VERSION ""

NS_ :

BS_:

BU_: ESP dSpaceBox CALTOOL HED
VAL_TABLE_ Vtsig_BCC_ERRORS 2 "STORED" 1 "ACTIVE" 0 "NOT_ACTIVE" ;
VAL_TABLE_ DefaultValue -1 "NO_CONTEXT" ;
VAL_TABLE_ Wakeup_Mode 1 "TRUE" 0 "FALSE" ;
VAL_TABLE_ SW_MODE 2 "Shutdown" 1 "Operational Mode" ;
VAL_TABLE_ Balancing_Active 1 "TRUE" 0 "FALSE" ;
VAL_TABLE_ Balancing_Enable 1 "TRUE" 0 "FALSE" ;
VAL_TABLE_ Balancing_Request 1 "ON" 0 "OFF" ;
VAL_TABLE_ Flash_Status 1 "FLASH MODE" 0 "NORMAL MODE" ;
VAL_TABLE_ Flash_Request 3 "EXIT" 2 "TRANSFER" 1 "START" 0 "NOT REQUESTED" ;
VAL_TABLE_ Function 1 "ENABLE" 0 "DISABLE" ;
VAL_TABLE_ Error 1 "ACTIVE" 0 "NOT ACTIVE" ;
VAL_TABLE_ Balancing_Status 3 "RESERVED" 2 "CHARGING" 1 "DISCHARGING" 0 "OFF" ;

BO_ 11 AI_SOC_ESP: 8 ESP
 SG_ AI_SOC_ESP : 0|16@1+ (0.01,0) [0|100] "%"  HED

BO_ 10 AI_SOH_ESP: 8 ESP
 SG_ AI_SOH_ESP : 0|16@1+ (0.01,0) [0|100] "%"  HED

BO_ 18 VCU_BatInfo_2: 8 HED
 SG_ Cell_Current : 0|16@1- (0.0005,0) [-16|16] "V"  dSpaceBox

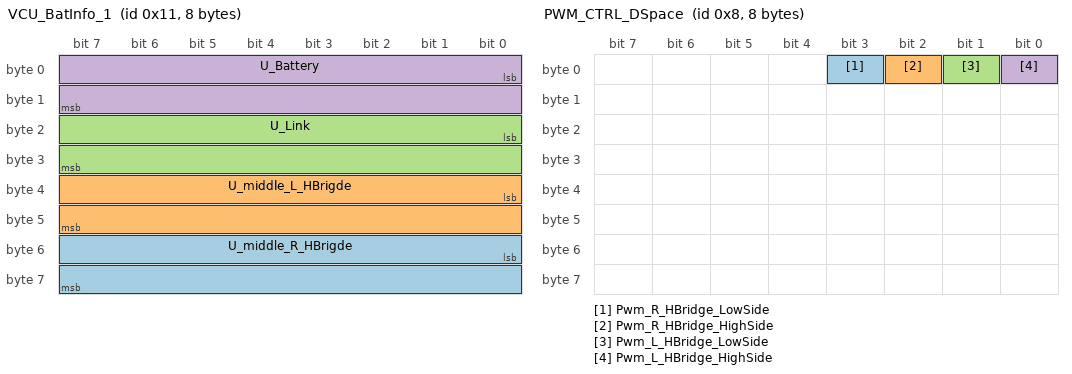
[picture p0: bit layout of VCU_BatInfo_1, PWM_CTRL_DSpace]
BO_ 17 VCU_BatInfo_1: 8 HED
 SG_ U_middle_R_HBrigde : 48|16@1+ (0.001,0) [0|15] "V"  dSpaceBox
 SG_ U_middle_L_HBrigde : 32|16@1+ (0.001,0) [0|15] "V"  dSpaceBox
 SG_ U_Link : 16|16@1+ (0.001,0) [0|15] "V"  dSpaceBox
 SG_ U_Battery : 0|16@1+ (0.001,0) [0|5] ""  dSpaceBox

BO_ 8 PWM_CTRL_DSpace: 8 dSpaceBox
 SG_ Pwm_R_HBridge_LowSide : 3|1@1+ (1,0) [0|1] ""  HED
 SG_ Pwm_R_HBridge_HighSide : 2|1@1+ (1,0) [0|1] ""  HED
 SG_ Pwm_L_HBridge_LowSide : 1|1@1+ (1,0) [0|1] ""  HED
 SG_ Pwm_L_HBridge_HighSide : 0|1@1+ (1,0) [0|1] ""  HED

BO_ 7 AI_SOH_SOC_TAB: 8 CALTOOL
 SG_ AI_SOH_TAB : 16|16@1+ (0.01,0) [0|100] "%"  HED
 SG_ AI_SOC_TAB : 0|16@1+ (0.01,0) [0|100] "%"  HED

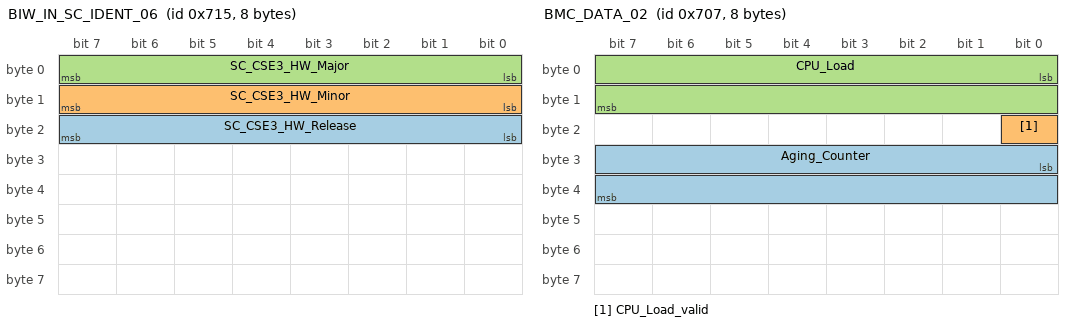
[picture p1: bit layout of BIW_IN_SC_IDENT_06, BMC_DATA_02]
BO_ 1813 BIW_IN_SC_IDENT_06: 8 HED
 SG_ SC_CSE3_HW_Release : 16|8@1+ (1,0) [0|254] ""  CALTOOL
 SG_ SC_CSE3_HW_Minor : 8|8@1+ (1,0) [0|254] ""  CALTOOL
 SG_ SC_CSE3_HW_Major : 0|8@1+ (1,0) [0|254] ""  CALTOOL

BO_ 528 BIW_IN_SC_ERRORS_11: 8 HED
 SG_ SC_ERR_Reserved_11_12 : 60|3@1+ (1,0) [0|0] ""  CALTOOL
 SG_ SC_ERR_Reserved_11_11 : 57|3@1+ (1,0) [0|0] ""  CALTOOL
 SG_ SC_ERR_Reserved_11_10 : 54|3@1+ (1,0) [0|0] ""  CALTOOL
 SG_ SC_ERR_Reserved_11_09 : 51|3@1+ (1,0) [0|0] ""  CALTOOL
 SG_ SC_ERR_Reserved_11_08 : 48|3@1+ (1,0) [0|0] ""  CALTOOL
 SG_ SC_ERR_Reserved_11_07 : 45|3@1+ (1,0) [0|0] ""  CALTOOL
 SG_ SC_ERR_Reserved_11_06 : 42|3@1+ (1,0) [0|0] ""  CALTOOL
 SG_ SC_ERR_Reserved_11_05 : 39|3@1+ (1,0) [0|0] ""  CALTOOL
 SG_ SC_ERR_Reserved_11_04 : 36|3@1+ (1,0) [0|0] ""  CALTOOL
 SG_ SC_ERR_Reserved_11_03 : 33|3@1+ (1,0) [0|0] ""  CALTOOL
 SG_ SC_ERR_Reserved_11_02 : 30|3@1+ (1,0) [0|0] ""  CALTOOL
 SG_ SC_ERR_Reserved_11_01 : 27|3@1+ (1,0) [0|0] ""  CALTOOL
 SG_ SC_ERR_CSE3_PCB_Temp2_RNGL : 24|3@1+ (1,0) [0|0] ""  CALTOOL
 SG_ SC_ERR_CSE3_PCB_Temp2_RNGH : 21|3@1+ (1,0) [0|0] ""  CALTOOL
 SG_ SC_ERR_CSE3_PCB_Temp2_High : 18|3@1+ (1,0) [0|0] ""  CALTOOL
 SG_ SC_ERR_CSE3_PCB_Temp1_RNGL : 15|3@1+ (1,0) [0|0] ""  CALTOOL
 SG_ SC_ERR_CSE3_PCB_Temp1_RNGH : 12|3@1+ (1,0) [0|0] ""  CALTOOL
 SG_ SC_ERR_CSE3_PCB_Temp1_High : 9|3@1+ (1,0) [0|0] ""  CALTOOL
 SG_ SC_ERR_CSE3_Fault_Line : 6|3@1+ (1,0) [0|0] ""  CALTOOL
 SG_ SC_ERR_CSE3_Daisy_Chain : 3|3@1+ (1,0) [0|0] ""  CALTOOL
 SG_ SC_ERR_CSE3_Com_TOut : 0|3@1+ (1,0) [0|0] ""  CALTOOL

BO_ 1799 BMC_DATA_02: 8 HED
 SG_ Aging_Counter : 24|16@1+ (1,0) [0|0] ""  CALTOOL
 SG_ CPU_Load_valid : 16|1@1+ (1,0) [0|0] ""  CALTOOL
 SG_ CPU_Load : 0|16@1+ (0.1,0) [0|0] "%"  CALTOOL

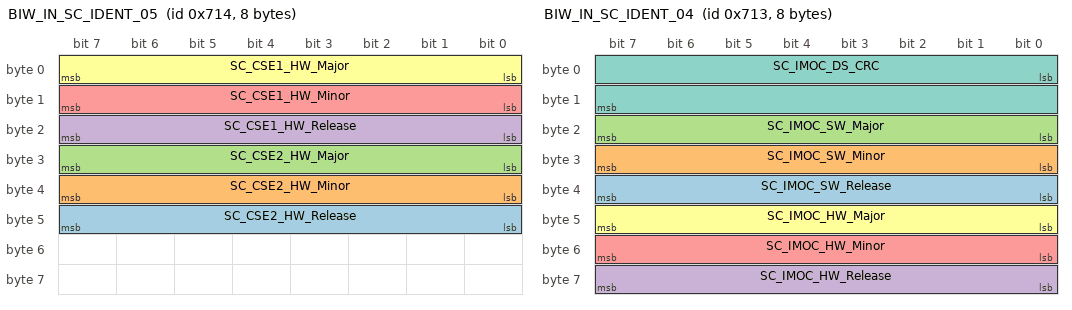
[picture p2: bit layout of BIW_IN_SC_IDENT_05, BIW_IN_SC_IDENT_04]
BO_ 1812 BIW_IN_SC_IDENT_05: 8 HED
 SG_ SC_CSE2_HW_Release : 40|8@1+ (1,0) [0|254] ""  CALTOOL
 SG_ SC_CSE2_HW_Minor : 32|8@1+ (1,0) [0|254] ""  CALTOOL
 SG_ SC_CSE2_HW_Major : 24|8@1+ (1,0) [0|254] ""  CALTOOL
 SG_ SC_CSE1_HW_Release : 16|8@1+ (1,0) [0|254] ""  CALTOOL
 SG_ SC_CSE1_HW_Minor : 8|8@1+ (1,0) [0|254] ""  CALTOOL
 SG_ SC_CSE1_HW_Major : 0|8@1+ (1,0) [0|254] ""  CALTOOL

BO_ 1811 BIW_IN_SC_IDENT_04: 8 HED
 SG_ SC_IMOC_SW_Release : 32|8@1+ (1,0) [0|255] ""  CALTOOL
 SG_ SC_IMOC_SW_Minor : 24|8@1+ (1,0) [0|255] ""  CALTOOL
 SG_ SC_IMOC_SW_Major : 16|8@1+ (1,0) [0|255] ""  CALTOOL
 SG_ SC_IMOC_HW_Release : 56|8@1+ (1,0) [0|254] ""  CALTOOL
 SG_ SC_IMOC_HW_Minor : 48|8@1+ (1,0) [0|254] ""  CALTOOL
 SG_ SC_IMOC_HW_Major : 40|8@1+ (1,0) [0|254] ""  CALTOOL
 SG_ SC_IMOC_DS_CRC : 0|16@1+ (1,0) [0|65534] ""  CALTOOL

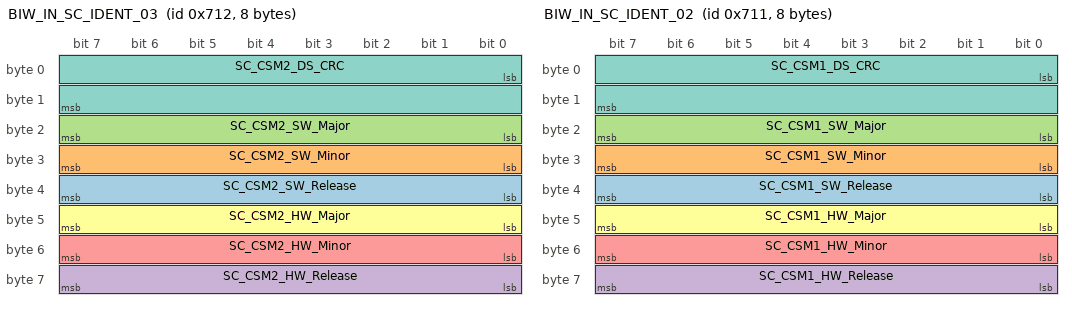
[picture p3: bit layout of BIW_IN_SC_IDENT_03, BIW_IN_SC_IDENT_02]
BO_ 1810 BIW_IN_SC_IDENT_03: 8 HED
 SG_ SC_CSM2_SW_Release : 32|8@1+ (1,0) [0|254] ""  CALTOOL
 SG_ SC_CSM2_SW_Minor : 24|8@1+ (1,0) [0|254] ""  CALTOOL
 SG_ SC_CSM2_SW_Major : 16|8@1+ (1,0) [0|254] ""  CALTOOL
 SG_ SC_CSM2_HW_Release : 56|8@1+ (1,0) [0|254] ""  CALTOOL
 SG_ SC_CSM2_HW_Minor : 48|8@1+ (1,0) [0|254] ""  CALTOOL
 SG_ SC_CSM2_HW_Major : 40|8@1+ (1,0) [0|254] ""  CALTOOL
 SG_ SC_CSM2_DS_CRC : 0|16@1+ (1,0) [0|65534] ""  CALTOOL

BO_ 1809 BIW_IN_SC_IDENT_02: 8 HED
 SG_ SC_CSM1_SW_Release : 32|8@1+ (1,0) [0|254] ""  CALTOOL
 SG_ SC_CSM1_SW_Minor : 24|8@1+ (1,0) [0|254] ""  CALTOOL
 SG_ SC_CSM1_SW_Major : 16|8@1+ (1,0) [0|254] ""  CALTOOL
 SG_ SC_CSM1_HW_Release : 56|8@1+ (1,0) [0|254] ""  CALTOOL
 SG_ SC_CSM1_HW_Minor : 48|8@1+ (1,0) [0|254] ""  CALTOOL
 SG_ SC_CSM1_HW_Major : 40|8@1+ (1,0) [0|254] ""  CALTOOL
 SG_ SC_CSM1_DS_CRC : 0|16@1+ (1,0) [0|65534] ""  CALTOOL

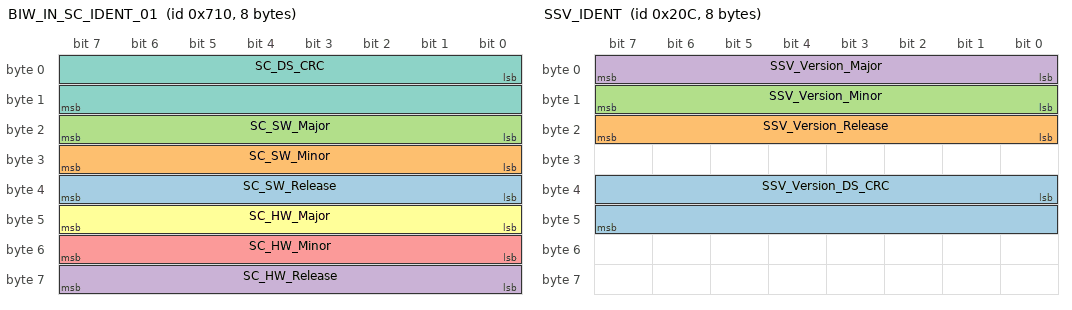
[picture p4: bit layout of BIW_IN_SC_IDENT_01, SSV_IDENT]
BO_ 1808 BIW_IN_SC_IDENT_01: 8 HED
 SG_ SC_SW_Release : 32|8@1+ (1,0) [0|255] ""  CALTOOL
 SG_ SC_SW_Minor : 24|8@1+ (1,0) [0|255] ""  CALTOOL
 SG_ SC_SW_Major : 16|8@1+ (1,0) [0|255] ""  CALTOOL
 SG_ SC_HW_Release : 56|8@1+ (1,0) [0|255] ""  CALTOOL
 SG_ SC_HW_Minor : 48|8@1+ (1,0) [0|255] ""  CALTOOL
 SG_ SC_HW_Major : 40|8@1+ (1,0) [0|255] ""  CALTOOL
 SG_ SC_DS_CRC : 0|16@1+ (1,0) [0|0] ""  CALTOOL

BO_ 521 BIW_IN_SC_ERRORS_10: 8 HED
 SG_ SC_ERR_Reserved_10_07 : 60|3@1+ (1,0) [0|0] ""  CALTOOL
 SG_ SC_ERR_Reserved_10_06 : 57|3@1+ (1,0) [0|0] ""  CALTOOL
 SG_ SC_ERR_Reserved_10_05 : 54|3@1+ (1,0) [0|0] ""  CALTOOL
 SG_ SC_ERR_Reserved_10_04 : 51|3@1+ (1,0) [0|0] ""  CALTOOL
 SG_ SC_ERR_Reserved_10_03 : 48|3@1+ (1,0) [0|0] ""  CALTOOL
 SG_ SC_ERR_Reserved_10_02 : 45|3@1+ (1,0) [0|0] ""  CALTOOL
 SG_ SC_ERR_Reserved_10_01 : 42|3@1+ (1,0) [0|0] ""  CALTOOL
 SG_ SC_ERR_FUSI_FSG_01 : 15|3@1+ (1,0) [0|0] ""  CALTOOL
 SG_ SC_ERR_FUSI_FSG_02 : 18|3@1+ (1,0) [0|0] ""  CALTOOL
 SG_ SC_ERR_FUSI_FSG_03 : 21|3@1+ (1,0) [0|0] ""  CALTOOL
 SG_ SC_ERR_FUSI_FSG_04 : 24|3@1+ (1,0) [0|0] ""  CALTOOL
 SG_ SC_ERR_FUSI_FSG_05 : 27|3@1+ (1,0) [0|0] ""  CALTOOL
 SG_ SC_ERR_FUSI_FSG_06 : 30|3@1+ (1,0) [0|0] ""  CALTOOL
 SG_ SC_ERR_FUSI_FSG_07 : 33|3@1+ (1,0) [0|0] ""  CALTOOL
 SG_ SC_ERR_FUSI_FSG_08 : 36|3@1+ (1,0) [0|0] ""  CALTOOL
 SG_ SC_ERR_FUSI_FSG_09 : 39|3@1+ (1,0) [0|0] ""  CALTOOL
 SG_ SC_ERR_SC_ROM : 12|3@1+ (1,0) [0|0] ""  CALTOOL
 SG_ SC_ERR_SC_RAM : 9|3@1+ (1,0) [0|0] ""  CALTOOL
 SG_ SC_ERR_SC_NVRAM : 6|3@1+ (1,0) [0|0] ""  CALTOOL
 SG_ SC_ERR_IMOC_ROM : 3|3@1+ (1,0) [0|0] ""  CALTOOL
 SG_ SC_ERR_IMOC_RAM : 0|3@1+ (1,0) [0|0] ""  CALTOOL

BO_ 520 BIW_IN_SC_ERRORS_09: 8 HED
 SG_ SC_ERR_Reserved_09_14 : 60|3@1+ (1,0) [0|0] ""  CALTOOL
 SG_ SC_ERR_Reserved_09_13 : 57|3@1+ (1,0) [0|0] ""  CALTOOL
 SG_ SC_ERR_Reserved_09_12 : 54|3@1+ (1,0) [0|0] ""  CALTOOL
 SG_ SC_ERR_Reserved_09_11 : 51|3@1+ (1,0) [0|0] ""  CALTOOL
 SG_ SC_ERR_Reserved_09_10 : 48|3@1+ (1,0) [0|0] ""  CALTOOL
 SG_ SC_ERR_Reserved_09_09 : 45|3@1+ (1,0) [0|0] ""  CALTOOL
 SG_ SC_ERR_Reserved_09_08 : 42|3@1+ (1,0) [0|0] ""  CALTOOL
 SG_ SC_ERR_Reserved_09_07 : 39|3@1+ (1,0) [0|0] ""  CALTOOL
 SG_ SC_ERR_Reserved_09_06 : 36|3@1+ (1,0) [0|0] ""  CALTOOL
 SG_ SC_ERR_Reserved_09_05 : 33|3@1+ (1,0) [0|0] ""  CALTOOL
 SG_ SC_ERR_Reserved_09_04 : 30|3@1+ (1,0) [0|0] ""  CALTOOL
 SG_ SC_ERR_Reserved_09_03 : 27|3@1+ (1,0) [0|0] ""  CALTOOL
 SG_ SC_ERR_Reserved_09_02 : 24|3@1+ (1,0) [0|0] ""  CALTOOL
 SG_ SC_ERR_Reserved_09_01 : 21|3@1+ (1,0) [0|0] ""  CALTOOL
 SG_ SC_ERR_ISO_Meas_Selftest : 18|3@1+ (1,0) [0|0] ""  CALTOOL
 SG_ SC_ERR_ISO_Int_Lvl3 : 15|3@1+ (1,0) [0|0] ""  CALTOOL
 SG_ SC_ERR_ISO_Int_Lvl2 : 12|3@1+ (1,0) [0|0] ""  CALTOOL
 SG_ SC_ERR_ISO_Int_Lvl1 : 9|3@1+ (1,0) [0|0] ""  CALTOOL
 SG_ SC_ERR_ISO_Ext_Lvl3 : 6|3@1+ (1,0) [0|0] ""  CALTOOL
 SG_ SC_ERR_ISO_Ext_Lvl2 : 3|3@1+ (1,0) [0|0] ""  CALTOOL
 SG_ SC_ERR_ISO_Ext_Lvl1 : 0|3@1+ (1,0) [0|0] ""  CALTOOL

BO_ 519 BIW_IN_SC_ERRORS_08: 8 HED
 SG_ SC_ERR_Reserved_08_02 : 60|3@1+ (1,0) [0|0] ""  CALTOOL
 SG_ SC_ERR_Reserved_08_01 : 57|3@1+ (1,0) [0|0] ""  CALTOOL
 SG_ SC_ERR_CAN_Sc_Meas_Busoff : 54|3@1+ (1,0) [0|0] ""  CALTOOL
 SG_ SC_ERR_CAN_Data_Busoff : 51|3@1+ (1,0) [0|0] ""  CALTOOL
 SG_ SC_ERR_CAN_PNHV_Stat_AR2_TOut : 48|3@1+ (1,0) [0|0] ""  CALTOOL
 SG_ SC_ERR_CAN_OBL_Rq_AR2_TOut : 42|3@1+ (1,0) [0|0] ""  CALTOOL
 SG_ SC_ERR_CAN_LBC_CANHS_R_03_TOut : 45|3@1+ (1,0) [0|0] ""  CALTOOL
 SG_ SC_ERR_CAN_LBC_CANHS_R_02_TOut : 39|3@1+ (1,0) [0|0] ""  CALTOOL
 SG_ SC_ERR_VCC3_Vltg_Low : 36|3@1+ (1,0) [0|0] ""  CALTOOL
 SG_ SC_ERR_VCC3_Vltg_High : 33|3@1+ (1,0) [0|0] ""  CALTOOL
 SG_ SC_ERR_VCC2_Vltg_Low : 30|3@1+ (1,0) [0|0] ""  CALTOOL
 SG_ SC_ERR_VCC2_Vltg_High : 27|3@1+ (1,0) [0|0] ""  CALTOOL
 SG_ SC_ERR_VCC1_Vltg_Low : 24|3@1+ (1,0) [0|0] ""  CALTOOL
 SG_ SC_ERR_VCC1_Vltg_High : 21|3@1+ (1,0) [0|0] ""  CALTOOL
 SG_ SC_ERR_KL30c_Vltg_Low : 18|3@1+ (1,0) [0|0] ""  CALTOOL
 SG_ SC_ERR_KL30c_Vltg_High : 15|3@1+ (1,0) [0|0] ""  CALTOOL
 SG_ SC_ERR_KL30c_Trgd : 12|3@1+ (1,0) [0|0] ""  CALTOOL
 SG_ SC_ERR_KL30_Vltg_Low : 9|3@1+ (1,0) [0|0] ""  CALTOOL
 SG_ SC_ERR_KL30_Vltg_High : 6|3@1+ (1,0) [0|0] ""  CALTOOL
 SG_ SC_ERR_KL15_Vltg_Plaus : 3|3@1+ (1,0) [0|0] ""  CALTOOL
 SG_ SC_ERR_KL15_Vltg_High : 0|3@1+ (1,0) [0|0] ""  CALTOOL

BO_ 518 BIW_IN_SC_ERRORS_07: 8 HED
 SG_ SC_ERR_Reserved_07_05 : 60|3@1+ (1,0) [0|0] ""  CALTOOL
 SG_ SC_ERR_Reserved_07_04 : 57|3@1+ (1,0) [0|0] ""  CALTOOL
 SG_ SC_ERR_Reserved_07_03 : 54|3@1+ (1,0) [0|0] ""  CALTOOL
 SG_ SC_ERR_Reserved_07_02 : 51|3@1+ (1,0) [0|0] ""  CALTOOL
 SG_ SC_ERR_Reserved_07_01 : 48|3@1+ (1,0) [0|0] ""  CALTOOL
 SG_ SC_ERR_INTLK2_OL : 45|3@1+ (1,0) [0|0] ""  CALTOOL
 SG_ SC_ERR_INTLK1_OL : 42|3@1+ (1,0) [0|0] ""  CALTOOL
 SG_ SC_ERR_INTLK2_Vcc_Low : 39|3@1+ (1,0) [0|0] ""  CALTOOL
 SG_ SC_ERR_INTLK2_Vcc_High : 36|3@1+ (1,0) [0|0] ""  CALTOOL
 SG_ SC_ERR_INTLK2_SCG : 33|3@1+ (1,0) [0|0] ""  CALTOOL
 SG_ SC_ERR_INTLK2_SCB : 30|3@1+ (1,0) [0|0] ""  CALTOOL
 SG_ SC_ERR_INTLK2_Gen_defect : 27|3@1+ (1,0) [0|0] ""  CALTOOL
 SG_ SC_ERR_INTLK2_Frequency : 24|3@1+ (1,0) [0|0] ""  CALTOOL
 SG_ SC_ERR_INTLK2_Duty_Cycle : 21|3@1+ (1,0) [0|0] ""  CALTOOL
 SG_ SC_ERR_INTLK1_Vcc_Low : 18|3@1+ (1,0) [0|0] ""  CALTOOL
 SG_ SC_ERR_INTLK1_Vcc_High : 15|3@1+ (1,0) [0|0] ""  CALTOOL
 SG_ SC_ERR_INTLK1_SCG : 12|3@1+ (1,0) [0|0] ""  CALTOOL
 SG_ SC_ERR_INTLK1_SCB : 9|3@1+ (1,0) [0|0] ""  CALTOOL
 SG_ SC_ERR_INTLK1_Gen_defect : 6|3@1+ (1,0) [0|0] ""  CALTOOL
 SG_ SC_ERR_INTLK1_Frequency : 3|3@1+ (1,0) [0|0] ""  CALTOOL
 SG_ SC_ERR_INTLK1_Duty_Cycle : 0|3@1+ (1,0) [0|0] ""  CALTOOL

BO_ 517 BIW_IN_SC_ERRORS_06: 8 HED
 SG_ SC_ERR_Reserved_06_03 : 57|3@1+ (1,0) [0|0] ""  CALTOOL
 SG_ SC_ERR_Reserved_06_02 : 54|3@1+ (1,0) [0|0] ""  CALTOOL
 SG_ SC_ERR_Reserved_06_01 : 51|3@1+ (1,0) [0|0] ""  CALTOOL
 SG_ SC_ERR_MSW_Pre_Temp : 48|3@1+ (1,0) [0|0] ""  CALTOOL
 SG_ SC_ERR_MSW_LnkVltg_High : 45|3@1+ (1,0) [0|0] ""  CALTOOL
 SG_ SC_ERR_MSW_Vltg_Diff : 42|3@1+ (1,0) [0|0] ""  CALTOOL
 SG_ SC_ERR_MSW_Pre_Time : 39|3@1+ (1,0) [0|0] ""  CALTOOL
 SG_ SC_ERR_MSW_Pre_Crnt : 36|3@1+ (1,0) [0|0] ""  CALTOOL
 SG_ SC_ERR_MSW_Pre_Stuck_Opn : 33|3@1+ (1,0) [0|0] ""  CALTOOL
 SG_ SC_ERR_MSW_Pre_Stuck_Cls : 30|3@1+ (1,0) [0|0] ""  CALTOOL
 SG_ SC_ERR_MSW_Plus_Stuck_Opn : 27|3@1+ (1,0) [0|0] ""  CALTOOL
 SG_ SC_ERR_MSW_Plus_Stuck_Cls : 24|3@1+ (1,0) [0|0] ""  CALTOOL
 SG_ SC_ERR_MSW_Minus_Stuck_Opn : 21|3@1+ (1,0) [0|0] ""  CALTOOL
 SG_ SC_ERR_MSW_Minus_Stuck_Cls : 18|3@1+ (1,0) [0|0] ""  CALTOOL
 SG_ SC_ERR_MSW_Pre_Ls_SCG : 15|3@1+ (1,0) [0|0] ""  CALTOOL
 SG_ SC_ERR_MSW_Pre_Ls_SCB : 12|3@1+ (1,0) [0|0] ""  CALTOOL
 SG_ SC_ERR_MSW_Pre_Ls_OL : 9|3@1+ (1,0) [0|0] ""  CALTOOL
 SG_ SC_ERR_MSW_Pre_Hs_SCG : 6|3@1+ (1,0) [0|0] ""  CALTOOL
 SG_ SC_ERR_MSW_Pre_Hs_SCB : 3|3@1+ (1,0) [0|0] ""  CALTOOL
 SG_ SC_ERR_MSW_Pre_Hs_OL : 0|3@1+ (1,0) [0|0] ""  CALTOOL

BO_ 516 BIW_IN_SC_ERRORS_05: 8 HED
 SG_ SC_ERR_Reserved_05_03 : 60|3@1+ (1,0) [0|0] ""  CALTOOL
 SG_ SC_ERR_Reserved_05_02 : 57|3@1+ (1,0) [0|0] ""  CALTOOL
 SG_ SC_ERR_Reserved_05_01 : 54|3@1+ (1,0) [0|0] ""  CALTOOL
 SG_ SC_ERR_MSW_Plus_Ls_SCG : 51|3@1+ (1,0) [0|0] ""  CALTOOL
 SG_ SC_ERR_MSW_Plus_Ls_SCB : 48|3@1+ (1,0) [0|0] ""  CALTOOL
 SG_ SC_ERR_MSW_Plus_Ls_OL : 39|3@1+ (1,0) [0|0] ""  CALTOOL
 SG_ SC_ERR_MSW_Plus_Hs_SCG : 18|3@1+ (1,0) [0|0] ""  CALTOOL
 SG_ SC_ERR_MSW_Plus_Hs_SCB : 45|3@1+ (1,0) [0|0] ""  CALTOOL
 SG_ SC_ERR_MSW_Plus_Hs_OL : 42|3@1+ (1,0) [0|0] ""  CALTOOL
 SG_ SC_ERR_MSW_Minus_Ls_SCG : 36|3@1+ (1,0) [0|0] ""  CALTOOL
 SG_ SC_ERR_MSW_Minus_Ls_SCB : 33|3@1+ (1,0) [0|0] ""  CALTOOL
 SG_ SC_ERR_MSW_Minus_Ls_OL : 30|3@1+ (1,0) [0|0] ""  CALTOOL
 SG_ SC_ERR_MSW_Minus_Hs_SCG : 27|3@1+ (1,0) [0|0] ""  CALTOOL
 SG_ SC_ERR_MSW_Minus_Hs_SCB : 24|3@1+ (1,0) [0|0] ""  CALTOOL
 SG_ SC_ERR_MSW_Minus_Hs_OL : 21|3@1+ (1,0) [0|0] ""  CALTOOL
 SG_ SC_ERR_MSW_Aging_Pre_Warn : 15|3@1+ (1,0) [0|0] ""  CALTOOL
 SG_ SC_ERR_MSW_Aging_Pre : 12|3@1+ (1,0) [0|0] ""  CALTOOL
 SG_ SC_ERR_MSW_Aging_Plus_Warn : 9|3@1+ (1,0) [0|0] ""  CALTOOL
 SG_ SC_ERR_MSW_Aging_Plus : 6|3@1+ (1,0) [0|0] ""  CALTOOL
 SG_ SC_ERR_MSW_Aging_Minus_Warn : 3|3@1+ (1,0) [0|0] ""  CALTOOL
 SG_ SC_ERR_MSW_Aging_Minus : 0|3@1+ (1,0) [0|0] ""  CALTOOL

BO_ 515 BIW_IN_SC_ERRORS_04: 8 HED
 SG_ SC_ERR_Reserved_04_03 : 60|3@1+ (1,0) [0|0] ""  CALTOOL
 SG_ SC_ERR_Reserved_04_02 : 57|3@1+ (1,0) [0|0] ""  CALTOOL
 SG_ SC_ERR_Reserved_04_01 : 54|3@1+ (1,0) [0|0] ""  CALTOOL
 SG_ SC_ERR_CSE1_PCB_Temp2_High : 24|3@1+ (1,0) [0|0] ""  CALTOOL
 SG_ SC_ERR_CSE2_PCB_Temp2_RNGL : 48|3@1+ (1,0) [0|0] ""  CALTOOL
 SG_ SC_ERR_CSE2_PCB_Temp2_RNGH : 51|3@1+ (1,0) [0|0] ""  CALTOOL
 SG_ SC_ERR_CSE2_PCB_Temp2_High : 45|3@1+ (1,0) [0|0] ""  CALTOOL
 SG_ SC_ERR_CSE2_PCB_Temp1_RNGL : 42|3@1+ (1,0) [0|0] ""  CALTOOL
 SG_ SC_ERR_CSE2_PCB_Temp1_RNGH : 39|3@1+ (1,0) [0|0] ""  CALTOOL
 SG_ SC_ERR_CSE2_PCB_Temp1_High : 36|3@1+ (1,0) [0|0] ""  CALTOOL
 SG_ SC_ERR_CSE2_Fault_Line : 33|3@1+ (1,0) [0|0] ""  CALTOOL
 SG_ SC_ERR_CSE2_Daisy_Chain : 30|3@1+ (1,0) [0|0] ""  CALTOOL
 SG_ SC_ERR_CSE2_Com_TOut : 27|3@1+ (1,0) [0|0] ""  CALTOOL
 SG_ SC_ERR_CSE1_PCB_Temp2_RNGL : 21|3@1+ (1,0) [0|0] ""  CALTOOL
 SG_ SC_ERR_CSE1_PCB_Temp2_RNGH : 18|3@1+ (1,0) [0|0] ""  CALTOOL
 SG_ SC_ERR_CSE1_PCB_Temp1_RNGL : 15|3@1+ (1,0) [0|0] ""  CALTOOL
 SG_ SC_ERR_CSE1_PCB_Temp1_RNGH : 12|3@1+ (1,0) [0|0] ""  CALTOOL
 SG_ SC_ERR_CSE1_PCB_Temp1_High : 9|3@1+ (1,0) [0|0] ""  CALTOOL
 SG_ SC_ERR_CSE1_Fault_Line : 6|3@1+ (1,0) [0|0] ""  CALTOOL
 SG_ SC_ERR_CSE1_Daisy_Chain : 3|3@1+ (1,0) [0|0] ""  CALTOOL
 SG_ SC_ERR_CSE1_Com_TOut : 0|3@1+ (1,0) [0|0] ""  CALTOOL

BO_ 514 BIW_IN_SC_ERRORS_03: 8 HED
 SG_ SC_ERR_FUSE1_Pack_RNGL : 9|3@1+ (1,0) [0|0] ""  CALTOOL
 SG_ SC_ERR_FUSE1_Pack_RNGH : 12|3@1+ (1,0) [0|0] ""  CALTOOL
 SG_ SC_ERR_FUSE1_Pack_OL : 3|3@1+ (1,0) [0|0] ""  CALTOOL
 SG_ SC_ERR_FUSE1_Link_RNGL : 15|3@1+ (1,0) [0|0] ""  CALTOOL
 SG_ SC_ERR_FUSE1_Link_RNGH : 18|3@1+ (1,0) [0|0] ""  CALTOOL
 SG_ SC_ERR_FUSE1_Link_OL : 6|3@1+ (1,0) [0|0] ""  CALTOOL
 SG_ SC_ERR_FUSE1_Blown : 0|3@1+ (1,0) [0|0] ""  CALTOOL
 SG_ SC_ERR_PCK_Vltg_RNGL : 45|3@1+ (1,0) [0|0] ""  CALTOOL
 SG_ SC_ERR_PCK_Vltg_RNGH : 48|3@1+ (1,0) [0|0] ""  CALTOOL
 SG_ SC_ERR_PCK_Vltg_Plaus : 51|3@1+ (1,0) [0|0] ""  CALTOOL
 SG_ SC_ERR_PCK_Vltg_OL : 54|3@1+ (1,0) [0|0] ""  CALTOOL
 SG_ SC_ERR_LNK_Vltg_RNGL : 57|3@1+ (1,0) [0|0] ""  CALTOOL
 SG_ SC_ERR_LNK_Vltg_RNGH : 60|3@1+ (1,0) [0|0] ""  CALTOOL
 SG_ SC_ERR_LNK_Vltg_OL : 42|3@1+ (1,0) [0|0] ""  CALTOOL
 SG_ SC_ERR_FUSE2_Pack_RNGL : 30|3@1+ (1,0) [0|0] ""  CALTOOL
 SG_ SC_ERR_FUSE2_Pack_RNGH : 33|3@1+ (1,0) [0|0] ""  CALTOOL
 SG_ SC_ERR_FUSE2_Pack_OL : 24|3@1+ (1,0) [0|0] ""  CALTOOL
 SG_ SC_ERR_FUSE2_Link_RNGL : 36|3@1+ (1,0) [0|0] ""  CALTOOL
 SG_ SC_ERR_FUSE2_Link_RNGH : 39|3@1+ (1,0) [0|0] ""  CALTOOL
 SG_ SC_ERR_FUSE2_Link_OL : 27|3@1+ (1,0) [0|0] ""  CALTOOL
 SG_ SC_ERR_FUSE2_Blown : 21|3@1+ (1,0) [0|0] ""  CALTOOL

BO_ 513 BIW_IN_SC_ERRORS_02: 8 HED
 SG_ SC_ERR_Reserved_02_04 : 60|3@1+ (1,0) [0|0] ""  CALTOOL
 SG_ SC_ERR_Reserved_02_03 : 57|3@1+ (1,0) [0|0] ""  CALTOOL
 SG_ SC_ERR_Reserved_02_02 : 54|3@1+ (1,0) [0|0] ""  CALTOOL
 SG_ SC_ERR_Reserved_02_01 : 51|3@1+ (1,0) [0|0] ""  CALTOOL
 SG_ SC_ERR_CSM1_Temp_High : 15|3@1+ (1,0) [0|0] ""  CALTOOL
 SG_ SC_ERR_CSM1_ROM : 42|3@1+ (1,0) [0|0] ""  CALTOOL
 SG_ SC_ERR_CSM1_FUSI_CrntDischrgHigh : 12|3@1+ (1,0) [0|0] ""  CALTOOL
 SG_ SC_ERR_CSM1_FUSI_Crnt_Chrg_High : 9|3@1+ (1,0) [0|0] ""  CALTOOL
 SG_ SC_ERR_CSM1_Crnt_Dischrg_RNGL : 6|3@1+ (1,0) [0|0] ""  CALTOOL
 SG_ SC_ERR_CSM1_Crnt_Chrg_RNGH : 3|3@1+ (1,0) [0|0] ""  CALTOOL
 SG_ SC_ERR_CSM1_Com_TOut : 0|3@1+ (1,0) [0|0] ""  CALTOOL
 SG_ SC_ERR_CSM_Plaus : 21|3@1+ (1,0) [0|0] ""  CALTOOL
 SG_ SC_ERR_CSM1_General : 18|3@1+ (1,0) [0|0] ""  CALTOOL
 SG_ SC_ERR_CSM2_SCG : 30|3@1+ (1,0) [0|0] ""  CALTOOL
 SG_ SC_ERR_CSM2_SCB : 39|3@1+ (1,0) [0|0] ""  CALTOOL
 SG_ SC_ERR_CSM2_ROM : 24|3@1+ (1,0) [0|0] ""  CALTOOL
 SG_ SC_ERR_CSM2_OL : 33|3@1+ (1,0) [0|0] ""  CALTOOL
 SG_ SC_ERR_CSM2_FUSI_CrntDischrgHigh : 27|3@1+ (1,0) [0|0] ""  CALTOOL
 SG_ SC_ERR_CSM2_FUSI_Crnt_Chrg_High : 48|3@1+ (1,0) [0|0] ""  CALTOOL
 SG_ SC_ERR_CSM2_Crnt_Dischrg_RNGL : 36|3@1+ (1,0) [0|0] ""  CALTOOL
 SG_ SC_ERR_CSM2_Crnt_Chrg_RNGH : 45|3@1+ (1,0) [0|0] ""  CALTOOL

BO_ 512 BIW_IN_SC_ERRORS_01: 8 HED
 SG_ SC_ERR_CELLBLOCK3_Modul_Vltg_RAT : 60|3@1+ (1,0) [0|0] ""  CALTOOL
 SG_ SC_ERR_CELLBLOCK2_Modul_Vltg_RAT : 57|3@1+ (1,0) [0|0] ""  CALTOOL
 SG_ SC_ERR_CELLBLOCK1_Modul_Vltg_RAT : 54|3@1+ (1,0) [0|0] ""  CALTOOL
 SG_ SC_ERR_CELLBLOCK3_UnderVltg_Warn : 51|3@1+ (1,0) [0|0] ""  CALTOOL
 SG_ SC_ERR_CELLBLOCK2_UnderVltg_Warn : 48|3@1+ (1,0) [0|0] ""  CALTOOL
 SG_ SC_ERR_CELLBLOCK1_UnderVltg_Warn : 45|3@1+ (1,0) [0|0] ""  CALTOOL
 SG_ SC_ERR_CELLBLOCK3_OverVltg_Warn : 42|3@1+ (1,0) [0|0] ""  CALTOOL
 SG_ SC_ERR_CELLBLOCK2_OverVltg_Warn : 39|3@1+ (1,0) [0|0] ""  CALTOOL
 SG_ SC_ERR_CELLBLOCK1_OverVltg_Warn : 36|3@1+ (1,0) [0|0] ""  CALTOOL
 SG_ SC_ERR_CELLBLOCK3_FUSI_UnderVltg : 33|3@1+ (1,0) [0|0] ""  CALTOOL
 SG_ SC_ERR_CELLBLOCK2_FUSI_UnderVltg : 30|3@1+ (1,0) [0|0] ""  CALTOOL
 SG_ SC_ERR_CELLBLOCK1_FUSI_UnderVltg : 27|3@1+ (1,0) [0|0] ""  CALTOOL
 SG_ SC_ERR_CELLBLOCK3_FUSI_OverVltg : 24|3@1+ (1,0) [0|0] ""  CALTOOL
 SG_ SC_ERR_CELLBLOCK2_FUSI_OverVltg : 21|3@1+ (1,0) [0|0] ""  CALTOOL
 SG_ SC_ERR_CELLBLOCK1_FUSI_OverVltg : 18|3@1+ (1,0) [0|0] ""  CALTOOL
 SG_ SC_ERR_CELLBLOCK3_FUSI_OverTemp : 15|3@1+ (1,0) [0|0] ""  CALTOOL
 SG_ SC_ERR_CELLBLOCK2_FUSI_OverTemp : 12|3@1+ (1,0) [0|0] ""  CALTOOL
 SG_ SC_ERR_CELLBLOCK1_FUSI_OverTemp : 9|3@1+ (1,0) [0|0] ""  CALTOOL
 SG_ SC_ERR_CELLBLOCK3_FUSI_Open_Line : 6|3@1+ (1,0) [0|0] ""  CALTOOL
 SG_ SC_ERR_CELLBLOCK2_FUSI_Open_Line : 3|3@1+ (1,0) [0|0] ""  CALTOOL
 SG_ SC_ERR_CELLBLOCK1_FUSI_Open_Line : 0|3@1+ (1,0) [0|0] ""  CALTOOL

BO_ 321 BCC_IN_T_BATT_29_30: 8 HED
 SG_ BCC_T_Batt_30 : 32|16@1- (0.01,0) [-327.68|327.67] "°C"  CALTOOL
 SG_ BCC_T_Batt_29 : 0|16@1- (0.01,0) [-327.68|327.67] "°C"  CALTOOL

BO_ 320 BCC_IN_T_BATT_27_28: 8 HED
 SG_ BCC_T_Batt_28 : 32|16@1- (0.01,0) [-327.68|327.67] "°C"  CALTOOL
 SG_ BCC_T_Batt_27 : 0|16@1- (0.01,0) [-327.68|327.67] "°C"  CALTOOL

BO_ 319 BCC_IN_T_BATT_25_26: 8 HED
 SG_ BCC_T_Batt_26 : 32|16@1- (0.01,0) [-327.68|327.67] "°C"  CALTOOL
 SG_ BCC_T_Batt_25 : 0|16@1- (0.01,0) [-327.68|327.67] "°C"  CALTOOL

BO_ 318 BCC_IN_T_BATT_23_24: 8 HED
 SG_ BCC_T_Batt_24 : 32|16@1- (0.01,0) [-327.68|327.67] "°C"  CALTOOL
 SG_ BCC_T_Batt_23 : 0|16@1- (0.01,0) [-327.68|327.67] "°C"  CALTOOL

BO_ 317 BCC_IN_T_BATT_21_22: 8 HED
 SG_ BCC_T_Batt_22 : 32|16@1- (0.01,0) [-327.68|327.67] "°C"  CALTOOL
 SG_ BCC_T_Batt_21 : 0|16@1- (0.01,0) [-327.68|327.67] "°C"  CALTOOL

BO_ 316 BCC_IN_T_BATT_19_20: 8 HED
 SG_ BCC_T_Batt_20 : 32|16@1- (0.01,0) [-327.68|327.67] "°C"  CALTOOL
 SG_ BCC_T_Batt_19 : 0|16@1- (0.01,0) [-327.68|327.67] "°C"  CALTOOL

BO_ 315 BCC_IN_T_BATT_17_18: 8 HED
 SG_ BCC_T_Batt_18 : 32|16@1- (0.01,0) [-327.68|327.67] "°C"  CALTOOL
 SG_ BCC_T_Batt_17 : 0|16@1- (0.01,0) [-327.68|327.67] "°C"  CALTOOL

BO_ 314 BCC_IN_T_BATT_15_16: 8 HED
 SG_ BCC_T_Batt_16 : 32|16@1- (0.01,0) [-327.68|327.67] "°C"  CALTOOL
 SG_ BCC_T_Batt_15 : 0|16@1- (0.01,0) [-327.68|327.67] "°C"  CALTOOL

BO_ 313 BCC_IN_T_BATT_13_14: 8 HED
 SG_ BCC_T_Batt_14 : 32|16@1- (0.01,0) [-327.68|327.67] "°C"  CALTOOL
 SG_ BCC_T_Batt_13 : 0|16@1- (0.01,0) [-327.68|327.67] "°C"  CALTOOL

BO_ 312 BCC_IN_T_BATT_11_12: 8 HED
 SG_ BCC_T_Batt_12 : 32|16@1- (0.01,0) [-327.68|327.67] "°C"  CALTOOL
 SG_ BCC_T_Batt_11 : 0|16@1- (0.01,0) [-327.68|327.67] "°C"  CALTOOL

BO_ 524 SSV_IDENT: 8 HED
 SG_ SSV_Version_DS_CRC : 32|16@1+ (1,0) [0|65535] ""  CALTOOL
 SG_ SSV_Version_Release : 16|8@1+ (1,0) [0|255] ""  CALTOOL
 SG_ SSV_Version_Minor : 8|8@1+ (1,0) [0|255] ""  CALTOOL
 SG_ SSV_Version_Major : 0|8@1+ (1,0) [0|255] ""  CALTOOL

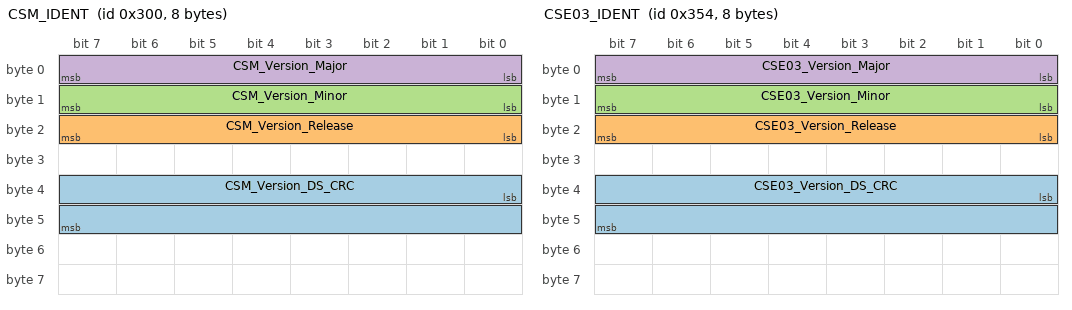
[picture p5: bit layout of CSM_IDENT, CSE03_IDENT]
BO_ 768 CSM_IDENT: 8 HED
 SG_ CSM_Version_DS_CRC : 32|16@1+ (1,0) [0|65535] ""  CALTOOL
 SG_ CSM_Version_Release : 16|8@1+ (1,0) [0|255] ""  CALTOOL
 SG_ CSM_Version_Minor : 8|8@1+ (1,0) [0|255] ""  CALTOOL
 SG_ CSM_Version_Major : 0|8@1+ (1,0) [0|255] ""  CALTOOL

BO_ 852 CSE03_IDENT: 8 HED
 SG_ CSE03_Version_DS_CRC : 32|16@1+ (1,0) [0|65535] ""  CALTOOL
 SG_ CSE03_Version_Release : 16|8@1+ (1,0) [0|255] ""  CALTOOL
 SG_ CSE03_Version_Minor : 8|8@1+ (1,0) [0|255] ""  CALTOOL
 SG_ CSE03_Version_Major : 0|8@1+ (1,0) [0|255] ""  CALTOOL

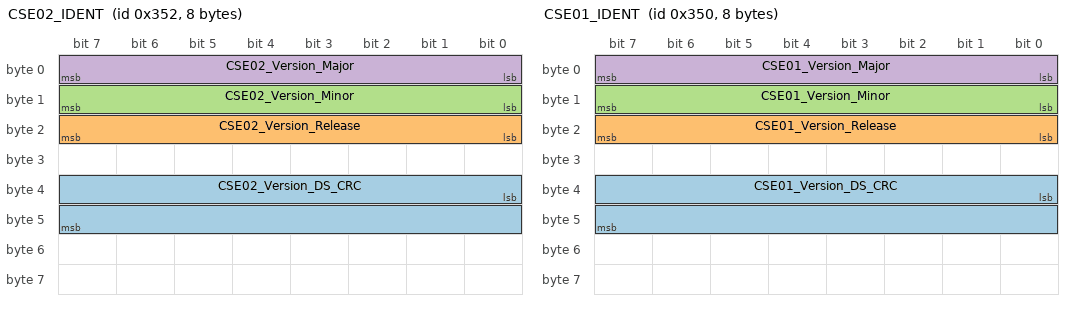
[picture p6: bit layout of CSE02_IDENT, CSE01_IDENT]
BO_ 850 CSE02_IDENT: 8 HED
 SG_ CSE02_Version_DS_CRC : 32|16@1+ (1,0) [0|65535] ""  CALTOOL
 SG_ CSE02_Version_Release : 16|8@1+ (1,0) [0|255] ""  CALTOOL
 SG_ CSE02_Version_Minor : 8|8@1+ (1,0) [0|255] ""  CALTOOL
 SG_ CSE02_Version_Major : 0|8@1+ (1,0) [0|255] ""  CALTOOL

BO_ 848 CSE01_IDENT: 8 HED
 SG_ CSE01_Version_DS_CRC : 32|16@1+ (1,0) [0|65535] ""  CALTOOL
 SG_ CSE01_Version_Release : 16|8@1+ (1,0) [0|255] ""  CALTOOL
 SG_ CSE01_Version_Minor : 8|8@1+ (1,0) [0|255] ""  CALTOOL
 SG_ CSE01_Version_Major : 0|8@1+ (1,0) [0|255] ""  CALTOOL

BO_ 311 BCC_IN_T_BATT_09_10: 8 HED
 SG_ BCC_T_Batt_10 : 32|16@1- (0.01,0) [-327.68|327.67] "°C"  CALTOOL
 SG_ BCC_T_Batt_09 : 0|16@1- (0.01,0) [-327.68|327.67] "°C"  CALTOOL

BO_ 310 BCC_IN_T_BATT_07_08: 8 HED
 SG_ BCC_T_Batt_08 : 32|16@1- (0.01,0) [-327.68|327.67] "°C"  CALTOOL
 SG_ BCC_T_Batt_07 : 0|16@1- (0.01,0) [-327.68|327.67] "°C"  CALTOOL

BO_ 853 CSE03_ERRORS: 8 HED
 SG_ CSE03_E_063 : 63|1@1+ (1,0) [0|0] ""  CALTOOL
 SG_ CSE03_E_062 : 62|1@1+ (1,0) [0|0] ""  CALTOOL
 SG_ CSE03_E_061 : 61|1@1+ (1,0) [0|0] ""  CALTOOL
 SG_ CSE03_E_060 : 60|1@1+ (1,0) [0|0] ""  CALTOOL
 SG_ CSE03_E_059 : 59|1@1+ (1,0) [0|0] ""  CALTOOL
 SG_ CSE03_E_058 : 58|1@1+ (1,0) [0|0] ""  CALTOOL
 SG_ CSE03_E_057 : 57|1@1+ (1,0) [0|0] ""  CALTOOL
 SG_ CSE03_E_056_FST_ROM : 56|1@1+ (1,0) [0|0] ""  CALTOOL
 SG_ CSE03_E_055_FST_RAM_SECTION_2 : 55|1@1+ (1,0) [0|0] ""  CALTOOL
 SG_ CSE03_E_054_FST_RAM_SECTION_1 : 54|1@1+ (1,0) [0|0] ""  CALTOOL
 SG_ CSE03_E_053_FST_RAM_STARTUP : 53|1@1+ (1,0) [0|0] ""  CALTOOL
 SG_ CSE03_E_052_FST_CPU : 52|1@1+ (1,0) [0|0] ""  CALTOOL
 SG_ CSE03_E_051_FST_RESET : 51|1@1+ (1,0) [0|0] ""  CALTOOL
 SG_ CSE03_E_050_FST_INTERRUPT : 50|1@1+ (1,0) [0|0] ""  CALTOOL
 SG_ CSE03_E_049_FST_STACK : 49|1@1+ (1,0) [0|0] ""  CALTOOL
 SG_ CSE03_E_048_FST_LTC6801 : 48|1@1+ (1,0) [0|0] ""  CALTOOL
 SG_ CSE03_E_047 : 47|1@1+ (1,0) [0|0] ""  CALTOOL
 SG_ CSE03_E_046 : 46|1@1+ (1,0) [0|0] ""  CALTOOL
 SG_ CSE03_E_045 : 45|1@1+ (1,0) [0|0] ""  CALTOOL
 SG_ CSE03_E_044_CAN_SEND_SEQ : 44|1@1+ (1,0) [0|0] ""  CALTOOL
 SG_ CSE03_E_043_CAN_BUFFER_FULL : 43|1@1+ (1,0) [0|0] ""  CALTOOL
 SG_ CSE03_E_042 : 42|1@1+ (1,0) [0|0] ""  CALTOOL
 SG_ CSE03_E_041 : 41|1@1+ (1,0) [0|0] ""  CALTOOL
 SG_ CSE03_E_040_FLASH_READ_PROD : 40|1@1+ (1,0) [0|0] ""  CALTOOL
 SG_ CSE03_E_039_FLASH_CRC_PROD : 39|1@1+ (1,0) [0|0] ""  CALTOOL
 SG_ CSE03_E_038_FLASH_READ_CAN : 38|1@1+ (1,0) [0|0] ""  CALTOOL
 SG_ CSE03_E_037_FLASH_CRC_CAN : 37|1@1+ (1,0) [0|0] ""  CALTOOL
 SG_ CSE03_E_036 : 36|1@1+ (1,0) [0|0] ""  CALTOOL
 SG_ CSE03_E_035 : 35|1@1+ (1,0) [0|0] ""  CALTOOL
 SG_ CSE03_E_034_SYS_DATASET : 34|1@1+ (1,0) [0|0] ""  CALTOOL
 SG_ CSE03_E_033_SYS_DATASET_WARN : 33|1@1+ (1,0) [0|0] ""  CALTOOL
 SG_ CSE03_E_032_SYS_TASK_TIME : 32|1@1+ (1,0) [0|0] ""  CALTOOL
 SG_ CSE03_E_031_SYS_DIFF_ZERO : 31|1@1+ (1,0) [0|0] ""  CALTOOL
 SG_ CSE03_E_030_SYS_SWITCH_DEF : 30|1@1+ (1,0) [0|0] ""  CALTOOL
 SG_ CSE03_E_029_SYS_GENERAL : 29|1@1+ (1,0) [0|0] ""  CALTOOL
 SG_ CSE03_E_028 : 28|1@1+ (1,0) [0|0] ""  CALTOOL
 SG_ CSE03_E_027_BAL_CONTACT_RES : 27|1@1+ (1,0) [0|0] ""  CALTOOL
 SG_ CSE03_E_026_BAL_THRESHOLD : 26|1@1+ (1,0) [0|0] ""  CALTOOL
 SG_ CSE03_E_025_BAL_COMPARE_CFRG : 25|1@1+ (1,0) [0|0] ""  CALTOOL
 SG_ CSE03_E_024_BAL_WRITE_CFRG : 24|1@1+ (1,0) [0|0] ""  CALTOOL
 SG_ CSE03_E_023_MEAS_REF_TEMP : 23|1@1+ (1,0) [0|0] ""  CALTOOL
 SG_ CSE03_E_022_MEAS_REF_VOLT : 22|1@1+ (1,0) [0|0] ""  CALTOOL
 SG_ CSE03_E_021_MEAS_TEMP_TIMEOUT : 21|1@1+ (1,0) [0|0] ""  CALTOOL
 SG_ CSE03_E_020_MEAS_VOLT_TIMEOUT : 20|1@1+ (1,0) [0|0] ""  CALTOOL
 SG_ CSE03_E_019_MEAS_TEMP_SEQ : 19|1@1+ (1,0) [0|0] ""  CALTOOL
 SG_ CSE03_E_018_MEAS_VOLT_SEQ : 18|1@1+ (1,0) [0|0] ""  CALTOOL
 SG_ CSE03_E_017_MEAS_SET_CONFIG : 17|1@1+ (1,0) [0|0] ""  CALTOOL
 SG_ CSE03_E_016_MEAS_START_VOLT : 16|1@1+ (1,0) [0|0] ""  CALTOOL
 SG_ CSE03_E_015_MEAS_START_TEMP : 15|1@1+ (1,0) [0|0] ""  CALTOOL
 SG_ CSE03_E_014_MEAS_READ_VOLT : 14|1@1+ (1,0) [0|0] ""  CALTOOL
 SG_ CSE03_E_013_MEAS_READ_TEMP : 13|1@1+ (1,0) [0|0] ""  CALTOOL
 SG_ CSE03_E_012_MEAS_INIT : 12|1@1+ (1,0) [0|0] ""  CALTOOL
 SG_ CSE03_E_011 : 11|1@1+ (1,0) [0|0] ""  CALTOOL
 SG_ CSE03_E_010 : 10|1@1+ (1,0) [0|0] ""  CALTOOL
 SG_ CSE03_E_009 : 9|1@1+ (1,0) [0|0] ""  CALTOOL
 SG_ CSE03_E_008_LIM_CONTACT_RES : 8|1@1+ (1,0) [0|0] ""  CALTOOL
 SG_ CSE03_E_007_LIM_OVERTEMP_PCB : 7|1@1+ (1,0) [0|0] ""  CALTOOL
 SG_ CSE03_E_006_LIM_UNDERTEMP : 6|1@1+ (1,0) [0|0] ""  CALTOOL
 SG_ CSE03_E_005_LIM_OVERTEMP : 5|1@1+ (1,0) [0|0] ""  CALTOOL
 SG_ CSE03_E_004_LIM_UNDERVOLT : 4|1@1+ (1,0) [0|0] ""  CALTOOL
 SG_ CSE03_E_003_LIM_OVERVOLT : 3|1@1+ (1,0) [0|0] ""  CALTOOL
 SG_ CSE03_E_002_ARTICLE_NUMBER : 2|1@1+ (1,0) [0|0] ""  CALTOOL
 SG_ CSE03_E_001_EMERGENCY_LINE : 1|1@1+ (1,0) [0|0] ""  CALTOOL
 SG_ CSE03_E_FLAG : 0|1@1+ (1,0) [0|0] ""  CALTOOL

BO_ 769 CSM_ERRORS: 8 HED
 SG_ CSM_E_EEPROM_READ_WRITE : 58|1@1+ (1,0) [0|0] ""  CALTOOL
 SG_ CSM_E_MSW_AGE_ERR : 57|1@1+ (1,0) [0|0] ""  CALTOOL
 SG_ CSM_E_MSW_AGE_WARN : 56|1@1+ (1,0) [0|0] ""  CALTOOL
 SG_ CSM_E_BROKEN_WIRE : 55|1@1+ (1,0) [0|0] ""  CALTOOL
 SG_ CSM_E_U_REF : 54|1@1+ (1,0) [0|0] ""  CALTOOL
 SG_ CSM_E_CPU_MONITOR : 53|1@1+ (1,0) [0|0] ""  CALTOOL
 SG_ CSM_E_ROM_MONITOR : 52|1@1+ (1,0) [0|0] ""  CALTOOL
 SG_ CSM_E_RAM_MONITOR : 51|1@1+ (1,0) [0|0] ""  CALTOOL
 SG_ CSM_E_STACK_MONITOR : 50|1@1+ (1,0) [0|0] ""  CALTOOL
 SG_ CSM_E_RESET_MONITOR : 49|1@1+ (1,0) [0|0] ""  CALTOOL
 SG_ CSM_E_INTERRUPT_MONITOR : 48|1@1+ (1,0) [0|0] ""  CALTOOL
 SG_ CSM_E_UBAT_COMPARE_IHM_UC : 47|1@1+ (1,0) [0|0] ""  CALTOOL
 SG_ CSM_E_SEND_CAN : 46|1@1+ (1,0) [0|0] ""  CALTOOL
 SG_ CSM_E_CAN_ERROR_ID : 45|1@1+ (1,0) [0|0] ""  CALTOOL
 SG_ CSM_E_TASK_TIME : 44|1@1+ (1,0) [0|0] ""  CALTOOL
 SG_ CSM_E_I_OCD_DISCHARGE_OOR : 42|1@1+ (1,0) [0|0] ""  CALTOOL
 SG_ CSM_E_I_OCD_CHARGE_OOR : 43|1@1+ (1,0) [0|0] ""  CALTOOL
 SG_ CSM_E_TEMPERATURE_MIN : 41|1@1+ (1,0) [0|0] ""  CALTOOL
 SG_ CSM_E_TEMPERATURE_MAX : 40|1@1+ (1,0) [0|0] ""  CALTOOL
 SG_ CSM_E_VOLTAGE_TRAC_N_MIN : 39|1@1+ (1,0) [0|0] ""  CALTOOL
 SG_ CSM_E_VOLTAGE_TRAC_N_MAX : 38|1@1+ (1,0) [0|0] ""  CALTOOL
 SG_ CSM_E_VOLTAGE_TRAC_P_MIN : 37|1@1+ (1,0) [0|0] ""  CALTOOL
 SG_ CSM_E_VOLTAGE_TRAC_P_MAX : 36|1@1+ (1,0) [0|0] ""  CALTOOL
 SG_ CSM_E_VOLTAGE_BAT_MIN : 35|1@1+ (1,0) [0|0] ""  CALTOOL
 SG_ CSM_E_VOLTAGE_BAT_MAX : 34|1@1+ (1,0) [0|0] ""  CALTOOL
 SG_ CSM_E_CURRENT_DISCHARGE_MAX : 33|1@1+ (1,0) [0|0] ""  CALTOOL
 SG_ CSM_E_CURRENT_CHARGE_MAX : 32|1@1+ (1,0) [0|0] ""  CALTOOL
 SG_ CSM_E_MEAS_TEMPINT_OUFLOW : 31|1@1+ (1,0) [0|0] ""  CALTOOL
 SG_ CSM_E_MEAS_U_TRAC_N_OUFLOW : 30|1@1+ (1,0) [0|0] ""  CALTOOL
 SG_ CSM_E_MEAS_U_TRAC_P_OUFLOW : 29|1@1+ (1,0) [0|0] ""  CALTOOL
 SG_ CSM_E_MEAS_U_BAT_OUFLOW : 28|1@1+ (1,0) [0|0] ""  CALTOOL
 SG_ CSM_E_MEAS_CURRENT_OUFLOW : 27|1@1+ (1,0) [0|0] ""  CALTOOL
 SG_ CSM_E_FLASH_CRC_DATARECORD_B : 26|1@1+ (1,0) [0|0] ""  CALTOOL
 SG_ CSM_E_FLASH_CRC_DATARECORD_A : 25|1@1+ (1,0) [0|0] ""  CALTOOL
 SG_ CSM_E_FLASH_WRITE_CALIB_PARA : 24|1@1+ (1,0) [0|0] ""  CALTOOL
 SG_ CSM_E_FLASH_READ_CALIB_PARA : 23|1@1+ (1,0) [0|0] ""  CALTOOL
 SG_ CSM_E_FLASH_CRC_CALIB_PARA : 22|1@1+ (1,0) [0|0] ""  CALTOOL
 SG_ CSM_E_FLASH_WRITE_IHM_PARA : 21|1@1+ (1,0) [0|0] ""  CALTOOL
 SG_ CSM_E_FLASH_READ_IHM_PARA : 20|1@1+ (1,0) [0|0] ""  CALTOOL
 SG_ CSM_E_FLASH_CRC_IHM_PARA : 19|1@1+ (1,0) [0|0] ""  CALTOOL
 SG_ CSM_E_FLASH_WRITE_PROD_DATA : 18|1@1+ (1,0) [0|0] ""  CALTOOL
 SG_ CSM_E_FLASH_READ_PROD_DATA : 17|1@1+ (1,0) [0|0] ""  CALTOOL
 SG_ CSM_E_FLASH_CRC_PROD_DATA : 16|1@1+ (1,0) [0|0] ""  CALTOOL
 SG_ CSM_E_FLASH_WRITE_CAN_PARA : 15|1@1+ (1,0) [0|0] ""  CALTOOL
 SG_ CSM_E_FLASH_READ_CAN_PARA : 14|1@1+ (1,0) [0|0] ""  CALTOOL
 SG_ CSM_E_FLASH_CRC_CAN_PARA : 13|1@1+ (1,0) [0|0] ""  CALTOOL
 SG_ CSM_E_IHM_INIT_CRA : 12|1@1+ (1,0) [0|0] ""  CALTOOL
 SG_ CSM_E_IHM_INIT_CRG : 11|1@1+ (1,0) [0|0] ""  CALTOOL
 SG_ CSM_E_IHM_INIT_TRR : 10|1@1+ (1,0) [0|0] ""  CALTOOL
 SG_ CSM_E_IHM_INIT_CAR : 9|1@1+ (1,0) [0|0] ""  CALTOOL
 SG_ CSM_E_IHM_INIT_OPM : 8|1@1+ (1,0) [0|0] ""  CALTOOL
 SG_ CSM_E_OCD : 1|1@1+ (1,0) [0|0] ""  CALTOOL
 SG_ CSM_E_IHM_ZZR_CHECK : 7|1@1+ (1,0) [0|0] ""  CALTOOL
 SG_ CSM_E_IHM_TRR_CHECK : 6|1@1+ (1,0) [0|0] ""  CALTOOL
 SG_ CSM_E_IHM_CAR_CHECK : 5|1@1+ (1,0) [0|0] ""  CALTOOL
 SG_ CSM_E_SYS_GENERAL : 4|1@1+ (1,0) [0|0] ""  CALTOOL
 SG_ CSM_E_WRONG_DATARECORD : 3|1@1+ (1,0) [0|0] ""  CALTOOL
 SG_ CSM_E_WRONG_ARTICLE_NUMBER : 2|1@1+ (1,0) [0|0] ""  CALTOOL
 SG_ CSM_E_063 : 63|1@1+ (1,0) [0|0] ""  CALTOOL
 SG_ CSM_E_062 : 62|1@1+ (1,0) [0|0] ""  CALTOOL
 SG_ CSM_E_061 : 61|1@1+ (1,0) [0|0] ""  CALTOOL
 SG_ CSM_E_060 : 60|1@1+ (1,0) [0|0] ""  CALTOOL
 SG_ CSM_E_059 : 59|1@1+ (1,0) [0|0] ""  CALTOOL
 SG_ CSM_E_FLAG : 0|1@1+ (1,0) [0|0] ""  CALTOOL

BO_ 851 CSE02_ERRORS: 8 HED
 SG_ CSE02_E_063 : 63|1@1+ (1,0) [0|0] ""  CALTOOL
 SG_ CSE02_E_062 : 62|1@1+ (1,0) [0|0] ""  CALTOOL
 SG_ CSE02_E_061 : 61|1@1+ (1,0) [0|0] ""  CALTOOL
 SG_ CSE02_E_060 : 60|1@1+ (1,0) [0|0] ""  CALTOOL
 SG_ CSE02_E_059 : 59|1@1+ (1,0) [0|0] ""  CALTOOL
 SG_ CSE02_E_058 : 58|1@1+ (1,0) [0|0] ""  CALTOOL
 SG_ CSE02_E_057 : 57|1@1+ (1,0) [0|0] ""  CALTOOL
 SG_ CSE02_E_056_FST_ROM : 56|1@1+ (1,0) [0|0] ""  CALTOOL
 SG_ CSE02_E_055_FST_RAM_SECTION_2 : 55|1@1+ (1,0) [0|0] ""  CALTOOL
 SG_ CSE02_E_054_FST_RAM_SECTION_1 : 54|1@1+ (1,0) [0|0] ""  CALTOOL
 SG_ CSE02_E_053_FST_RAM_STARTUP : 53|1@1+ (1,0) [0|0] ""  CALTOOL
 SG_ CSE02_E_052_FST_CPU : 52|1@1+ (1,0) [0|0] ""  CALTOOL
 SG_ CSE02_E_051_FST_RESET : 51|1@1+ (1,0) [0|0] ""  CALTOOL
 SG_ CSE02_E_050_FST_INTERRUPT : 50|1@1+ (1,0) [0|0] ""  CALTOOL
 SG_ CSE02_E_049_FST_STACK : 49|1@1+ (1,0) [0|0] ""  CALTOOL
 SG_ CSE02_E_048_FST_LTC6801 : 48|1@1+ (1,0) [0|0] ""  CALTOOL
 SG_ CSE02_E_047 : 47|1@1+ (1,0) [0|0] ""  CALTOOL
 SG_ CSE02_E_046 : 46|1@1+ (1,0) [0|0] ""  CALTOOL
 SG_ CSE02_E_045 : 45|1@1+ (1,0) [0|0] ""  CALTOOL
 SG_ CSE02_E_044_CAN_SEND_SEQ : 44|1@1+ (1,0) [0|0] ""  CALTOOL
 SG_ CSE02_E_043_CAN_BUFFER_FULL : 43|1@1+ (1,0) [0|0] ""  CALTOOL
 SG_ CSE02_E_042 : 42|1@1+ (1,0) [0|0] ""  CALTOOL
 SG_ CSE02_E_041 : 41|1@1+ (1,0) [0|0] ""  CALTOOL
 SG_ CSE02_E_040_FLASH_READ_PROD : 40|1@1+ (1,0) [0|0] ""  CALTOOL
 SG_ CSE02_E_039_FLASH_CRC_PROD : 39|1@1+ (1,0) [0|0] ""  CALTOOL
 SG_ CSE02_E_038_FLASH_READ_CAN : 38|1@1+ (1,0) [0|0] ""  CALTOOL
 SG_ CSE02_E_037_FLASH_CRC_CAN : 37|1@1+ (1,0) [0|0] ""  CALTOOL
 SG_ CSE02_E_036 : 36|1@1+ (1,0) [0|0] ""  CALTOOL
 SG_ CSE02_E_035 : 35|1@1+ (1,0) [0|0] ""  CALTOOL
 SG_ CSE02_E_034_SYS_DATASET : 34|1@1+ (1,0) [0|0] ""  CALTOOL
 SG_ CSE02_E_033_SYS_DATASET_WARN : 33|1@1+ (1,0) [0|0] ""  CALTOOL
 SG_ CSE02_E_032_SYS_TASK_TIME : 32|1@1+ (1,0) [0|0] ""  CALTOOL
 SG_ CSE02_E_031_SYS_DIFF_ZERO : 31|1@1+ (1,0) [0|0] ""  CALTOOL
 SG_ CSE02_E_030_SYS_SWITCH_DEF : 30|1@1+ (1,0) [0|0] ""  CALTOOL
 SG_ CSE02_E_029_SYS_GENERAL : 29|1@1+ (1,0) [0|0] ""  CALTOOL
 SG_ CSE02_E_028 : 28|1@1+ (1,0) [0|0] ""  CALTOOL
 SG_ CSE02_E_027_BAL_CONTACT_RES : 27|1@1+ (1,0) [0|0] ""  CALTOOL
 SG_ CSE02_E_026_BAL_THRESHOLD : 26|1@1+ (1,0) [0|0] ""  CALTOOL
 SG_ CSE02_E_025_BAL_COMPARE_CFRG : 25|1@1+ (1,0) [0|0] ""  CALTOOL
 SG_ CSE02_E_024_BAL_WRITE_CFRG : 24|1@1+ (1,0) [0|0] ""  CALTOOL
 SG_ CSE02_E_023_MEAS_REF_TEMP : 23|1@1+ (1,0) [0|0] ""  CALTOOL
 SG_ CSE02_E_022_MEAS_REF_VOLT : 22|1@1+ (1,0) [0|0] ""  CALTOOL
 SG_ CSE02_E_021_MEAS_TEMP_TIMEOUT : 21|1@1+ (1,0) [0|0] ""  CALTOOL
 SG_ CSE02_E_020_MEAS_VOLT_TIMEOUT : 20|1@1+ (1,0) [0|0] ""  CALTOOL
 SG_ CSE02_E_019_MEAS_TEMP_SEQ : 19|1@1+ (1,0) [0|0] ""  CALTOOL
 SG_ CSE02_E_018_MEAS_VOLT_SEQ : 18|1@1+ (1,0) [0|0] ""  CALTOOL
 SG_ CSE02_E_017_MEAS_SET_CONFIG : 17|1@1+ (1,0) [0|0] ""  CALTOOL
 SG_ CSE02_E_016_MEAS_START_VOLT : 16|1@1+ (1,0) [0|0] ""  CALTOOL
 SG_ CSE02_E_015_MEAS_START_TEMP : 15|1@1+ (1,0) [0|0] ""  CALTOOL
 SG_ CSE02_E_014_MEAS_READ_VOLT : 14|1@1+ (1,0) [0|0] ""  CALTOOL
 SG_ CSE02_E_013_MEAS_READ_TEMP : 13|1@1+ (1,0) [0|0] ""  CALTOOL
 SG_ CSE02_E_012_MEAS_INIT : 12|1@1+ (1,0) [0|0] ""  CALTOOL
 SG_ CSE02_E_011 : 11|1@1+ (1,0) [0|0] ""  CALTOOL
 SG_ CSE02_E_010 : 10|1@1+ (1,0) [0|0] ""  CALTOOL
 SG_ CSE02_E_009 : 9|1@1+ (1,0) [0|0] ""  CALTOOL
 SG_ CSE02_E_008_LIM_CONTACT_RES : 8|1@1+ (1,0) [0|0] ""  CALTOOL
 SG_ CSE02_E_007_LIM_OVERTEMP_PCB : 7|1@1+ (1,0) [0|0] ""  CALTOOL
 SG_ CSE02_E_006_LIM_UNDERTEMP : 6|1@1+ (1,0) [0|0] ""  CALTOOL
 SG_ CSE02_E_005_LIM_OVERTEMP : 5|1@1+ (1,0) [0|0] ""  CALTOOL
 SG_ CSE02_E_004_LIM_UNDERVOLT : 4|1@1+ (1,0) [0|0] ""  CALTOOL
 SG_ CSE02_E_003_LIM_OVERVOLT : 3|1@1+ (1,0) [0|0] ""  CALTOOL
 SG_ CSE02_E_002_ARTICLE_NUMBER : 2|1@1+ (1,0) [0|0] ""  CALTOOL
 SG_ CSE02_E_001_EMERGENCY_LINE : 1|1@1+ (1,0) [0|0] ""  CALTOOL
 SG_ CSE02_E_FLAG : 0|1@1+ (1,0) [0|0] ""  CALTOOL

BO_ 849 CSE01_ERRORS: 8 HED
 SG_ CSE01_E_063 : 63|1@1+ (1,0) [0|0] ""  CALTOOL
 SG_ CSE01_E_062 : 62|1@1+ (1,0) [0|0] ""  CALTOOL
 SG_ CSE01_E_061 : 61|1@1+ (1,0) [0|0] ""  CALTOOL
 SG_ CSE01_E_060 : 60|1@1+ (1,0) [0|0] ""  CALTOOL
 SG_ CSE01_E_059 : 59|1@1+ (1,0) [0|0] ""  CALTOOL
 SG_ CSE01_E_058 : 58|1@1+ (1,0) [0|0] ""  CALTOOL
 SG_ CSE01_E_057 : 57|1@1+ (1,0) [0|0] ""  CALTOOL
 SG_ CSE01_E_056_FST_ROM : 56|1@1+ (1,0) [0|0] ""  CALTOOL
 SG_ CSE01_E_055_FST_RAM_SECTION_2 : 55|1@1+ (1,0) [0|0] ""  CALTOOL
 SG_ CSE01_E_054_FST_RAM_SECTION_1 : 54|1@1+ (1,0) [0|0] ""  CALTOOL
 SG_ CSE01_E_053_FST_RAM_STARTUP : 53|1@1+ (1,0) [0|0] ""  CALTOOL
 SG_ CSE01_E_052_FST_CPU : 52|1@1+ (1,0) [0|0] ""  CALTOOL
 SG_ CSE01_E_051_FST_RESET : 51|1@1+ (1,0) [0|0] ""  CALTOOL
 SG_ CSE01_E_050_FST_INTERRUPT : 50|1@1+ (1,0) [0|0] ""  CALTOOL
 SG_ CSE01_E_049_FST_STACK : 49|1@1+ (1,0) [0|0] ""  CALTOOL
 SG_ CSE01_E_048_FST_LTC6801 : 48|1@1+ (1,0) [0|0] ""  CALTOOL
 SG_ CSE01_E_047 : 47|1@1+ (1,0) [0|0] ""  CALTOOL
 SG_ CSE01_E_046 : 46|1@1+ (1,0) [0|0] ""  CALTOOL
 SG_ CSE01_E_045 : 45|1@1+ (1,0) [0|0] ""  CALTOOL
 SG_ CSE01_E_044_CAN_SEND_SEQ : 44|1@1+ (1,0) [0|0] ""  CALTOOL
 SG_ CSE01_E_043_CAN_BUFFER_FULL : 43|1@1+ (1,0) [0|0] ""  CALTOOL
 SG_ CSE01_E_042 : 42|1@1+ (1,0) [0|0] ""  CALTOOL
 SG_ CSE01_E_041 : 41|1@1+ (1,0) [0|0] ""  CALTOOL
 SG_ CSE01_E_040_FLASH_READ_PROD : 40|1@1+ (1,0) [0|0] ""  CALTOOL
 SG_ CSE01_E_039_FLASH_CRC_PROD : 39|1@1+ (1,0) [0|0] ""  CALTOOL
 SG_ CSE01_E_038_FLASH_READ_CAN : 38|1@1+ (1,0) [0|0] ""  CALTOOL
 SG_ CSE01_E_037_FLASH_CRC_CAN : 37|1@1+ (1,0) [0|0] ""  CALTOOL
 SG_ CSE01_E_036 : 36|1@1+ (1,0) [0|0] ""  CALTOOL
 SG_ CSE01_E_035 : 35|1@1+ (1,0) [0|0] ""  CALTOOL
 SG_ CSE01_E_034_SYS_DATASET : 34|1@1+ (1,0) [0|0] ""  CALTOOL
 SG_ CSE01_E_033_SYS_DATASET_WARN : 33|1@1+ (1,0) [0|0] ""  CALTOOL
 SG_ CSE01_E_032_SYS_TASK_TIME : 32|1@1+ (1,0) [0|0] ""  CALTOOL
 SG_ CSE01_E_031_SYS_DIFF_ZERO : 31|1@1+ (1,0) [0|0] ""  CALTOOL
 SG_ CSE01_E_030_SYS_SWITCH_DEF : 30|1@1+ (1,0) [0|0] ""  CALTOOL
 SG_ CSE01_E_029_SYS_GENERAL : 29|1@1+ (1,0) [0|0] ""  CALTOOL
 SG_ CSE01_E_028 : 28|1@1+ (1,0) [0|0] ""  CALTOOL
 SG_ CSE01_E_027_BAL_CONTACT_RES : 27|1@1+ (1,0) [0|0] ""  CALTOOL
 SG_ CSE01_E_026_BAL_THRESHOLD : 26|1@1+ (1,0) [0|0] ""  CALTOOL
 SG_ CSE01_E_025_BAL_COMPARE_CFRG : 25|1@1+ (1,0) [0|0] ""  CALTOOL
 SG_ CSE01_E_024_BAL_WRITE_CFRG : 24|1@1+ (1,0) [0|0] ""  CALTOOL
 SG_ CSE01_E_023_MEAS_REF_TEMP : 23|1@1+ (1,0) [0|0] ""  CALTOOL
 SG_ CSE01_E_022_MEAS_REF_VOLT : 22|1@1+ (1,0) [0|0] ""  CALTOOL
 SG_ CSE01_E_021_MEAS_TEMP_TIMEOUT : 21|1@1+ (1,0) [0|0] ""  CALTOOL
 SG_ CSE01_E_020_MEAS_VOLT_TIMEOUT : 20|1@1+ (1,0) [0|0] ""  CALTOOL
 SG_ CSE01_E_019_MEAS_TEMP_SEQ : 19|1@1+ (1,0) [0|0] ""  CALTOOL
 SG_ CSE01_E_018_MEAS_VOLT_SEQ : 18|1@1+ (1,0) [0|0] ""  CALTOOL
 SG_ CSE01_E_017_MEAS_SET_CONFIG : 17|1@1+ (1,0) [0|0] ""  CALTOOL
 SG_ CSE01_E_016_MEAS_START_VOLT : 16|1@1+ (1,0) [0|0] ""  CALTOOL
 SG_ CSE01_E_015_MEAS_START_TEMP : 15|1@1+ (1,0) [0|0] ""  CALTOOL
 SG_ CSE01_E_014_MEAS_READ_VOLT : 14|1@1+ (1,0) [0|0] ""  CALTOOL
 SG_ CSE01_E_013_MEAS_READ_TEMP : 13|1@1+ (1,0) [0|0] ""  CALTOOL
 SG_ CSE01_E_012_MEAS_INIT : 12|1@1+ (1,0) [0|0] ""  CALTOOL
 SG_ CSE01_E_011 : 11|1@1+ (1,0) [0|0] ""  CALTOOL
 SG_ CSE01_E_010 : 10|1@1+ (1,0) [0|0] ""  CALTOOL
 SG_ CSE01_E_009 : 9|1@1+ (1,0) [0|0] ""  CALTOOL
 SG_ CSE01_E_FLAG : 0|1@1+ (1,0) [0|0] ""  CALTOOL
 SG_ CSE01_E_008_LIM_CONTACT_RES : 8|1@1+ (1,0) [0|0] ""  CALTOOL
 SG_ CSE01_E_007_LIM_OVERTEMP_PCB : 7|1@1+ (1,0) [0|0] ""  CALTOOL
 SG_ CSE01_E_006_LIM_UNDERTEMP : 6|1@1+ (1,0) [0|0] ""  CALTOOL
 SG_ CSE01_E_005_LIM_OVERTEMP : 5|1@1+ (1,0) [0|0] ""  CALTOOL
 SG_ CSE01_E_004_LIM_UNDERVOLT : 4|1@1+ (1,0) [0|0] ""  CALTOOL
 SG_ CSE01_E_003_LIM_OVERVOLT : 3|1@1+ (1,0) [0|0] ""  CALTOOL
 SG_ CSE01_E_002_ARTICLE_NUMBER : 2|1@1+ (1,0) [0|0] ""  CALTOOL
 SG_ CSE01_E_001_EMERGENCY_LINE : 1|1@1+ (1,0) [0|0] ""  CALTOOL

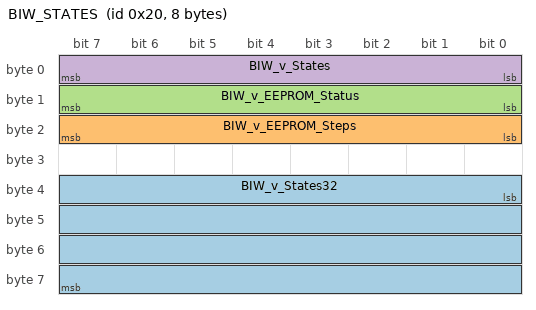
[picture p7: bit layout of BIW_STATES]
BO_ 32 BIW_STATES: 8 HED
 SG_ BIW_v_States32 : 32|32@1+ (1,0) [0|0] ""  CALTOOL
 SG_ BIW_v_EEPROM_Steps : 16|8@1+ (1,0) [0|0] ""  CALTOOL
 SG_ BIW_v_EEPROM_Status : 8|8@1+ (1,0) [0|0] ""  CALTOOL
 SG_ BIW_v_States : 0|8@1+ (1,0) [0|0] ""  CALTOOL

BO_ 555 SAC_ERRORS_2: 8 HED
 SG_ SAC_E_Timer_Management : 50|1@1+ (1,0) [0|1] ""  CALTOOL
 SG_ SAC_E_Task_System : 51|1@1+ (1,0) [0|1] ""  CALTOOL
 SG_ SAC_E_Startup_Test : 31|1@1+ (1,0) [0|1] ""  CALTOOL
 SG_ SAC_E_SSV_Sys_WD_Test : 23|1@1+ (1,0) [0|1] ""  CALTOOL
 SG_ SAC_E_SSV_Startup_Test : 30|1@1+ (1,0) [0|1] ""  CALTOOL
 SG_ SAC_E_SSV_Ref_Voltage : 56|1@1+ (1,0) [0|1] ""  CALTOOL
 SG_ SAC_E_SSV_DS_Interop : 57|1@1+ (1,0) [0|1] ""  CALTOOL
 SG_ SAC_E_SSV_Alive_Test : 17|1@1+ (1,0) [0|1] ""  CALTOOL
 SG_ SAC_E_SPI_COM : 58|1@1+ (1,0) [0|1] ""  CALTOOL
 SG_ SAC_E_RTC : 39|1@1+ (1,0) [0|1] ""  CALTOOL
 SG_ SAC_E_Precharge2_power : 49|1@1+ (1,0) [0|1] ""  CALTOOL
 SG_ SAC_E_Precharge2_diag : 48|1@1+ (1,0) [0|1] ""  CALTOOL
 SG_ SAC_E_Precharge1_power : 40|1@1+ (1,0) [0|1] ""  CALTOOL
 SG_ SAC_E_Precharge1_diag : 41|1@1+ (1,0) [0|1] ""  CALTOOL
 SG_ SAC_E_PMB_OVERCURRENT_PRECH : 61|1@1+ (1,0) [0|1] ""  CALTOOL
 SG_ SAC_E_PMB_Interop : 18|1@1+ (1,0) [0|1] ""  CALTOOL
 SG_ SAC_E_PMB_Emergency_Test : 21|1@1+ (1,0) [0|1] ""  CALTOOL
 SG_ SAC_E_PMB_DS_Interop : 36|1@1+ (1,0) [0|1] ""  CALTOOL
 SG_ SAC_E_MSW_stuck_Test : 32|1@1+ (1,0) [0|1] ""  CALTOOL
 SG_ SAC_E_MSW_plus_stuck : 44|1@1+ (1,0) [0|1] ""  CALTOOL
 SG_ SAC_E_MSW_plus_control : 34|1@1+ (1,0) [0|1] ""  CALTOOL
 SG_ SAC_E_MSW_minus_stuck : 43|1@1+ (1,0) [0|1] ""  CALTOOL
 SG_ SAC_E_MSW_minus_control : 33|1@1+ (1,0) [0|1] ""  CALTOOL
 SG_ SAC_E_MSW_3_stuck : 45|1@1+ (1,0) [0|1] ""  CALTOOL
 SG_ SAC_E_MSW_3_control : 35|1@1+ (1,0) [0|1] ""  CALTOOL
 SG_ SAC_E_MC_WD : 42|1@1+ (1,0) [0|1] ""  CALTOOL
 SG_ SAC_E_KL30c_Test : 22|1@1+ (1,0) [0|1] ""  CALTOOL
 SG_ SAC_E_ISO_SHORT : 38|1@1+ (1,0) [0|1] ""  CALTOOL
 SG_ SAC_E_Internal : 37|1@1+ (1,0) [0|1] ""  CALTOOL
 SG_ SAC_E_Interlock_Test : 20|1@1+ (1,0) [0|1] ""  CALTOOL
 SG_ SAC_E_Dataset_Conf : 26|1@1+ (1,0) [0|1] ""  CALTOOL
 SG_ SAC_E_Dataset : 28|1@1+ (1,0) [0|1] ""  CALTOOL
 SG_ SAC_E_CSC_Limits : 16|1@1+ (1,0) [0|1] ""  CALTOOL
 SG_ SAC_E_CSC_Interop : 19|1@1+ (1,0) [0|1] ""  CALTOOL
 SG_ SAC_E_CSC_Emergency_Test : 55|1@1+ (1,0) [0|1] ""  CALTOOL
 SG_ SAC_E_CSC_DS_Interop : 29|1@1+ (1,0) [0|1] ""  CALTOOL
 SG_ SAC_E_crash : 24|1@1+ (1,0) [0|1] ""  CALTOOL
 SG_ SAC_E_CELL_UNDERVOLT_WARN : 60|1@1+ (1,0) [0|1] ""  CALTOOL
 SG_ SAC_E_CELL_OVERVOLT_WARN : 59|1@1+ (1,0) [0|1] ""  CALTOOL
 SG_ SAC_E_BSC_Operation_9D23H : 52|1@1+ (1,0) [0|1] ""  CALTOOL
 SG_ SAC_E_BSC_Operation_10D : 53|1@1+ (1,0) [0|1] ""  CALTOOL
 SG_ SAC_E_ADC : 27|1@1+ (1,0) [0|1] ""  CALTOOL
 SG_ SAC_E_ACC_Emergency_Test : 25|1@1+ (1,0) [0|1] ""  CALTOOL

CM_ SG_ 1799 CPU_Load_valid "CPU load information";
CM_ SG_ 1799 CPU_Load "CPU load information";
CM_ BO_ 1809 "Command to MC to reset in FBL mode";
CM_ BO_ 520 "Error State of SC monitorings";
CM_ BO_ 519 "Error State of SC monitorings";
CM_ BO_ 518 "Error State of SC monitorings";
CM_ BO_ 517 "Error State of SC monitorings";
CM_ SG_ 517 SC_ERR_MSW_Pre_Time "This signal shows the state of precharging time monitoring.";
CM_ SG_ 517 SC_ERR_MSW_Pre_Stuck_Cls "This signal shows the state of precharging contactor stuck closed monitoring.";
CM_ SG_ 517 SC_ERR_MSW_Plus_Stuck_Opn "This signal shows the state of HV+ contactor stuck open monitoring.";
CM_ SG_ 517 SC_ERR_MSW_Plus_Stuck_Cls "This signal shows the state of HV+ contactor stuck closed monitoring.";
CM_ SG_ 517 SC_ERR_MSW_Minus_Stuck_Opn "This signal shows the state of HV- contactor stuck open monitoring.";
CM_ SG_ 517 SC_ERR_MSW_Minus_Stuck_Cls "This signal shows the state of HV- contactor stuck closed monitoring.";
CM_ BO_ 516 "Error State of SC monitorings";
CM_ BO_ 515 "Error State of SC monitorings";
CM_ BO_ 514 "Error State of SC monitorings";
CM_ BO_ 512 "Error State of SC monitorings";
CM_ SG_ 321 BCC_T_Batt_30 "Batterietemperatur";
CM_ SG_ 321 BCC_T_Batt_29 "Batterietemperatur";
CM_ SG_ 320 BCC_T_Batt_28 "Batterietemperatur";
CM_ SG_ 320 BCC_T_Batt_27 "Batterietemperatur";
CM_ SG_ 319 BCC_T_Batt_26 "Batterietemperatur";
CM_ SG_ 319 BCC_T_Batt_25 "Batterietemperatur";
CM_ SG_ 318 BCC_T_Batt_24 "Batterietemperatur";
CM_ SG_ 318 BCC_T_Batt_23 "Batterietemperatur";
CM_ SG_ 317 BCC_T_Batt_22 "Batterietemperatur";
CM_ SG_ 317 BCC_T_Batt_21 "Batterietemperatur";
CM_ SG_ 316 BCC_T_Batt_20 "Batterietemperatur";
CM_ SG_ 316 BCC_T_Batt_19 "Batterietemperatur";
CM_ SG_ 315 BCC_T_Batt_18 "Batterietemperatur";
CM_ SG_ 315 BCC_T_Batt_17 "Batterietemperatur";
CM_ SG_ 314 BCC_T_Batt_16 "Batterietemperatur";
CM_ SG_ 314 BCC_T_Batt_15 "Batterietemperatur";
CM_ SG_ 313 BCC_T_Batt_14 "Batterietemperatur";
CM_ SG_ 313 BCC_T_Batt_13 "Batterietemperatur";
CM_ SG_ 312 BCC_T_Batt_12 "Batterietemperatur";
CM_ SG_ 312 BCC_T_Batt_11 "Batterietemperatur";
CM_ SG_ 311 BCC_T_Batt_10 "Batterietemperatur";
CM_ SG_ 311 BCC_T_Batt_09 "Batterietemperatur";
CM_ SG_ 310 BCC_T_Batt_08 "Batterietemperatur";
CM_ SG_ 310 BCC_T_Batt_07 "Batterietemperatur";
CM_ SG_ 32 BIW_v_EEPROM_Steps "Status der EEPROM-Funktion (welcher Block)";
CM_ SG_ 32 BIW_v_EEPROM_Status "Status der EEPROM-Funktion (init, write, finished)";
CM_ SG_ 32 BIW_v_States "Statemachine des BCCs";
BA_DEF_ SG_  "FlexKomSigLaenge" INT 1 64;
BA_DEF_ SG_  "GenSigDataID" STRING ;
BA_DEF_ SG_  "GenSigFuncType" ENUM  "NoFunction","MsgCounter","CRC-8","XOR","XOR-2","DatedBit","SW-KL15","not-used","Constant","Protocol","CRC-8-SAE_J1850","PROFILE_DAI_BR222_ID","PROFILE_DAI_BR222_noID","PROFILE_DAI_SAEJ","PROFILE_02";
BA_DEF_ SG_  "GenSigCycleTime" INT 0 0;
BA_DEF_ BO_  "App-Botschaft" ENUM  "nein","ja";
BA_DEF_ BO_  "GenMsgMinAcceptLength" INT 0 8;
BA_DEF_ BU_  "NmAsrCanMsgCycleOffset" INT 0 65535;
BA_DEF_ BU_  "NmAsrCanMsgReducedTime" INT 0 65535;
BA_DEF_ BU_  "NmAsrNodeIdentifier" HEX 0 253;
BA_DEF_  "NBTMax" INT 0 255;
BA_DEF_  "NBTMin" INT 0 255;
BA_DEF_  "NmAsrBaseAddress" HEX 1280 1343;
BA_DEF_  "NmAsrCanMsgCycleTime" INT 0 65535;
BA_DEF_  "NmAsrMessageCount" INT 1 256;
BA_DEF_  "NmAsrRepeatMessageTime" INT 0 65535;
BA_DEF_  "NmAsrTimeoutTime" INT 0 65535;
BA_DEF_  "NmAsrWaitBusSleepTime" INT 0 65535;
BA_DEF_  "SamplePointMax" FLOAT 0 100;
BA_DEF_  "SamplePointMin" FLOAT 0 100;
BA_DEF_  "DBName" STRING ;
BA_DEF_ BU_  "NodeLayerModules" STRING ;
BA_DEF_ BO_  "GenMsgStartDelayTime" INT 0 65535;
BA_DEF_ BO_  "GenMsgILSupport" ENUM  "No","Yes";
BA_DEF_ BO_  "GenMsgCycleTime" INT 0 50000;
BA_DEF_ BO_  "GenMsgSendType" ENUM  "cyclicX","spontanX","cyclicIfActiveX","spontanWithDelay","cyclicAndSpontanX","cyclicAndSpontanWithDelay","spontanWithRepitition","cyclicIfActiveAndSpontanWD","cyclicIfActiveFast","cyclicWithRepeatOnDemand","none";
BA_DEF_ BU_  "ILUsed" ENUM  "No","Yes";
BA_DEF_  "NmBaseAddress" HEX 1024 1087;
BA_DEF_  "BusType" STRING ;
BA_DEF_  "Baudrate" INT 0 1000000;
BA_DEF_  "VersionYear" INT 0 99;
BA_DEF_  "VersionWeek" INT 0 53;
BA_DEF_  "Version" HEX 0 255;
BA_DEF_  "Manufacturer" ENUM  "Vector";
BA_DEF_ SG_  "GenSigSendType" ENUM  "cyclicX","spontanX","cyclicIfActiveX","spontanWithDelay","cyclicAndSpontanX","cyclicAndSpontanWithDelay","spontanWithRepitition","cyclicIfActiveAndSpontanWD","cyclicIfActiveFast","cyclicWithRepeatOnDemand","none";
BA_DEF_ SG_  "GenSigStartValue" FLOAT 0 100000000000;
BA_DEF_DEF_  "FlexKomSigLaenge" 1;
BA_DEF_DEF_  "GenSigDataID" "0xFF";
BA_DEF_DEF_  "GenSigFuncType" "NoFunction";
BA_DEF_DEF_  "GenSigCycleTime" 0;
BA_DEF_DEF_  "App-Botschaft" "nein";
BA_DEF_DEF_  "GenMsgMinAcceptLength" 8;
BA_DEF_DEF_  "NmAsrCanMsgCycleOffset" 10;
BA_DEF_DEF_  "NmAsrCanMsgReducedTime" 50;
BA_DEF_DEF_  "NmAsrNodeIdentifier" 99;
BA_DEF_DEF_  "NBTMax" 20;
BA_DEF_DEF_  "NBTMin" 15;
BA_DEF_DEF_  "NmAsrBaseAddress" 1280;
BA_DEF_DEF_  "NmAsrCanMsgCycleTime" 2000;
BA_DEF_DEF_  "NmAsrMessageCount" 128;
BA_DEF_DEF_  "NmAsrRepeatMessageTime" 400;
BA_DEF_DEF_  "NmAsrTimeoutTime" 1000;
BA_DEF_DEF_  "NmAsrWaitBusSleepTime" 750;
BA_DEF_DEF_  "SamplePointMax" 81.25;
BA_DEF_DEF_  "SamplePointMin" 80;
BA_DEF_DEF_  "DBName" "";
BA_DEF_DEF_  "NodeLayerModules" "CANoeILNLVector.dll";
BA_DEF_DEF_  "GenMsgStartDelayTime" 0;
BA_DEF_DEF_  "GenMsgILSupport" "Yes";
BA_DEF_DEF_  "GenMsgCycleTime" 0;
BA_DEF_DEF_  "GenMsgSendType" "none";
BA_DEF_DEF_  "ILUsed" "Yes";
BA_DEF_DEF_  "NmBaseAddress" 1024;
BA_DEF_DEF_  "BusType" "CAN";
BA_DEF_DEF_  "Baudrate" 500000;
BA_DEF_DEF_  "VersionYear" 99;
BA_DEF_DEF_  "VersionWeek" 53;
BA_DEF_DEF_  "Version" 255;
BA_DEF_DEF_  "Manufacturer" "Vector";
BA_DEF_DEF_  "GenSigSendType" "none";
BA_DEF_DEF_  "GenSigStartValue" 0;
BA_ "VersionYear" 14;
BA_ "VersionWeek" 23;
BA_ "Version" 4;
BA_ "DBName" "CAN00";
BA_ "GenMsgSendType" BO_ 11 1;
BA_ "GenMsgCycleTime" BO_ 11 100;
BA_ "GenMsgSendType" BO_ 10 1;
BA_ "GenMsgCycleTime" BO_ 10 100;
BA_ "GenMsgCycleTime" BO_ 18 10;
BA_ "GenMsgSendType" BO_ 18 1;
BA_ "GenMsgCycleTime" BO_ 17 10;
BA_ "GenMsgSendType" BO_ 17 1;
BA_ "GenMsgCycleTime" BO_ 8 10;
BA_ "GenMsgSendType" BO_ 8 1;
BA_ "GenMsgSendType" BO_ 7 1;
BA_ "GenMsgCycleTime" BO_ 7 100;
BA_ "GenMsgSendType" BO_ 1813 1;
BA_ "GenMsgCycleTime" BO_ 1813 1000;
BA_ "GenMsgStartDelayTime" BO_ 1813 95;
BA_ "GenMsgCycleTime" BO_ 528 10;
BA_ "GenMsgSendType" BO_ 528 1;
BA_ "GenMsgStartDelayTime" BO_ 1799 85;
BA_ "GenMsgSendType" BO_ 1799 1;
BA_ "GenMsgCycleTime" BO_ 1799 100;
BA_ "GenMsgCycleTime" BO_ 1812 1000;
BA_ "GenMsgSendType" BO_ 1812 1;
BA_ "GenMsgStartDelayTime" BO_ 1812 95;
BA_ "GenMsgCycleTime" BO_ 1811 1000;
BA_ "GenMsgSendType" BO_ 1811 1;
BA_ "GenMsgStartDelayTime" BO_ 1811 95;
BA_ "GenMsgCycleTime" BO_ 1810 1000;
BA_ "GenMsgSendType" BO_ 1810 1;
BA_ "GenMsgStartDelayTime" BO_ 1810 95;
BA_ "GenMsgCycleTime" BO_ 1809 1000;
BA_ "GenMsgSendType" BO_ 1809 1;
BA_ "GenMsgStartDelayTime" BO_ 1809 95;
BA_ "GenMsgCycleTime" BO_ 1808 1000;
BA_ "GenMsgSendType" BO_ 1808 1;
BA_ "GenMsgStartDelayTime" BO_ 1808 95;
BA_ "GenMsgSendType" BO_ 521 1;
BA_ "GenMsgCycleTime" BO_ 521 10;
BA_ "GenMsgSendType" BO_ 520 1;
BA_ "GenMsgCycleTime" BO_ 520 10;
BA_ "GenMsgSendType" BO_ 519 1;
BA_ "GenMsgCycleTime" BO_ 519 10;
BA_ "GenMsgSendType" BO_ 518 1;
BA_ "GenMsgCycleTime" BO_ 518 10;
BA_ "GenMsgSendType" BO_ 517 1;
BA_ "GenMsgCycleTime" BO_ 517 10;
BA_ "GenMsgSendType" BO_ 516 1;
BA_ "GenMsgCycleTime" BO_ 516 10;
BA_ "GenMsgSendType" BO_ 515 1;
BA_ "GenMsgCycleTime" BO_ 515 10;
BA_ "GenMsgSendType" BO_ 514 1;
BA_ "GenMsgCycleTime" BO_ 514 10;
BA_ "GenMsgSendType" BO_ 513 1;
BA_ "GenMsgCycleTime" BO_ 513 10;
BA_ "GenMsgSendType" BO_ 512 1;
BA_ "GenMsgCycleTime" BO_ 512 10;
BA_ "GenMsgSendType" BO_ 321 1;
BA_ "GenMsgCycleTime" BO_ 321 100;
BA_ "GenMsgStartDelayTime" BO_ 321 35;
BA_ "GenMsgSendType" BO_ 320 1;
BA_ "GenMsgCycleTime" BO_ 320 100;
BA_ "GenMsgStartDelayTime" BO_ 320 25;
BA_ "GenMsgSendType" BO_ 319 1;
BA_ "GenMsgCycleTime" BO_ 319 100;
BA_ "GenMsgStartDelayTime" BO_ 319 25;
BA_ "GenMsgSendType" BO_ 318 1;
BA_ "GenMsgCycleTime" BO_ 318 100;
BA_ "GenMsgStartDelayTime" BO_ 318 25;
BA_ "GenMsgSendType" BO_ 317 1;
BA_ "GenMsgCycleTime" BO_ 317 100;
BA_ "GenMsgStartDelayTime" BO_ 317 25;
BA_ "GenMsgSendType" BO_ 316 1;
BA_ "GenMsgCycleTime" BO_ 316 100;
BA_ "GenMsgStartDelayTime" BO_ 316 25;
BA_ "GenMsgSendType" BO_ 315 1;
BA_ "GenMsgCycleTime" BO_ 315 100;
BA_ "GenMsgStartDelayTime" BO_ 315 25;
BA_ "GenMsgSendType" BO_ 314 1;
BA_ "GenMsgCycleTime" BO_ 314 100;
BA_ "GenMsgStartDelayTime" BO_ 314 25;
BA_ "GenMsgSendType" BO_ 313 1;
BA_ "GenMsgCycleTime" BO_ 313 100;
BA_ "GenMsgStartDelayTime" BO_ 313 25;
BA_ "GenMsgSendType" BO_ 312 1;
BA_ "GenMsgCycleTime" BO_ 312 100;
BA_ "GenMsgStartDelayTime" BO_ 312 25;
BA_ "GenMsgSendType" BO_ 524 1;
BA_ "GenMsgCycleTime" BO_ 524 1000;
BA_ "GenMsgStartDelayTime" BO_ 524 95;
BA_ "GenMsgSendType" BO_ 768 1;
BA_ "GenMsgCycleTime" BO_ 768 1000;
BA_ "GenMsgStartDelayTime" BO_ 768 95;
BA_ "GenMsgSendType" BO_ 852 1;
BA_ "GenMsgCycleTime" BO_ 852 1000;
BA_ "GenMsgStartDelayTime" BO_ 852 95;
BA_ "GenMsgSendType" BO_ 850 1;
BA_ "GenMsgCycleTime" BO_ 850 1000;
BA_ "GenMsgStartDelayTime" BO_ 850 95;
BA_ "GenMsgSendType" BO_ 848 1;
BA_ "GenMsgCycleTime" BO_ 848 1000;
BA_ "GenMsgStartDelayTime" BO_ 848 95;
BA_ "GenMsgSendType" BO_ 311 1;
BA_ "GenMsgCycleTime" BO_ 311 100;
BA_ "GenMsgStartDelayTime" BO_ 311 25;
BA_ "GenMsgSendType" BO_ 310 1;
BA_ "GenMsgCycleTime" BO_ 310 100;
BA_ "GenMsgStartDelayTime" BO_ 310 25;
BA_ "GenMsgSendType" BO_ 853 1;
BA_ "GenMsgCycleTime" BO_ 853 10;
BA_ "GenMsgCycleTime" BO_ 769 10;
BA_ "GenMsgSendType" BO_ 769 1;
BA_ "GenMsgCycleTime" BO_ 851 10;
BA_ "GenMsgSendType" BO_ 851 1;
BA_ "GenMsgCycleTime" BO_ 849 10;
BA_ "GenMsgSendType" BO_ 849 1;
BA_ "GenMsgCycleTime" BO_ 32 10;
BA_ "GenMsgSendType" BO_ 32 1;
BA_ "GenMsgCycleTime" BO_ 555 10;
BA_ "GenMsgSendType" BO_ 555 1;
BA_ "GenSigSendType" SG_ 11 AI_SOC_ESP 1;
BA_ "GenSigCycleTime" SG_ 11 AI_SOC_ESP 100;
BA_ "GenSigSendType" SG_ 10 AI_SOH_ESP 1;
BA_ "GenSigCycleTime" SG_ 10 AI_SOH_ESP 100;
BA_ "GenSigCycleTime" SG_ 17 U_Battery 10;
BA_ "GenSigSendType" SG_ 17 U_Battery 1;
BA_ "GenSigCycleTime" SG_ 8 Pwm_R_HBridge_LowSide 10;
BA_ "GenSigSendType" SG_ 8 Pwm_R_HBridge_LowSide 0;
BA_ "GenSigCycleTime" SG_ 8 Pwm_R_HBridge_HighSide 10;
BA_ "GenSigSendType" SG_ 8 Pwm_R_HBridge_HighSide 0;
BA_ "GenSigCycleTime" SG_ 8 Pwm_L_HBridge_LowSide 10;
BA_ "GenSigSendType" SG_ 8 Pwm_L_HBridge_LowSide 0;
BA_ "GenSigCycleTime" SG_ 8 Pwm_L_HBridge_HighSide 10;
BA_ "GenSigSendType" SG_ 8 Pwm_L_HBridge_HighSide 0;
BA_ "GenSigCycleTime" SG_ 7 AI_SOH_TAB 100;
BA_ "GenSigSendType" SG_ 7 AI_SOH_TAB 1;
BA_ "GenSigCycleTime" SG_ 7 AI_SOC_TAB 100;
BA_ "GenSigSendType" SG_ 7 AI_SOC_TAB 1;
BA_ "GenSigCycleTime" SG_ 1813 SC_CSE3_HW_Release 1000;
BA_ "GenSigSendType" SG_ 1813 SC_CSE3_HW_Release 1;
BA_ "GenSigStartValue" SG_ 1813 SC_CSE3_HW_Release 255;
BA_ "GenSigCycleTime" SG_ 1813 SC_CSE3_HW_Minor 1000;
BA_ "GenSigSendType" SG_ 1813 SC_CSE3_HW_Minor 1;
BA_ "GenSigStartValue" SG_ 1813 SC_CSE3_HW_Minor 255;
BA_ "GenSigCycleTime" SG_ 1813 SC_CSE3_HW_Major 1000;
BA_ "GenSigSendType" SG_ 1813 SC_CSE3_HW_Major 1;
BA_ "GenSigStartValue" SG_ 1813 SC_CSE3_HW_Major 255;
BA_ "GenSigCycleTime" SG_ 528 SC_ERR_Reserved_11_12 10;
BA_ "GenSigSendType" SG_ 528 SC_ERR_Reserved_11_12 1;
BA_ "GenSigStartValue" SG_ 528 SC_ERR_Reserved_11_12 7;
BA_ "GenSigCycleTime" SG_ 528 SC_ERR_Reserved_11_11 10;
BA_ "GenSigSendType" SG_ 528 SC_ERR_Reserved_11_11 1;
BA_ "GenSigStartValue" SG_ 528 SC_ERR_Reserved_11_11 7;
BA_ "GenSigCycleTime" SG_ 528 SC_ERR_Reserved_11_10 10;
BA_ "GenSigSendType" SG_ 528 SC_ERR_Reserved_11_10 1;
BA_ "GenSigStartValue" SG_ 528 SC_ERR_Reserved_11_10 7;
BA_ "GenSigCycleTime" SG_ 528 SC_ERR_Reserved_11_09 10;
BA_ "GenSigSendType" SG_ 528 SC_ERR_Reserved_11_09 1;
BA_ "GenSigStartValue" SG_ 528 SC_ERR_Reserved_11_09 7;
BA_ "GenSigCycleTime" SG_ 528 SC_ERR_Reserved_11_08 10;
BA_ "GenSigSendType" SG_ 528 SC_ERR_Reserved_11_08 1;
BA_ "GenSigStartValue" SG_ 528 SC_ERR_Reserved_11_08 7;
BA_ "GenSigCycleTime" SG_ 528 SC_ERR_Reserved_11_07 10;
BA_ "GenSigSendType" SG_ 528 SC_ERR_Reserved_11_07 1;
BA_ "GenSigStartValue" SG_ 528 SC_ERR_Reserved_11_07 7;
BA_ "GenSigCycleTime" SG_ 528 SC_ERR_Reserved_11_06 10;
BA_ "GenSigSendType" SG_ 528 SC_ERR_Reserved_11_06 1;
BA_ "GenSigStartValue" SG_ 528 SC_ERR_Reserved_11_06 7;
BA_ "GenSigCycleTime" SG_ 528 SC_ERR_Reserved_11_05 10;
BA_ "GenSigSendType" SG_ 528 SC_ERR_Reserved_11_05 1;
BA_ "GenSigStartValue" SG_ 528 SC_ERR_Reserved_11_05 7;
BA_ "GenSigCycleTime" SG_ 528 SC_ERR_Reserved_11_04 10;
BA_ "GenSigSendType" SG_ 528 SC_ERR_Reserved_11_04 1;
BA_ "GenSigStartValue" SG_ 528 SC_ERR_Reserved_11_04 7;
BA_ "GenSigCycleTime" SG_ 528 SC_ERR_Reserved_11_03 10;
BA_ "GenSigSendType" SG_ 528 SC_ERR_Reserved_11_03 1;
BA_ "GenSigStartValue" SG_ 528 SC_ERR_Reserved_11_03 7;
BA_ "GenSigCycleTime" SG_ 528 SC_ERR_Reserved_11_02 10;
BA_ "GenSigSendType" SG_ 528 SC_ERR_Reserved_11_02 1;
BA_ "GenSigStartValue" SG_ 528 SC_ERR_Reserved_11_02 7;
BA_ "GenSigCycleTime" SG_ 528 SC_ERR_Reserved_11_01 10;
BA_ "GenSigSendType" SG_ 528 SC_ERR_Reserved_11_01 1;
BA_ "GenSigStartValue" SG_ 528 SC_ERR_Reserved_11_01 7;
BA_ "GenSigCycleTime" SG_ 528 SC_ERR_CSE3_PCB_Temp2_RNGL 10;
BA_ "GenSigSendType" SG_ 528 SC_ERR_CSE3_PCB_Temp2_RNGL 1;
BA_ "GenSigStartValue" SG_ 528 SC_ERR_CSE3_PCB_Temp2_RNGL 7;
BA_ "GenSigCycleTime" SG_ 528 SC_ERR_CSE3_PCB_Temp2_RNGH 10;
BA_ "GenSigSendType" SG_ 528 SC_ERR_CSE3_PCB_Temp2_RNGH 1;
BA_ "GenSigStartValue" SG_ 528 SC_ERR_CSE3_PCB_Temp2_RNGH 7;
BA_ "GenSigCycleTime" SG_ 528 SC_ERR_CSE3_PCB_Temp2_High 10;
BA_ "GenSigSendType" SG_ 528 SC_ERR_CSE3_PCB_Temp2_High 1;
BA_ "GenSigStartValue" SG_ 528 SC_ERR_CSE3_PCB_Temp2_High 7;
BA_ "GenSigCycleTime" SG_ 528 SC_ERR_CSE3_PCB_Temp1_RNGL 10;
BA_ "GenSigSendType" SG_ 528 SC_ERR_CSE3_PCB_Temp1_RNGL 1;
BA_ "GenSigStartValue" SG_ 528 SC_ERR_CSE3_PCB_Temp1_RNGL 7;
BA_ "GenSigCycleTime" SG_ 528 SC_ERR_CSE3_PCB_Temp1_RNGH 10;
BA_ "GenSigSendType" SG_ 528 SC_ERR_CSE3_PCB_Temp1_RNGH 1;
BA_ "GenSigStartValue" SG_ 528 SC_ERR_CSE3_PCB_Temp1_RNGH 7;
BA_ "GenSigCycleTime" SG_ 528 SC_ERR_CSE3_PCB_Temp1_High 10;
BA_ "GenSigSendType" SG_ 528 SC_ERR_CSE3_PCB_Temp1_High 1;
BA_ "GenSigStartValue" SG_ 528 SC_ERR_CSE3_PCB_Temp1_High 7;
BA_ "GenSigCycleTime" SG_ 528 SC_ERR_CSE3_Fault_Line 10;
BA_ "GenSigSendType" SG_ 528 SC_ERR_CSE3_Fault_Line 1;
BA_ "GenSigStartValue" SG_ 528 SC_ERR_CSE3_Fault_Line 7;
BA_ "GenSigCycleTime" SG_ 528 SC_ERR_CSE3_Daisy_Chain 10;
BA_ "GenSigSendType" SG_ 528 SC_ERR_CSE3_Daisy_Chain 1;
BA_ "GenSigStartValue" SG_ 528 SC_ERR_CSE3_Daisy_Chain 7;
BA_ "GenSigCycleTime" SG_ 528 SC_ERR_CSE3_Com_TOut 10;
BA_ "GenSigStartValue" SG_ 528 SC_ERR_CSE3_Com_TOut 7;
BA_ "GenSigSendType" SG_ 528 SC_ERR_CSE3_Com_TOut 1;
BA_ "GenSigCycleTime" SG_ 1799 Aging_Counter 100;
BA_ "GenSigSendType" SG_ 1799 Aging_Counter 1;
BA_ "GenSigCycleTime" SG_ 1799 CPU_Load_valid 100;
BA_ "GenSigSendType" SG_ 1799 CPU_Load_valid 1;
BA_ "GenSigCycleTime" SG_ 1799 CPU_Load 100;
BA_ "GenSigSendType" SG_ 1799 CPU_Load 1;
BA_ "GenSigCycleTime" SG_ 1812 SC_CSE2_HW_Release 1000;
BA_ "GenSigStartValue" SG_ 1812 SC_CSE2_HW_Release 255;
BA_ "GenSigSendType" SG_ 1812 SC_CSE2_HW_Release 1;
BA_ "GenSigCycleTime" SG_ 1812 SC_CSE2_HW_Minor 1000;
BA_ "GenSigStartValue" SG_ 1812 SC_CSE2_HW_Minor 255;
BA_ "GenSigSendType" SG_ 1812 SC_CSE2_HW_Minor 1;
BA_ "GenSigCycleTime" SG_ 1812 SC_CSE2_HW_Major 1000;
BA_ "GenSigStartValue" SG_ 1812 SC_CSE2_HW_Major 255;
BA_ "GenSigSendType" SG_ 1812 SC_CSE2_HW_Major 1;
BA_ "GenSigCycleTime" SG_ 1812 SC_CSE1_HW_Release 1000;
BA_ "GenSigStartValue" SG_ 1812 SC_CSE1_HW_Release 255;
BA_ "GenSigSendType" SG_ 1812 SC_CSE1_HW_Release 1;
BA_ "GenSigCycleTime" SG_ 1812 SC_CSE1_HW_Minor 1000;
BA_ "GenSigStartValue" SG_ 1812 SC_CSE1_HW_Minor 255;
BA_ "GenSigSendType" SG_ 1812 SC_CSE1_HW_Minor 1;
BA_ "GenSigCycleTime" SG_ 1812 SC_CSE1_HW_Major 1000;
BA_ "GenSigStartValue" SG_ 1812 SC_CSE1_HW_Major 255;
BA_ "GenSigSendType" SG_ 1812 SC_CSE1_HW_Major 1;
BA_ "GenSigCycleTime" SG_ 1811 SC_IMOC_SW_Release 1000;
BA_ "GenSigStartValue" SG_ 1811 SC_IMOC_SW_Release 255;
BA_ "GenSigSendType" SG_ 1811 SC_IMOC_SW_Release 1;
BA_ "GenSigCycleTime" SG_ 1811 SC_IMOC_SW_Minor 1000;
BA_ "GenSigStartValue" SG_ 1811 SC_IMOC_SW_Minor 255;
BA_ "GenSigSendType" SG_ 1811 SC_IMOC_SW_Minor 1;
BA_ "GenSigCycleTime" SG_ 1811 SC_IMOC_SW_Major 1000;
BA_ "GenSigStartValue" SG_ 1811 SC_IMOC_SW_Major 255;
BA_ "GenSigSendType" SG_ 1811 SC_IMOC_SW_Major 1;
BA_ "GenSigCycleTime" SG_ 1811 SC_IMOC_HW_Release 1000;
BA_ "GenSigStartValue" SG_ 1811 SC_IMOC_HW_Release 255;
BA_ "GenSigSendType" SG_ 1811 SC_IMOC_HW_Release 1;
BA_ "GenSigCycleTime" SG_ 1811 SC_IMOC_HW_Minor 1000;
BA_ "GenSigStartValue" SG_ 1811 SC_IMOC_HW_Minor 255;
BA_ "GenSigSendType" SG_ 1811 SC_IMOC_HW_Minor 1;
BA_ "GenSigCycleTime" SG_ 1811 SC_IMOC_HW_Major 1000;
BA_ "GenSigStartValue" SG_ 1811 SC_IMOC_HW_Major 255;
BA_ "GenSigSendType" SG_ 1811 SC_IMOC_HW_Major 1;
BA_ "GenSigCycleTime" SG_ 1811 SC_IMOC_DS_CRC 1000;
BA_ "GenSigStartValue" SG_ 1811 SC_IMOC_DS_CRC 65535;
BA_ "GenSigSendType" SG_ 1811 SC_IMOC_DS_CRC 1;
BA_ "GenSigCycleTime" SG_ 1810 SC_CSM2_SW_Release 1000;
BA_ "GenSigStartValue" SG_ 1810 SC_CSM2_SW_Release 255;
BA_ "GenSigSendType" SG_ 1810 SC_CSM2_SW_Release 1;
BA_ "GenSigCycleTime" SG_ 1810 SC_CSM2_SW_Minor 1000;
BA_ "GenSigStartValue" SG_ 1810 SC_CSM2_SW_Minor 255;
BA_ "GenSigSendType" SG_ 1810 SC_CSM2_SW_Minor 1;
BA_ "GenSigCycleTime" SG_ 1810 SC_CSM2_SW_Major 1000;
BA_ "GenSigStartValue" SG_ 1810 SC_CSM2_SW_Major 255;
BA_ "GenSigSendType" SG_ 1810 SC_CSM2_SW_Major 1;
BA_ "GenSigCycleTime" SG_ 1810 SC_CSM2_HW_Release 1000;
BA_ "GenSigStartValue" SG_ 1810 SC_CSM2_HW_Release 255;
BA_ "GenSigSendType" SG_ 1810 SC_CSM2_HW_Release 1;
BA_ "GenSigCycleTime" SG_ 1810 SC_CSM2_HW_Minor 1000;
BA_ "GenSigStartValue" SG_ 1810 SC_CSM2_HW_Minor 255;
BA_ "GenSigSendType" SG_ 1810 SC_CSM2_HW_Minor 1;
BA_ "GenSigCycleTime" SG_ 1810 SC_CSM2_HW_Major 1000;
BA_ "GenSigStartValue" SG_ 1810 SC_CSM2_HW_Major 255;
BA_ "GenSigSendType" SG_ 1810 SC_CSM2_HW_Major 1;
BA_ "GenSigCycleTime" SG_ 1810 SC_CSM2_DS_CRC 1000;
BA_ "GenSigStartValue" SG_ 1810 SC_CSM2_DS_CRC 65535;
BA_ "GenSigSendType" SG_ 1810 SC_CSM2_DS_CRC 1;
BA_ "GenSigCycleTime" SG_ 1809 SC_CSM1_SW_Release 1000;
BA_ "GenSigStartValue" SG_ 1809 SC_CSM1_SW_Release 255;
BA_ "GenSigSendType" SG_ 1809 SC_CSM1_SW_Release 1;
BA_ "GenSigCycleTime" SG_ 1809 SC_CSM1_SW_Minor 1000;
BA_ "GenSigStartValue" SG_ 1809 SC_CSM1_SW_Minor 255;
BA_ "GenSigSendType" SG_ 1809 SC_CSM1_SW_Minor 1;
BA_ "GenSigCycleTime" SG_ 1809 SC_CSM1_SW_Major 1000;
BA_ "GenSigStartValue" SG_ 1809 SC_CSM1_SW_Major 255;
BA_ "GenSigSendType" SG_ 1809 SC_CSM1_SW_Major 1;
BA_ "GenSigCycleTime" SG_ 1809 SC_CSM1_HW_Release 1000;
BA_ "GenSigStartValue" SG_ 1809 SC_CSM1_HW_Release 255;
BA_ "GenSigSendType" SG_ 1809 SC_CSM1_HW_Release 1;
BA_ "GenSigCycleTime" SG_ 1809 SC_CSM1_HW_Minor 1000;
BA_ "GenSigStartValue" SG_ 1809 SC_CSM1_HW_Minor 255;
BA_ "GenSigSendType" SG_ 1809 SC_CSM1_HW_Minor 1;
BA_ "GenSigCycleTime" SG_ 1809 SC_CSM1_HW_Major 1000;
BA_ "GenSigStartValue" SG_ 1809 SC_CSM1_HW_Major 255;
BA_ "GenSigSendType" SG_ 1809 SC_CSM1_HW_Major 1;
BA_ "GenSigCycleTime" SG_ 1809 SC_CSM1_DS_CRC 1000;
BA_ "GenSigStartValue" SG_ 1809 SC_CSM1_DS_CRC 65535;
BA_ "GenSigSendType" SG_ 1809 SC_CSM1_DS_CRC 1;
BA_ "GenSigCycleTime" SG_ 1808 SC_SW_Release 1000;
BA_ "GenSigStartValue" SG_ 1808 SC_SW_Release 255;
BA_ "GenSigSendType" SG_ 1808 SC_SW_Release 1;
BA_ "GenSigCycleTime" SG_ 1808 SC_SW_Minor 1000;
BA_ "GenSigStartValue" SG_ 1808 SC_SW_Minor 255;
BA_ "GenSigSendType" SG_ 1808 SC_SW_Minor 1;
BA_ "GenSigCycleTime" SG_ 1808 SC_SW_Major 1000;
BA_ "GenSigStartValue" SG_ 1808 SC_SW_Major 255;
BA_ "GenSigSendType" SG_ 1808 SC_SW_Major 1;
BA_ "GenSigCycleTime" SG_ 1808 SC_HW_Release 1000;
BA_ "GenSigStartValue" SG_ 1808 SC_HW_Release 255;
BA_ "GenSigSendType" SG_ 1808 SC_HW_Release 1;
BA_ "GenSigCycleTime" SG_ 1808 SC_HW_Minor 1000;
BA_ "GenSigStartValue" SG_ 1808 SC_HW_Minor 255;
BA_ "GenSigSendType" SG_ 1808 SC_HW_Minor 1;
BA_ "GenSigCycleTime" SG_ 1808 SC_HW_Major 1000;
BA_ "GenSigStartValue" SG_ 1808 SC_HW_Major 255;
BA_ "GenSigSendType" SG_ 1808 SC_HW_Major 1;
BA_ "GenSigCycleTime" SG_ 1808 SC_DS_CRC 1000;
BA_ "GenSigStartValue" SG_ 1808 SC_DS_CRC 65535;
BA_ "GenSigSendType" SG_ 1808 SC_DS_CRC 1;
BA_ "GenSigCycleTime" SG_ 521 SC_ERR_Reserved_10_07 10;
BA_ "GenSigStartValue" SG_ 521 SC_ERR_Reserved_10_07 7;
BA_ "GenSigSendType" SG_ 521 SC_ERR_Reserved_10_07 1;
BA_ "GenSigCycleTime" SG_ 521 SC_ERR_Reserved_10_06 10;
BA_ "GenSigStartValue" SG_ 521 SC_ERR_Reserved_10_06 7;
BA_ "GenSigSendType" SG_ 521 SC_ERR_Reserved_10_06 1;
BA_ "GenSigCycleTime" SG_ 521 SC_ERR_Reserved_10_05 10;
BA_ "GenSigStartValue" SG_ 521 SC_ERR_Reserved_10_05 7;
BA_ "GenSigSendType" SG_ 521 SC_ERR_Reserved_10_05 1;
BA_ "GenSigCycleTime" SG_ 521 SC_ERR_Reserved_10_04 10;
BA_ "GenSigStartValue" SG_ 521 SC_ERR_Reserved_10_04 7;
BA_ "GenSigSendType" SG_ 521 SC_ERR_Reserved_10_04 1;
BA_ "GenSigCycleTime" SG_ 521 SC_ERR_Reserved_10_03 10;
BA_ "GenSigStartValue" SG_ 521 SC_ERR_Reserved_10_03 7;
BA_ "GenSigSendType" SG_ 521 SC_ERR_Reserved_10_03 1;
BA_ "GenSigCycleTime" SG_ 521 SC_ERR_Reserved_10_02 10;
BA_ "GenSigStartValue" SG_ 521 SC_ERR_Reserved_10_02 7;
BA_ "GenSigSendType" SG_ 521 SC_ERR_Reserved_10_02 1;
BA_ "GenSigCycleTime" SG_ 521 SC_ERR_Reserved_10_01 10;
BA_ "GenSigStartValue" SG_ 521 SC_ERR_Reserved_10_01 7;
BA_ "GenSigSendType" SG_ 521 SC_ERR_Reserved_10_01 1;
BA_ "GenSigCycleTime" SG_ 521 SC_ERR_FUSI_FSG_01 10;
BA_ "GenSigStartValue" SG_ 521 SC_ERR_FUSI_FSG_01 7;
BA_ "GenSigSendType" SG_ 521 SC_ERR_FUSI_FSG_01 1;
BA_ "GenSigCycleTime" SG_ 521 SC_ERR_FUSI_FSG_02 10;
BA_ "GenSigStartValue" SG_ 521 SC_ERR_FUSI_FSG_02 7;
BA_ "GenSigSendType" SG_ 521 SC_ERR_FUSI_FSG_02 1;
BA_ "GenSigCycleTime" SG_ 521 SC_ERR_FUSI_FSG_03 10;
BA_ "GenSigStartValue" SG_ 521 SC_ERR_FUSI_FSG_03 7;
BA_ "GenSigSendType" SG_ 521 SC_ERR_FUSI_FSG_03 1;
BA_ "GenSigCycleTime" SG_ 521 SC_ERR_FUSI_FSG_04 10;
BA_ "GenSigStartValue" SG_ 521 SC_ERR_FUSI_FSG_04 7;
BA_ "GenSigSendType" SG_ 521 SC_ERR_FUSI_FSG_04 1;
BA_ "GenSigCycleTime" SG_ 521 SC_ERR_FUSI_FSG_05 10;
BA_ "GenSigStartValue" SG_ 521 SC_ERR_FUSI_FSG_05 7;
BA_ "GenSigSendType" SG_ 521 SC_ERR_FUSI_FSG_05 1;
BA_ "GenSigCycleTime" SG_ 521 SC_ERR_FUSI_FSG_06 10;
BA_ "GenSigStartValue" SG_ 521 SC_ERR_FUSI_FSG_06 7;
BA_ "GenSigSendType" SG_ 521 SC_ERR_FUSI_FSG_06 1;
BA_ "GenSigCycleTime" SG_ 521 SC_ERR_FUSI_FSG_07 10;
BA_ "GenSigStartValue" SG_ 521 SC_ERR_FUSI_FSG_07 7;
BA_ "GenSigSendType" SG_ 521 SC_ERR_FUSI_FSG_07 1;
BA_ "GenSigCycleTime" SG_ 521 SC_ERR_FUSI_FSG_08 10;
BA_ "GenSigStartValue" SG_ 521 SC_ERR_FUSI_FSG_08 7;
BA_ "GenSigSendType" SG_ 521 SC_ERR_FUSI_FSG_08 1;
BA_ "GenSigCycleTime" SG_ 521 SC_ERR_FUSI_FSG_09 10;
BA_ "GenSigStartValue" SG_ 521 SC_ERR_FUSI_FSG_09 7;
BA_ "GenSigSendType" SG_ 521 SC_ERR_FUSI_FSG_09 1;
BA_ "GenSigCycleTime" SG_ 521 SC_ERR_SC_ROM 10;
BA_ "GenSigStartValue" SG_ 521 SC_ERR_SC_ROM 7;
BA_ "GenSigSendType" SG_ 521 SC_ERR_SC_ROM 1;
BA_ "GenSigCycleTime" SG_ 521 SC_ERR_SC_RAM 10;
BA_ "GenSigStartValue" SG_ 521 SC_ERR_SC_RAM 7;
BA_ "GenSigSendType" SG_ 521 SC_ERR_SC_RAM 1;
BA_ "GenSigCycleTime" SG_ 521 SC_ERR_SC_NVRAM 10;
BA_ "GenSigStartValue" SG_ 521 SC_ERR_SC_NVRAM 7;
BA_ "GenSigSendType" SG_ 521 SC_ERR_SC_NVRAM 1;
BA_ "GenSigCycleTime" SG_ 521 SC_ERR_IMOC_ROM 10;
BA_ "GenSigStartValue" SG_ 521 SC_ERR_IMOC_ROM 7;
BA_ "GenSigSendType" SG_ 521 SC_ERR_IMOC_ROM 1;
BA_ "GenSigCycleTime" SG_ 521 SC_ERR_IMOC_RAM 10;
BA_ "GenSigStartValue" SG_ 521 SC_ERR_IMOC_RAM 7;
BA_ "GenSigSendType" SG_ 521 SC_ERR_IMOC_RAM 1;
BA_ "GenSigCycleTime" SG_ 520 SC_ERR_Reserved_09_14 10;
BA_ "GenSigSendType" SG_ 520 SC_ERR_Reserved_09_14 1;
BA_ "GenSigStartValue" SG_ 520 SC_ERR_Reserved_09_14 7;
BA_ "GenSigCycleTime" SG_ 520 SC_ERR_Reserved_09_13 10;
BA_ "GenSigSendType" SG_ 520 SC_ERR_Reserved_09_13 1;
BA_ "GenSigStartValue" SG_ 520 SC_ERR_Reserved_09_13 7;
BA_ "GenSigCycleTime" SG_ 520 SC_ERR_Reserved_09_12 10;
BA_ "GenSigSendType" SG_ 520 SC_ERR_Reserved_09_12 1;
BA_ "GenSigStartValue" SG_ 520 SC_ERR_Reserved_09_12 7;
BA_ "GenSigCycleTime" SG_ 520 SC_ERR_Reserved_09_11 10;
BA_ "GenSigSendType" SG_ 520 SC_ERR_Reserved_09_11 1;
BA_ "GenSigStartValue" SG_ 520 SC_ERR_Reserved_09_11 7;
BA_ "GenSigCycleTime" SG_ 520 SC_ERR_Reserved_09_10 10;
BA_ "GenSigSendType" SG_ 520 SC_ERR_Reserved_09_10 1;
BA_ "GenSigStartValue" SG_ 520 SC_ERR_Reserved_09_10 7;
BA_ "GenSigCycleTime" SG_ 520 SC_ERR_Reserved_09_09 10;
BA_ "GenSigSendType" SG_ 520 SC_ERR_Reserved_09_09 1;
BA_ "GenSigStartValue" SG_ 520 SC_ERR_Reserved_09_09 7;
BA_ "GenSigCycleTime" SG_ 520 SC_ERR_Reserved_09_08 10;
BA_ "GenSigSendType" SG_ 520 SC_ERR_Reserved_09_08 1;
BA_ "GenSigStartValue" SG_ 520 SC_ERR_Reserved_09_08 7;
BA_ "GenSigCycleTime" SG_ 520 SC_ERR_Reserved_09_07 10;
BA_ "GenSigSendType" SG_ 520 SC_ERR_Reserved_09_07 1;
BA_ "GenSigStartValue" SG_ 520 SC_ERR_Reserved_09_07 7;
BA_ "GenSigCycleTime" SG_ 520 SC_ERR_Reserved_09_06 10;
BA_ "GenSigSendType" SG_ 520 SC_ERR_Reserved_09_06 1;
BA_ "GenSigStartValue" SG_ 520 SC_ERR_Reserved_09_06 7;
BA_ "GenSigCycleTime" SG_ 520 SC_ERR_Reserved_09_05 10;
BA_ "GenSigSendType" SG_ 520 SC_ERR_Reserved_09_05 1;
BA_ "GenSigStartValue" SG_ 520 SC_ERR_Reserved_09_05 7;
BA_ "GenSigCycleTime" SG_ 520 SC_ERR_Reserved_09_04 10;
BA_ "GenSigSendType" SG_ 520 SC_ERR_Reserved_09_04 1;
BA_ "GenSigStartValue" SG_ 520 SC_ERR_Reserved_09_04 7;
BA_ "GenSigCycleTime" SG_ 520 SC_ERR_Reserved_09_03 10;
BA_ "GenSigSendType" SG_ 520 SC_ERR_Reserved_09_03 1;
BA_ "GenSigStartValue" SG_ 520 SC_ERR_Reserved_09_03 7;
BA_ "GenSigCycleTime" SG_ 520 SC_ERR_Reserved_09_02 10;
BA_ "GenSigSendType" SG_ 520 SC_ERR_Reserved_09_02 1;
BA_ "GenSigStartValue" SG_ 520 SC_ERR_Reserved_09_02 7;
BA_ "GenSigCycleTime" SG_ 520 SC_ERR_Reserved_09_01 10;
BA_ "GenSigSendType" SG_ 520 SC_ERR_Reserved_09_01 1;
BA_ "GenSigStartValue" SG_ 520 SC_ERR_Reserved_09_01 7;
BA_ "GenSigCycleTime" SG_ 520 SC_ERR_ISO_Meas_Selftest 10;
BA_ "GenSigSendType" SG_ 520 SC_ERR_ISO_Meas_Selftest 1;
BA_ "GenSigStartValue" SG_ 520 SC_ERR_ISO_Meas_Selftest 7;
BA_ "GenSigCycleTime" SG_ 520 SC_ERR_ISO_Int_Lvl3 10;
BA_ "GenSigSendType" SG_ 520 SC_ERR_ISO_Int_Lvl3 1;
BA_ "GenSigStartValue" SG_ 520 SC_ERR_ISO_Int_Lvl3 7;
BA_ "GenSigCycleTime" SG_ 520 SC_ERR_ISO_Int_Lvl2 10;
BA_ "GenSigSendType" SG_ 520 SC_ERR_ISO_Int_Lvl2 1;
BA_ "GenSigStartValue" SG_ 520 SC_ERR_ISO_Int_Lvl2 7;
BA_ "GenSigCycleTime" SG_ 520 SC_ERR_ISO_Int_Lvl1 10;
BA_ "GenSigSendType" SG_ 520 SC_ERR_ISO_Int_Lvl1 1;
BA_ "GenSigStartValue" SG_ 520 SC_ERR_ISO_Int_Lvl1 7;
BA_ "GenSigCycleTime" SG_ 520 SC_ERR_ISO_Ext_Lvl3 10;
BA_ "GenSigSendType" SG_ 520 SC_ERR_ISO_Ext_Lvl3 1;
BA_ "GenSigStartValue" SG_ 520 SC_ERR_ISO_Ext_Lvl3 7;
BA_ "GenSigCycleTime" SG_ 520 SC_ERR_ISO_Ext_Lvl2 10;
BA_ "GenSigSendType" SG_ 520 SC_ERR_ISO_Ext_Lvl2 1;
BA_ "GenSigStartValue" SG_ 520 SC_ERR_ISO_Ext_Lvl2 7;
BA_ "GenSigCycleTime" SG_ 520 SC_ERR_ISO_Ext_Lvl1 10;
BA_ "GenSigSendType" SG_ 520 SC_ERR_ISO_Ext_Lvl1 1;
BA_ "GenSigStartValue" SG_ 520 SC_ERR_ISO_Ext_Lvl1 7;
BA_ "GenSigCycleTime" SG_ 519 SC_ERR_Reserved_08_02 10;
BA_ "GenSigSendType" SG_ 519 SC_ERR_Reserved_08_02 1;
BA_ "GenSigStartValue" SG_ 519 SC_ERR_Reserved_08_02 7;
BA_ "GenSigCycleTime" SG_ 519 SC_ERR_Reserved_08_01 10;
BA_ "GenSigSendType" SG_ 519 SC_ERR_Reserved_08_01 1;
BA_ "GenSigStartValue" SG_ 519 SC_ERR_Reserved_08_01 7;
BA_ "GenSigCycleTime" SG_ 519 SC_ERR_CAN_Sc_Meas_Busoff 10;
BA_ "GenSigSendType" SG_ 519 SC_ERR_CAN_Sc_Meas_Busoff 1;
BA_ "GenSigStartValue" SG_ 519 SC_ERR_CAN_Sc_Meas_Busoff 7;
BA_ "GenSigCycleTime" SG_ 519 SC_ERR_CAN_Data_Busoff 10;
BA_ "GenSigSendType" SG_ 519 SC_ERR_CAN_Data_Busoff 1;
BA_ "GenSigStartValue" SG_ 519 SC_ERR_CAN_Data_Busoff 7;
BA_ "GenSigCycleTime" SG_ 519 SC_ERR_CAN_PNHV_Stat_AR2_TOut 10;
BA_ "GenSigSendType" SG_ 519 SC_ERR_CAN_PNHV_Stat_AR2_TOut 1;
BA_ "GenSigStartValue" SG_ 519 SC_ERR_CAN_PNHV_Stat_AR2_TOut 7;
BA_ "GenSigCycleTime" SG_ 519 SC_ERR_CAN_OBL_Rq_AR2_TOut 10;
BA_ "GenSigSendType" SG_ 519 SC_ERR_CAN_OBL_Rq_AR2_TOut 1;
BA_ "GenSigStartValue" SG_ 519 SC_ERR_CAN_OBL_Rq_AR2_TOut 7;
BA_ "GenSigCycleTime" SG_ 519 SC_ERR_CAN_LBC_CANHS_R_03_TOut 10;
BA_ "GenSigSendType" SG_ 519 SC_ERR_CAN_LBC_CANHS_R_03_TOut 1;
BA_ "GenSigStartValue" SG_ 519 SC_ERR_CAN_LBC_CANHS_R_03_TOut 7;
BA_ "GenSigCycleTime" SG_ 519 SC_ERR_CAN_LBC_CANHS_R_02_TOut 10;
BA_ "GenSigSendType" SG_ 519 SC_ERR_CAN_LBC_CANHS_R_02_TOut 1;
BA_ "GenSigStartValue" SG_ 519 SC_ERR_CAN_LBC_CANHS_R_02_TOut 7;
BA_ "GenSigCycleTime" SG_ 519 SC_ERR_VCC3_Vltg_Low 10;
BA_ "GenSigSendType" SG_ 519 SC_ERR_VCC3_Vltg_Low 1;
BA_ "GenSigStartValue" SG_ 519 SC_ERR_VCC3_Vltg_Low 7;
BA_ "GenSigCycleTime" SG_ 519 SC_ERR_VCC3_Vltg_High 10;
BA_ "GenSigSendType" SG_ 519 SC_ERR_VCC3_Vltg_High 1;
BA_ "GenSigStartValue" SG_ 519 SC_ERR_VCC3_Vltg_High 7;
BA_ "GenSigCycleTime" SG_ 519 SC_ERR_VCC2_Vltg_Low 10;
BA_ "GenSigSendType" SG_ 519 SC_ERR_VCC2_Vltg_Low 1;
BA_ "GenSigStartValue" SG_ 519 SC_ERR_VCC2_Vltg_Low 7;
BA_ "GenSigCycleTime" SG_ 519 SC_ERR_VCC2_Vltg_High 10;
BA_ "GenSigSendType" SG_ 519 SC_ERR_VCC2_Vltg_High 1;
BA_ "GenSigStartValue" SG_ 519 SC_ERR_VCC2_Vltg_High 7;
BA_ "GenSigCycleTime" SG_ 519 SC_ERR_VCC1_Vltg_Low 10;
BA_ "GenSigSendType" SG_ 519 SC_ERR_VCC1_Vltg_Low 1;
BA_ "GenSigStartValue" SG_ 519 SC_ERR_VCC1_Vltg_Low 7;
BA_ "GenSigCycleTime" SG_ 519 SC_ERR_VCC1_Vltg_High 10;
BA_ "GenSigSendType" SG_ 519 SC_ERR_VCC1_Vltg_High 1;
BA_ "GenSigStartValue" SG_ 519 SC_ERR_VCC1_Vltg_High 7;
BA_ "GenSigCycleTime" SG_ 519 SC_ERR_KL30c_Vltg_Low 10;
BA_ "GenSigSendType" SG_ 519 SC_ERR_KL30c_Vltg_Low 1;
BA_ "GenSigStartValue" SG_ 519 SC_ERR_KL30c_Vltg_Low 7;
BA_ "GenSigCycleTime" SG_ 519 SC_ERR_KL30c_Vltg_High 10;
BA_ "GenSigSendType" SG_ 519 SC_ERR_KL30c_Vltg_High 1;
BA_ "GenSigStartValue" SG_ 519 SC_ERR_KL30c_Vltg_High 7;
BA_ "GenSigCycleTime" SG_ 519 SC_ERR_KL30c_Trgd 10;
BA_ "GenSigSendType" SG_ 519 SC_ERR_KL30c_Trgd 1;
BA_ "GenSigStartValue" SG_ 519 SC_ERR_KL30c_Trgd 7;
BA_ "GenSigCycleTime" SG_ 519 SC_ERR_KL30_Vltg_Low 10;
BA_ "GenSigSendType" SG_ 519 SC_ERR_KL30_Vltg_Low 1;
BA_ "GenSigStartValue" SG_ 519 SC_ERR_KL30_Vltg_Low 7;
BA_ "GenSigCycleTime" SG_ 519 SC_ERR_KL30_Vltg_High 10;
BA_ "GenSigSendType" SG_ 519 SC_ERR_KL30_Vltg_High 1;
BA_ "GenSigStartValue" SG_ 519 SC_ERR_KL30_Vltg_High 7;
BA_ "GenSigCycleTime" SG_ 519 SC_ERR_KL15_Vltg_Plaus 10;
BA_ "GenSigSendType" SG_ 519 SC_ERR_KL15_Vltg_Plaus 1;
BA_ "GenSigStartValue" SG_ 519 SC_ERR_KL15_Vltg_Plaus 7;
BA_ "GenSigCycleTime" SG_ 519 SC_ERR_KL15_Vltg_High 10;
BA_ "GenSigSendType" SG_ 519 SC_ERR_KL15_Vltg_High 1;
BA_ "GenSigStartValue" SG_ 519 SC_ERR_KL15_Vltg_High 7;
BA_ "GenSigCycleTime" SG_ 518 SC_ERR_Reserved_07_05 10;
BA_ "GenSigSendType" SG_ 518 SC_ERR_Reserved_07_05 1;
BA_ "GenSigStartValue" SG_ 518 SC_ERR_Reserved_07_05 7;
BA_ "GenSigCycleTime" SG_ 518 SC_ERR_Reserved_07_04 10;
BA_ "GenSigSendType" SG_ 518 SC_ERR_Reserved_07_04 1;
BA_ "GenSigStartValue" SG_ 518 SC_ERR_Reserved_07_04 7;
BA_ "GenSigCycleTime" SG_ 518 SC_ERR_Reserved_07_03 10;
BA_ "GenSigSendType" SG_ 518 SC_ERR_Reserved_07_03 1;
BA_ "GenSigStartValue" SG_ 518 SC_ERR_Reserved_07_03 7;
BA_ "GenSigCycleTime" SG_ 518 SC_ERR_Reserved_07_02 10;
BA_ "GenSigSendType" SG_ 518 SC_ERR_Reserved_07_02 1;
BA_ "GenSigStartValue" SG_ 518 SC_ERR_Reserved_07_02 7;
BA_ "GenSigCycleTime" SG_ 518 SC_ERR_Reserved_07_01 10;
BA_ "GenSigSendType" SG_ 518 SC_ERR_Reserved_07_01 1;
BA_ "GenSigStartValue" SG_ 518 SC_ERR_Reserved_07_01 7;
BA_ "GenSigCycleTime" SG_ 518 SC_ERR_INTLK2_OL 10;
BA_ "GenSigSendType" SG_ 518 SC_ERR_INTLK2_OL 1;
BA_ "GenSigStartValue" SG_ 518 SC_ERR_INTLK2_OL 7;
BA_ "GenSigCycleTime" SG_ 518 SC_ERR_INTLK1_OL 10;
BA_ "GenSigSendType" SG_ 518 SC_ERR_INTLK1_OL 1;
BA_ "GenSigStartValue" SG_ 518 SC_ERR_INTLK1_OL 7;
BA_ "GenSigCycleTime" SG_ 518 SC_ERR_INTLK2_Vcc_Low 10;
BA_ "GenSigSendType" SG_ 518 SC_ERR_INTLK2_Vcc_Low 1;
BA_ "GenSigStartValue" SG_ 518 SC_ERR_INTLK2_Vcc_Low 7;
BA_ "GenSigCycleTime" SG_ 518 SC_ERR_INTLK2_Vcc_High 10;
BA_ "GenSigSendType" SG_ 518 SC_ERR_INTLK2_Vcc_High 1;
BA_ "GenSigStartValue" SG_ 518 SC_ERR_INTLK2_Vcc_High 7;
BA_ "GenSigCycleTime" SG_ 518 SC_ERR_INTLK2_SCG 10;
BA_ "GenSigSendType" SG_ 518 SC_ERR_INTLK2_SCG 1;
BA_ "GenSigStartValue" SG_ 518 SC_ERR_INTLK2_SCG 7;
BA_ "GenSigCycleTime" SG_ 518 SC_ERR_INTLK2_SCB 10;
BA_ "GenSigSendType" SG_ 518 SC_ERR_INTLK2_SCB 1;
BA_ "GenSigStartValue" SG_ 518 SC_ERR_INTLK2_SCB 7;
BA_ "GenSigCycleTime" SG_ 518 SC_ERR_INTLK2_Gen_defect 10;
BA_ "GenSigSendType" SG_ 518 SC_ERR_INTLK2_Gen_defect 1;
BA_ "GenSigStartValue" SG_ 518 SC_ERR_INTLK2_Gen_defect 7;
BA_ "GenSigCycleTime" SG_ 518 SC_ERR_INTLK2_Frequency 10;
BA_ "GenSigSendType" SG_ 518 SC_ERR_INTLK2_Frequency 1;
BA_ "GenSigStartValue" SG_ 518 SC_ERR_INTLK2_Frequency 7;
BA_ "GenSigCycleTime" SG_ 518 SC_ERR_INTLK2_Duty_Cycle 10;
BA_ "GenSigSendType" SG_ 518 SC_ERR_INTLK2_Duty_Cycle 1;
BA_ "GenSigStartValue" SG_ 518 SC_ERR_INTLK2_Duty_Cycle 7;
BA_ "GenSigCycleTime" SG_ 518 SC_ERR_INTLK1_Vcc_Low 10;
BA_ "GenSigSendType" SG_ 518 SC_ERR_INTLK1_Vcc_Low 1;
BA_ "GenSigStartValue" SG_ 518 SC_ERR_INTLK1_Vcc_Low 7;
BA_ "GenSigCycleTime" SG_ 518 SC_ERR_INTLK1_Vcc_High 10;
BA_ "GenSigSendType" SG_ 518 SC_ERR_INTLK1_Vcc_High 1;
BA_ "GenSigStartValue" SG_ 518 SC_ERR_INTLK1_Vcc_High 7;
BA_ "GenSigCycleTime" SG_ 518 SC_ERR_INTLK1_SCG 10;
BA_ "GenSigSendType" SG_ 518 SC_ERR_INTLK1_SCG 1;
BA_ "GenSigStartValue" SG_ 518 SC_ERR_INTLK1_SCG 7;
BA_ "GenSigCycleTime" SG_ 518 SC_ERR_INTLK1_SCB 10;
BA_ "GenSigSendType" SG_ 518 SC_ERR_INTLK1_SCB 1;
BA_ "GenSigStartValue" SG_ 518 SC_ERR_INTLK1_SCB 7;
BA_ "GenSigCycleTime" SG_ 518 SC_ERR_INTLK1_Gen_defect 10;
BA_ "GenSigSendType" SG_ 518 SC_ERR_INTLK1_Gen_defect 1;
BA_ "GenSigStartValue" SG_ 518 SC_ERR_INTLK1_Gen_defect 7;
BA_ "GenSigCycleTime" SG_ 518 SC_ERR_INTLK1_Frequency 10;
BA_ "GenSigSendType" SG_ 518 SC_ERR_INTLK1_Frequency 1;
BA_ "GenSigStartValue" SG_ 518 SC_ERR_INTLK1_Frequency 7;
BA_ "GenSigCycleTime" SG_ 518 SC_ERR_INTLK1_Duty_Cycle 10;
BA_ "GenSigSendType" SG_ 518 SC_ERR_INTLK1_Duty_Cycle 1;
BA_ "GenSigStartValue" SG_ 518 SC_ERR_INTLK1_Duty_Cycle 7;
BA_ "GenSigCycleTime" SG_ 517 SC_ERR_Reserved_06_03 10;
BA_ "GenSigSendType" SG_ 517 SC_ERR_Reserved_06_03 1;
BA_ "GenSigStartValue" SG_ 517 SC_ERR_Reserved_06_03 7;
BA_ "GenSigCycleTime" SG_ 517 SC_ERR_Reserved_06_02 10;
BA_ "GenSigSendType" SG_ 517 SC_ERR_Reserved_06_02 1;
BA_ "GenSigStartValue" SG_ 517 SC_ERR_Reserved_06_02 7;
BA_ "GenSigCycleTime" SG_ 517 SC_ERR_Reserved_06_01 10;
BA_ "GenSigSendType" SG_ 517 SC_ERR_Reserved_06_01 1;
BA_ "GenSigStartValue" SG_ 517 SC_ERR_Reserved_06_01 7;
BA_ "GenSigCycleTime" SG_ 517 SC_ERR_MSW_Pre_Temp 10;
BA_ "GenSigSendType" SG_ 517 SC_ERR_MSW_Pre_Temp 1;
BA_ "GenSigStartValue" SG_ 517 SC_ERR_MSW_Pre_Temp 7;
BA_ "GenSigCycleTime" SG_ 517 SC_ERR_MSW_LnkVltg_High 10;
BA_ "GenSigSendType" SG_ 517 SC_ERR_MSW_LnkVltg_High 1;
BA_ "GenSigStartValue" SG_ 517 SC_ERR_MSW_LnkVltg_High 7;
BA_ "GenSigCycleTime" SG_ 517 SC_ERR_MSW_Vltg_Diff 10;
BA_ "GenSigSendType" SG_ 517 SC_ERR_MSW_Vltg_Diff 1;
BA_ "GenSigStartValue" SG_ 517 SC_ERR_MSW_Vltg_Diff 7;
BA_ "GenSigCycleTime" SG_ 517 SC_ERR_MSW_Pre_Time 10;
BA_ "GenSigSendType" SG_ 517 SC_ERR_MSW_Pre_Time 1;
BA_ "GenSigStartValue" SG_ 517 SC_ERR_MSW_Pre_Time 7;
BA_ "GenSigCycleTime" SG_ 517 SC_ERR_MSW_Pre_Crnt 10;
BA_ "GenSigSendType" SG_ 517 SC_ERR_MSW_Pre_Crnt 1;
BA_ "GenSigStartValue" SG_ 517 SC_ERR_MSW_Pre_Crnt 7;
BA_ "GenSigCycleTime" SG_ 517 SC_ERR_MSW_Pre_Stuck_Opn 10;
BA_ "GenSigSendType" SG_ 517 SC_ERR_MSW_Pre_Stuck_Opn 1;
BA_ "GenSigStartValue" SG_ 517 SC_ERR_MSW_Pre_Stuck_Opn 7;
BA_ "GenSigCycleTime" SG_ 517 SC_ERR_MSW_Pre_Stuck_Cls 10;
BA_ "GenSigSendType" SG_ 517 SC_ERR_MSW_Pre_Stuck_Cls 1;
BA_ "GenSigStartValue" SG_ 517 SC_ERR_MSW_Pre_Stuck_Cls 7;
BA_ "GenSigCycleTime" SG_ 517 SC_ERR_MSW_Plus_Stuck_Opn 10;
BA_ "GenSigStartValue" SG_ 517 SC_ERR_MSW_Plus_Stuck_Opn 7;
BA_ "GenSigSendType" SG_ 517 SC_ERR_MSW_Plus_Stuck_Opn 1;
BA_ "GenSigCycleTime" SG_ 517 SC_ERR_MSW_Plus_Stuck_Cls 10;
BA_ "GenSigStartValue" SG_ 517 SC_ERR_MSW_Plus_Stuck_Cls 7;
BA_ "GenSigSendType" SG_ 517 SC_ERR_MSW_Plus_Stuck_Cls 1;
BA_ "GenSigCycleTime" SG_ 517 SC_ERR_MSW_Minus_Stuck_Opn 10;
BA_ "GenSigStartValue" SG_ 517 SC_ERR_MSW_Minus_Stuck_Opn 7;
BA_ "GenSigSendType" SG_ 517 SC_ERR_MSW_Minus_Stuck_Opn 1;
BA_ "GenSigCycleTime" SG_ 517 SC_ERR_MSW_Minus_Stuck_Cls 10;
BA_ "GenSigStartValue" SG_ 517 SC_ERR_MSW_Minus_Stuck_Cls 7;
BA_ "GenSigSendType" SG_ 517 SC_ERR_MSW_Minus_Stuck_Cls 1;
BA_ "GenSigCycleTime" SG_ 517 SC_ERR_MSW_Pre_Ls_SCG 10;
BA_ "GenSigSendType" SG_ 517 SC_ERR_MSW_Pre_Ls_SCG 1;
BA_ "GenSigStartValue" SG_ 517 SC_ERR_MSW_Pre_Ls_SCG 7;
BA_ "GenSigCycleTime" SG_ 517 SC_ERR_MSW_Pre_Ls_SCB 10;
BA_ "GenSigSendType" SG_ 517 SC_ERR_MSW_Pre_Ls_SCB 1;
BA_ "GenSigStartValue" SG_ 517 SC_ERR_MSW_Pre_Ls_SCB 7;
BA_ "GenSigCycleTime" SG_ 517 SC_ERR_MSW_Pre_Ls_OL 10;
BA_ "GenSigSendType" SG_ 517 SC_ERR_MSW_Pre_Ls_OL 1;
BA_ "GenSigStartValue" SG_ 517 SC_ERR_MSW_Pre_Ls_OL 7;
BA_ "GenSigCycleTime" SG_ 517 SC_ERR_MSW_Pre_Hs_SCG 10;
BA_ "GenSigSendType" SG_ 517 SC_ERR_MSW_Pre_Hs_SCG 1;
BA_ "GenSigStartValue" SG_ 517 SC_ERR_MSW_Pre_Hs_SCG 7;
BA_ "GenSigCycleTime" SG_ 517 SC_ERR_MSW_Pre_Hs_SCB 10;
BA_ "GenSigSendType" SG_ 517 SC_ERR_MSW_Pre_Hs_SCB 1;
BA_ "GenSigStartValue" SG_ 517 SC_ERR_MSW_Pre_Hs_SCB 7;
BA_ "GenSigCycleTime" SG_ 517 SC_ERR_MSW_Pre_Hs_OL 10;
BA_ "GenSigSendType" SG_ 517 SC_ERR_MSW_Pre_Hs_OL 1;
BA_ "GenSigStartValue" SG_ 517 SC_ERR_MSW_Pre_Hs_OL 7;
BA_ "GenSigCycleTime" SG_ 516 SC_ERR_Reserved_05_03 10;
BA_ "GenSigSendType" SG_ 516 SC_ERR_Reserved_05_03 1;
BA_ "GenSigStartValue" SG_ 516 SC_ERR_Reserved_05_03 7;
BA_ "GenSigCycleTime" SG_ 516 SC_ERR_Reserved_05_02 10;
BA_ "GenSigSendType" SG_ 516 SC_ERR_Reserved_05_02 1;
BA_ "GenSigStartValue" SG_ 516 SC_ERR_Reserved_05_02 7;
BA_ "GenSigCycleTime" SG_ 516 SC_ERR_Reserved_05_01 10;
BA_ "GenSigSendType" SG_ 516 SC_ERR_Reserved_05_01 1;
BA_ "GenSigStartValue" SG_ 516 SC_ERR_Reserved_05_01 7;
BA_ "GenSigCycleTime" SG_ 516 SC_ERR_MSW_Plus_Ls_SCG 10;
BA_ "GenSigSendType" SG_ 516 SC_ERR_MSW_Plus_Ls_SCG 1;
BA_ "GenSigStartValue" SG_ 516 SC_ERR_MSW_Plus_Ls_SCG 7;
BA_ "GenSigCycleTime" SG_ 516 SC_ERR_MSW_Plus_Ls_SCB 10;
BA_ "GenSigSendType" SG_ 516 SC_ERR_MSW_Plus_Ls_SCB 1;
BA_ "GenSigStartValue" SG_ 516 SC_ERR_MSW_Plus_Ls_SCB 7;
BA_ "GenSigCycleTime" SG_ 516 SC_ERR_MSW_Plus_Ls_OL 10;
BA_ "GenSigSendType" SG_ 516 SC_ERR_MSW_Plus_Ls_OL 1;
BA_ "GenSigStartValue" SG_ 516 SC_ERR_MSW_Plus_Ls_OL 7;
BA_ "GenSigCycleTime" SG_ 516 SC_ERR_MSW_Plus_Hs_SCG 10;
BA_ "GenSigSendType" SG_ 516 SC_ERR_MSW_Plus_Hs_SCG 1;
BA_ "GenSigStartValue" SG_ 516 SC_ERR_MSW_Plus_Hs_SCG 7;
BA_ "GenSigCycleTime" SG_ 516 SC_ERR_MSW_Plus_Hs_SCB 10;
BA_ "GenSigSendType" SG_ 516 SC_ERR_MSW_Plus_Hs_SCB 1;
BA_ "GenSigStartValue" SG_ 516 SC_ERR_MSW_Plus_Hs_SCB 7;
BA_ "GenSigCycleTime" SG_ 516 SC_ERR_MSW_Plus_Hs_OL 10;
BA_ "GenSigSendType" SG_ 516 SC_ERR_MSW_Plus_Hs_OL 1;
BA_ "GenSigStartValue" SG_ 516 SC_ERR_MSW_Plus_Hs_OL 7;
BA_ "GenSigCycleTime" SG_ 516 SC_ERR_MSW_Minus_Ls_SCG 10;
BA_ "GenSigSendType" SG_ 516 SC_ERR_MSW_Minus_Ls_SCG 1;
BA_ "GenSigStartValue" SG_ 516 SC_ERR_MSW_Minus_Ls_SCG 7;
BA_ "GenSigCycleTime" SG_ 516 SC_ERR_MSW_Minus_Ls_SCB 10;
BA_ "GenSigSendType" SG_ 516 SC_ERR_MSW_Minus_Ls_SCB 1;
BA_ "GenSigStartValue" SG_ 516 SC_ERR_MSW_Minus_Ls_SCB 7;
BA_ "GenSigCycleTime" SG_ 516 SC_ERR_MSW_Minus_Ls_OL 10;
BA_ "GenSigSendType" SG_ 516 SC_ERR_MSW_Minus_Ls_OL 1;
BA_ "GenSigStartValue" SG_ 516 SC_ERR_MSW_Minus_Ls_OL 7;
BA_ "GenSigCycleTime" SG_ 516 SC_ERR_MSW_Minus_Hs_SCG 10;
BA_ "GenSigSendType" SG_ 516 SC_ERR_MSW_Minus_Hs_SCG 1;
BA_ "GenSigStartValue" SG_ 516 SC_ERR_MSW_Minus_Hs_SCG 7;
BA_ "GenSigCycleTime" SG_ 516 SC_ERR_MSW_Minus_Hs_SCB 10;
BA_ "GenSigSendType" SG_ 516 SC_ERR_MSW_Minus_Hs_SCB 1;
BA_ "GenSigStartValue" SG_ 516 SC_ERR_MSW_Minus_Hs_SCB 7;
BA_ "GenSigCycleTime" SG_ 516 SC_ERR_MSW_Minus_Hs_OL 10;
BA_ "GenSigSendType" SG_ 516 SC_ERR_MSW_Minus_Hs_OL 1;
BA_ "GenSigStartValue" SG_ 516 SC_ERR_MSW_Minus_Hs_OL 7;
BA_ "GenSigCycleTime" SG_ 516 SC_ERR_MSW_Aging_Pre_Warn 10;
BA_ "GenSigSendType" SG_ 516 SC_ERR_MSW_Aging_Pre_Warn 1;
BA_ "GenSigStartValue" SG_ 516 SC_ERR_MSW_Aging_Pre_Warn 7;
BA_ "GenSigCycleTime" SG_ 516 SC_ERR_MSW_Aging_Pre 10;
BA_ "GenSigSendType" SG_ 516 SC_ERR_MSW_Aging_Pre 1;
BA_ "GenSigStartValue" SG_ 516 SC_ERR_MSW_Aging_Pre 7;
BA_ "GenSigCycleTime" SG_ 516 SC_ERR_MSW_Aging_Plus_Warn 10;
BA_ "GenSigSendType" SG_ 516 SC_ERR_MSW_Aging_Plus_Warn 1;
BA_ "GenSigStartValue" SG_ 516 SC_ERR_MSW_Aging_Plus_Warn 7;
BA_ "GenSigCycleTime" SG_ 516 SC_ERR_MSW_Aging_Plus 10;
BA_ "GenSigSendType" SG_ 516 SC_ERR_MSW_Aging_Plus 1;
BA_ "GenSigStartValue" SG_ 516 SC_ERR_MSW_Aging_Plus 7;
BA_ "GenSigCycleTime" SG_ 516 SC_ERR_MSW_Aging_Minus_Warn 10;
BA_ "GenSigSendType" SG_ 516 SC_ERR_MSW_Aging_Minus_Warn 1;
BA_ "GenSigStartValue" SG_ 516 SC_ERR_MSW_Aging_Minus_Warn 7;
BA_ "GenSigCycleTime" SG_ 516 SC_ERR_MSW_Aging_Minus 10;
BA_ "GenSigSendType" SG_ 516 SC_ERR_MSW_Aging_Minus 1;
BA_ "GenSigStartValue" SG_ 516 SC_ERR_MSW_Aging_Minus 7;
BA_ "GenSigCycleTime" SG_ 515 SC_ERR_Reserved_04_03 10;
BA_ "GenSigSendType" SG_ 515 SC_ERR_Reserved_04_03 1;
BA_ "GenSigStartValue" SG_ 515 SC_ERR_Reserved_04_03 7;
BA_ "GenSigCycleTime" SG_ 515 SC_ERR_Reserved_04_02 10;
BA_ "GenSigSendType" SG_ 515 SC_ERR_Reserved_04_02 1;
BA_ "GenSigStartValue" SG_ 515 SC_ERR_Reserved_04_02 7;
BA_ "GenSigCycleTime" SG_ 515 SC_ERR_Reserved_04_01 10;
BA_ "GenSigSendType" SG_ 515 SC_ERR_Reserved_04_01 1;
BA_ "GenSigStartValue" SG_ 515 SC_ERR_Reserved_04_01 7;
BA_ "GenSigCycleTime" SG_ 515 SC_ERR_CSE1_PCB_Temp2_High 10;
BA_ "GenSigSendType" SG_ 515 SC_ERR_CSE1_PCB_Temp2_High 1;
BA_ "GenSigStartValue" SG_ 515 SC_ERR_CSE1_PCB_Temp2_High 7;
BA_ "GenSigCycleTime" SG_ 515 SC_ERR_CSE2_PCB_Temp2_RNGL 10;
BA_ "GenSigSendType" SG_ 515 SC_ERR_CSE2_PCB_Temp2_RNGL 1;
BA_ "GenSigStartValue" SG_ 515 SC_ERR_CSE2_PCB_Temp2_RNGL 7;
BA_ "GenSigCycleTime" SG_ 515 SC_ERR_CSE2_PCB_Temp2_RNGH 10;
BA_ "GenSigSendType" SG_ 515 SC_ERR_CSE2_PCB_Temp2_RNGH 1;
BA_ "GenSigStartValue" SG_ 515 SC_ERR_CSE2_PCB_Temp2_RNGH 7;
BA_ "GenSigCycleTime" SG_ 515 SC_ERR_CSE2_PCB_Temp2_High 10;
BA_ "GenSigSendType" SG_ 515 SC_ERR_CSE2_PCB_Temp2_High 1;
BA_ "GenSigStartValue" SG_ 515 SC_ERR_CSE2_PCB_Temp2_High 7;
BA_ "GenSigCycleTime" SG_ 515 SC_ERR_CSE2_PCB_Temp1_RNGL 10;
BA_ "GenSigSendType" SG_ 515 SC_ERR_CSE2_PCB_Temp1_RNGL 1;
BA_ "GenSigStartValue" SG_ 515 SC_ERR_CSE2_PCB_Temp1_RNGL 7;
BA_ "GenSigCycleTime" SG_ 515 SC_ERR_CSE2_PCB_Temp1_RNGH 10;
BA_ "GenSigSendType" SG_ 515 SC_ERR_CSE2_PCB_Temp1_RNGH 1;
BA_ "GenSigStartValue" SG_ 515 SC_ERR_CSE2_PCB_Temp1_RNGH 7;
BA_ "GenSigCycleTime" SG_ 515 SC_ERR_CSE2_PCB_Temp1_High 10;
BA_ "GenSigSendType" SG_ 515 SC_ERR_CSE2_PCB_Temp1_High 1;
BA_ "GenSigStartValue" SG_ 515 SC_ERR_CSE2_PCB_Temp1_High 7;
BA_ "GenSigCycleTime" SG_ 515 SC_ERR_CSE2_Fault_Line 10;
BA_ "GenSigSendType" SG_ 515 SC_ERR_CSE2_Fault_Line 1;
BA_ "GenSigStartValue" SG_ 515 SC_ERR_CSE2_Fault_Line 7;
BA_ "GenSigCycleTime" SG_ 515 SC_ERR_CSE2_Daisy_Chain 10;
BA_ "GenSigSendType" SG_ 515 SC_ERR_CSE2_Daisy_Chain 1;
BA_ "GenSigStartValue" SG_ 515 SC_ERR_CSE2_Daisy_Chain 7;
BA_ "GenSigCycleTime" SG_ 515 SC_ERR_CSE2_Com_TOut 10;
BA_ "GenSigSendType" SG_ 515 SC_ERR_CSE2_Com_TOut 1;
BA_ "GenSigStartValue" SG_ 515 SC_ERR_CSE2_Com_TOut 7;
BA_ "GenSigCycleTime" SG_ 515 SC_ERR_CSE1_PCB_Temp2_RNGL 10;
BA_ "GenSigSendType" SG_ 515 SC_ERR_CSE1_PCB_Temp2_RNGL 1;
BA_ "GenSigStartValue" SG_ 515 SC_ERR_CSE1_PCB_Temp2_RNGL 7;
BA_ "GenSigCycleTime" SG_ 515 SC_ERR_CSE1_PCB_Temp2_RNGH 10;
BA_ "GenSigSendType" SG_ 515 SC_ERR_CSE1_PCB_Temp2_RNGH 1;
BA_ "GenSigStartValue" SG_ 515 SC_ERR_CSE1_PCB_Temp2_RNGH 7;
BA_ "GenSigCycleTime" SG_ 515 SC_ERR_CSE1_PCB_Temp1_RNGL 10;
BA_ "GenSigSendType" SG_ 515 SC_ERR_CSE1_PCB_Temp1_RNGL 1;
BA_ "GenSigStartValue" SG_ 515 SC_ERR_CSE1_PCB_Temp1_RNGL 7;
BA_ "GenSigCycleTime" SG_ 515 SC_ERR_CSE1_PCB_Temp1_RNGH 10;
BA_ "GenSigSendType" SG_ 515 SC_ERR_CSE1_PCB_Temp1_RNGH 1;
BA_ "GenSigStartValue" SG_ 515 SC_ERR_CSE1_PCB_Temp1_RNGH 7;
BA_ "GenSigCycleTime" SG_ 515 SC_ERR_CSE1_PCB_Temp1_High 10;
BA_ "GenSigSendType" SG_ 515 SC_ERR_CSE1_PCB_Temp1_High 1;
BA_ "GenSigStartValue" SG_ 515 SC_ERR_CSE1_PCB_Temp1_High 7;
BA_ "GenSigCycleTime" SG_ 515 SC_ERR_CSE1_Fault_Line 10;
BA_ "GenSigSendType" SG_ 515 SC_ERR_CSE1_Fault_Line 1;
BA_ "GenSigStartValue" SG_ 515 SC_ERR_CSE1_Fault_Line 7;
BA_ "GenSigCycleTime" SG_ 515 SC_ERR_CSE1_Daisy_Chain 10;
BA_ "GenSigSendType" SG_ 515 SC_ERR_CSE1_Daisy_Chain 1;
BA_ "GenSigStartValue" SG_ 515 SC_ERR_CSE1_Daisy_Chain 7;
BA_ "GenSigCycleTime" SG_ 515 SC_ERR_CSE1_Com_TOut 10;
BA_ "GenSigSendType" SG_ 515 SC_ERR_CSE1_Com_TOut 1;
BA_ "GenSigStartValue" SG_ 515 SC_ERR_CSE1_Com_TOut 7;
BA_ "GenSigCycleTime" SG_ 514 SC_ERR_FUSE1_Pack_RNGL 10;
BA_ "GenSigSendType" SG_ 514 SC_ERR_FUSE1_Pack_RNGL 1;
BA_ "GenSigStartValue" SG_ 514 SC_ERR_FUSE1_Pack_RNGL 7;
BA_ "GenSigCycleTime" SG_ 514 SC_ERR_FUSE1_Pack_RNGH 10;
BA_ "GenSigSendType" SG_ 514 SC_ERR_FUSE1_Pack_RNGH 1;
BA_ "GenSigStartValue" SG_ 514 SC_ERR_FUSE1_Pack_RNGH 7;
BA_ "GenSigCycleTime" SG_ 514 SC_ERR_FUSE1_Pack_OL 10;
BA_ "GenSigSendType" SG_ 514 SC_ERR_FUSE1_Pack_OL 1;
BA_ "GenSigStartValue" SG_ 514 SC_ERR_FUSE1_Pack_OL 7;
BA_ "GenSigCycleTime" SG_ 514 SC_ERR_FUSE1_Link_RNGL 10;
BA_ "GenSigSendType" SG_ 514 SC_ERR_FUSE1_Link_RNGL 1;
BA_ "GenSigStartValue" SG_ 514 SC_ERR_FUSE1_Link_RNGL 7;
BA_ "GenSigCycleTime" SG_ 514 SC_ERR_FUSE1_Link_RNGH 10;
BA_ "GenSigSendType" SG_ 514 SC_ERR_FUSE1_Link_RNGH 1;
BA_ "GenSigStartValue" SG_ 514 SC_ERR_FUSE1_Link_RNGH 7;
BA_ "GenSigCycleTime" SG_ 514 SC_ERR_FUSE1_Link_OL 10;
BA_ "GenSigSendType" SG_ 514 SC_ERR_FUSE1_Link_OL 1;
BA_ "GenSigStartValue" SG_ 514 SC_ERR_FUSE1_Link_OL 7;
BA_ "GenSigCycleTime" SG_ 514 SC_ERR_FUSE1_Blown 10;
BA_ "GenSigSendType" SG_ 514 SC_ERR_FUSE1_Blown 1;
BA_ "GenSigStartValue" SG_ 514 SC_ERR_FUSE1_Blown 7;
BA_ "GenSigCycleTime" SG_ 514 SC_ERR_PCK_Vltg_RNGL 10;
BA_ "GenSigSendType" SG_ 514 SC_ERR_PCK_Vltg_RNGL 1;
BA_ "GenSigStartValue" SG_ 514 SC_ERR_PCK_Vltg_RNGL 7;
BA_ "GenSigCycleTime" SG_ 514 SC_ERR_PCK_Vltg_RNGH 10;
BA_ "GenSigSendType" SG_ 514 SC_ERR_PCK_Vltg_RNGH 1;
BA_ "GenSigStartValue" SG_ 514 SC_ERR_PCK_Vltg_RNGH 7;
BA_ "GenSigCycleTime" SG_ 514 SC_ERR_PCK_Vltg_Plaus 10;
BA_ "GenSigSendType" SG_ 514 SC_ERR_PCK_Vltg_Plaus 1;
BA_ "GenSigStartValue" SG_ 514 SC_ERR_PCK_Vltg_Plaus 7;
BA_ "GenSigCycleTime" SG_ 514 SC_ERR_PCK_Vltg_OL 10;
BA_ "GenSigSendType" SG_ 514 SC_ERR_PCK_Vltg_OL 1;
BA_ "GenSigStartValue" SG_ 514 SC_ERR_PCK_Vltg_OL 7;
BA_ "GenSigCycleTime" SG_ 514 SC_ERR_LNK_Vltg_RNGL 10;
BA_ "GenSigSendType" SG_ 514 SC_ERR_LNK_Vltg_RNGL 1;
BA_ "GenSigStartValue" SG_ 514 SC_ERR_LNK_Vltg_RNGL 7;
BA_ "GenSigCycleTime" SG_ 514 SC_ERR_LNK_Vltg_RNGH 10;
BA_ "GenSigSendType" SG_ 514 SC_ERR_LNK_Vltg_RNGH 1;
BA_ "GenSigStartValue" SG_ 514 SC_ERR_LNK_Vltg_RNGH 7;
BA_ "GenSigCycleTime" SG_ 514 SC_ERR_LNK_Vltg_OL 10;
BA_ "GenSigSendType" SG_ 514 SC_ERR_LNK_Vltg_OL 1;
BA_ "GenSigStartValue" SG_ 514 SC_ERR_LNK_Vltg_OL 7;
BA_ "GenSigCycleTime" SG_ 514 SC_ERR_FUSE2_Pack_RNGL 10;
BA_ "GenSigSendType" SG_ 514 SC_ERR_FUSE2_Pack_RNGL 1;
BA_ "GenSigStartValue" SG_ 514 SC_ERR_FUSE2_Pack_RNGL 7;
BA_ "GenSigCycleTime" SG_ 514 SC_ERR_FUSE2_Pack_RNGH 10;
BA_ "GenSigSendType" SG_ 514 SC_ERR_FUSE2_Pack_RNGH 1;
BA_ "GenSigStartValue" SG_ 514 SC_ERR_FUSE2_Pack_RNGH 7;
BA_ "GenSigCycleTime" SG_ 514 SC_ERR_FUSE2_Pack_OL 10;
BA_ "GenSigSendType" SG_ 514 SC_ERR_FUSE2_Pack_OL 1;
BA_ "GenSigStartValue" SG_ 514 SC_ERR_FUSE2_Pack_OL 7;
BA_ "GenSigCycleTime" SG_ 514 SC_ERR_FUSE2_Link_RNGL 10;
BA_ "GenSigSendType" SG_ 514 SC_ERR_FUSE2_Link_RNGL 1;
BA_ "GenSigStartValue" SG_ 514 SC_ERR_FUSE2_Link_RNGL 7;
BA_ "GenSigCycleTime" SG_ 514 SC_ERR_FUSE2_Link_RNGH 10;
BA_ "GenSigSendType" SG_ 514 SC_ERR_FUSE2_Link_RNGH 1;
BA_ "GenSigStartValue" SG_ 514 SC_ERR_FUSE2_Link_RNGH 7;
BA_ "GenSigCycleTime" SG_ 514 SC_ERR_FUSE2_Link_OL 10;
BA_ "GenSigSendType" SG_ 514 SC_ERR_FUSE2_Link_OL 1;
BA_ "GenSigStartValue" SG_ 514 SC_ERR_FUSE2_Link_OL 7;
BA_ "GenSigCycleTime" SG_ 514 SC_ERR_FUSE2_Blown 10;
BA_ "GenSigSendType" SG_ 514 SC_ERR_FUSE2_Blown 1;
BA_ "GenSigStartValue" SG_ 514 SC_ERR_FUSE2_Blown 7;
BA_ "GenSigCycleTime" SG_ 513 SC_ERR_Reserved_02_04 10;
BA_ "GenSigSendType" SG_ 513 SC_ERR_Reserved_02_04 1;
BA_ "GenSigStartValue" SG_ 513 SC_ERR_Reserved_02_04 7;
BA_ "GenSigCycleTime" SG_ 513 SC_ERR_Reserved_02_03 10;
BA_ "GenSigSendType" SG_ 513 SC_ERR_Reserved_02_03 1;
BA_ "GenSigStartValue" SG_ 513 SC_ERR_Reserved_02_03 7;
BA_ "GenSigCycleTime" SG_ 513 SC_ERR_Reserved_02_02 10;
BA_ "GenSigSendType" SG_ 513 SC_ERR_Reserved_02_02 1;
BA_ "GenSigStartValue" SG_ 513 SC_ERR_Reserved_02_02 7;
BA_ "GenSigCycleTime" SG_ 513 SC_ERR_Reserved_02_01 10;
BA_ "GenSigSendType" SG_ 513 SC_ERR_Reserved_02_01 1;
BA_ "GenSigStartValue" SG_ 513 SC_ERR_Reserved_02_01 7;
BA_ "GenSigCycleTime" SG_ 513 SC_ERR_CSM1_Temp_High 10;
BA_ "GenSigSendType" SG_ 513 SC_ERR_CSM1_Temp_High 1;
BA_ "GenSigStartValue" SG_ 513 SC_ERR_CSM1_Temp_High 7;
BA_ "GenSigCycleTime" SG_ 513 SC_ERR_CSM1_ROM 10;
BA_ "GenSigSendType" SG_ 513 SC_ERR_CSM1_ROM 1;
BA_ "GenSigStartValue" SG_ 513 SC_ERR_CSM1_ROM 7;
BA_ "GenSigCycleTime" SG_ 513 SC_ERR_CSM1_FUSI_CrntDischrgHigh 10;
BA_ "GenSigSendType" SG_ 513 SC_ERR_CSM1_FUSI_CrntDischrgHigh 1;
BA_ "GenSigStartValue" SG_ 513 SC_ERR_CSM1_FUSI_CrntDischrgHigh 7;
BA_ "GenSigCycleTime" SG_ 513 SC_ERR_CSM1_FUSI_Crnt_Chrg_High 10;
BA_ "GenSigSendType" SG_ 513 SC_ERR_CSM1_FUSI_Crnt_Chrg_High 1;
BA_ "GenSigStartValue" SG_ 513 SC_ERR_CSM1_FUSI_Crnt_Chrg_High 7;
BA_ "GenSigCycleTime" SG_ 513 SC_ERR_CSM1_Crnt_Dischrg_RNGL 10;
BA_ "GenSigSendType" SG_ 513 SC_ERR_CSM1_Crnt_Dischrg_RNGL 1;
BA_ "GenSigStartValue" SG_ 513 SC_ERR_CSM1_Crnt_Dischrg_RNGL 7;
BA_ "GenSigCycleTime" SG_ 513 SC_ERR_CSM1_Crnt_Chrg_RNGH 10;
BA_ "GenSigSendType" SG_ 513 SC_ERR_CSM1_Crnt_Chrg_RNGH 1;
BA_ "GenSigStartValue" SG_ 513 SC_ERR_CSM1_Crnt_Chrg_RNGH 7;
BA_ "GenSigCycleTime" SG_ 513 SC_ERR_CSM1_Com_TOut 10;
BA_ "GenSigSendType" SG_ 513 SC_ERR_CSM1_Com_TOut 1;
BA_ "GenSigStartValue" SG_ 513 SC_ERR_CSM1_Com_TOut 7;
BA_ "GenSigCycleTime" SG_ 513 SC_ERR_CSM_Plaus 10;
BA_ "GenSigSendType" SG_ 513 SC_ERR_CSM_Plaus 1;
BA_ "GenSigStartValue" SG_ 513 SC_ERR_CSM_Plaus 7;
BA_ "GenSigCycleTime" SG_ 513 SC_ERR_CSM1_General 10;
BA_ "GenSigSendType" SG_ 513 SC_ERR_CSM1_General 1;
BA_ "GenSigStartValue" SG_ 513 SC_ERR_CSM1_General 7;
BA_ "GenSigCycleTime" SG_ 513 SC_ERR_CSM2_SCG 10;
BA_ "GenSigSendType" SG_ 513 SC_ERR_CSM2_SCG 1;
BA_ "GenSigStartValue" SG_ 513 SC_ERR_CSM2_SCG 7;
BA_ "GenSigCycleTime" SG_ 513 SC_ERR_CSM2_SCB 10;
BA_ "GenSigSendType" SG_ 513 SC_ERR_CSM2_SCB 1;
BA_ "GenSigStartValue" SG_ 513 SC_ERR_CSM2_SCB 7;
BA_ "GenSigCycleTime" SG_ 513 SC_ERR_CSM2_ROM 10;
BA_ "GenSigSendType" SG_ 513 SC_ERR_CSM2_ROM 1;
BA_ "GenSigStartValue" SG_ 513 SC_ERR_CSM2_ROM 7;
BA_ "GenSigCycleTime" SG_ 513 SC_ERR_CSM2_OL 10;
BA_ "GenSigSendType" SG_ 513 SC_ERR_CSM2_OL 1;
BA_ "GenSigStartValue" SG_ 513 SC_ERR_CSM2_OL 7;
BA_ "GenSigCycleTime" SG_ 513 SC_ERR_CSM2_FUSI_CrntDischrgHigh 10;
BA_ "GenSigSendType" SG_ 513 SC_ERR_CSM2_FUSI_CrntDischrgHigh 1;
BA_ "GenSigStartValue" SG_ 513 SC_ERR_CSM2_FUSI_CrntDischrgHigh 7;
BA_ "GenSigCycleTime" SG_ 513 SC_ERR_CSM2_FUSI_Crnt_Chrg_High 10;
BA_ "GenSigSendType" SG_ 513 SC_ERR_CSM2_FUSI_Crnt_Chrg_High 1;
BA_ "GenSigStartValue" SG_ 513 SC_ERR_CSM2_FUSI_Crnt_Chrg_High 7;
BA_ "GenSigCycleTime" SG_ 513 SC_ERR_CSM2_Crnt_Dischrg_RNGL 10;
BA_ "GenSigSendType" SG_ 513 SC_ERR_CSM2_Crnt_Dischrg_RNGL 1;
BA_ "GenSigStartValue" SG_ 513 SC_ERR_CSM2_Crnt_Dischrg_RNGL 7;
BA_ "GenSigCycleTime" SG_ 513 SC_ERR_CSM2_Crnt_Chrg_RNGH 10;
BA_ "GenSigSendType" SG_ 513 SC_ERR_CSM2_Crnt_Chrg_RNGH 1;
BA_ "GenSigStartValue" SG_ 513 SC_ERR_CSM2_Crnt_Chrg_RNGH 7;
BA_ "GenSigCycleTime" SG_ 512 SC_ERR_CELLBLOCK3_Modul_Vltg_RAT 10;
BA_ "GenSigSendType" SG_ 512 SC_ERR_CELLBLOCK3_Modul_Vltg_RAT 1;
BA_ "GenSigStartValue" SG_ 512 SC_ERR_CELLBLOCK3_Modul_Vltg_RAT 7;
BA_ "GenSigCycleTime" SG_ 512 SC_ERR_CELLBLOCK2_Modul_Vltg_RAT 10;
BA_ "GenSigSendType" SG_ 512 SC_ERR_CELLBLOCK2_Modul_Vltg_RAT 1;
BA_ "GenSigStartValue" SG_ 512 SC_ERR_CELLBLOCK2_Modul_Vltg_RAT 7;
BA_ "GenSigCycleTime" SG_ 512 SC_ERR_CELLBLOCK1_Modul_Vltg_RAT 10;
BA_ "GenSigSendType" SG_ 512 SC_ERR_CELLBLOCK1_Modul_Vltg_RAT 1;
BA_ "GenSigStartValue" SG_ 512 SC_ERR_CELLBLOCK1_Modul_Vltg_RAT 7;
BA_ "GenSigCycleTime" SG_ 512 SC_ERR_CELLBLOCK3_UnderVltg_Warn 10;
BA_ "GenSigSendType" SG_ 512 SC_ERR_CELLBLOCK3_UnderVltg_Warn 1;
BA_ "GenSigStartValue" SG_ 512 SC_ERR_CELLBLOCK3_UnderVltg_Warn 7;
BA_ "GenSigCycleTime" SG_ 512 SC_ERR_CELLBLOCK2_UnderVltg_Warn 10;
BA_ "GenSigSendType" SG_ 512 SC_ERR_CELLBLOCK2_UnderVltg_Warn 1;
BA_ "GenSigStartValue" SG_ 512 SC_ERR_CELLBLOCK2_UnderVltg_Warn 7;
BA_ "GenSigCycleTime" SG_ 512 SC_ERR_CELLBLOCK1_UnderVltg_Warn 10;
BA_ "GenSigSendType" SG_ 512 SC_ERR_CELLBLOCK1_UnderVltg_Warn 1;
BA_ "GenSigStartValue" SG_ 512 SC_ERR_CELLBLOCK1_UnderVltg_Warn 7;
BA_ "GenSigCycleTime" SG_ 512 SC_ERR_CELLBLOCK3_OverVltg_Warn 10;
BA_ "GenSigSendType" SG_ 512 SC_ERR_CELLBLOCK3_OverVltg_Warn 1;
BA_ "GenSigStartValue" SG_ 512 SC_ERR_CELLBLOCK3_OverVltg_Warn 7;
BA_ "GenSigCycleTime" SG_ 512 SC_ERR_CELLBLOCK2_OverVltg_Warn 10;
BA_ "GenSigSendType" SG_ 512 SC_ERR_CELLBLOCK2_OverVltg_Warn 1;
BA_ "GenSigStartValue" SG_ 512 SC_ERR_CELLBLOCK2_OverVltg_Warn 7;
BA_ "GenSigCycleTime" SG_ 512 SC_ERR_CELLBLOCK1_OverVltg_Warn 10;
BA_ "GenSigSendType" SG_ 512 SC_ERR_CELLBLOCK1_OverVltg_Warn 1;
BA_ "GenSigStartValue" SG_ 512 SC_ERR_CELLBLOCK1_OverVltg_Warn 7;
BA_ "GenSigCycleTime" SG_ 512 SC_ERR_CELLBLOCK3_FUSI_UnderVltg 10;
BA_ "GenSigSendType" SG_ 512 SC_ERR_CELLBLOCK3_FUSI_UnderVltg 1;
BA_ "GenSigStartValue" SG_ 512 SC_ERR_CELLBLOCK3_FUSI_UnderVltg 7;
BA_ "GenSigCycleTime" SG_ 512 SC_ERR_CELLBLOCK2_FUSI_UnderVltg 10;
BA_ "GenSigSendType" SG_ 512 SC_ERR_CELLBLOCK2_FUSI_UnderVltg 1;
BA_ "GenSigStartValue" SG_ 512 SC_ERR_CELLBLOCK2_FUSI_UnderVltg 7;
BA_ "GenSigCycleTime" SG_ 512 SC_ERR_CELLBLOCK1_FUSI_UnderVltg 10;
BA_ "GenSigSendType" SG_ 512 SC_ERR_CELLBLOCK1_FUSI_UnderVltg 1;
BA_ "GenSigStartValue" SG_ 512 SC_ERR_CELLBLOCK1_FUSI_UnderVltg 7;
BA_ "GenSigCycleTime" SG_ 512 SC_ERR_CELLBLOCK3_FUSI_OverVltg 10;
BA_ "GenSigSendType" SG_ 512 SC_ERR_CELLBLOCK3_FUSI_OverVltg 1;
BA_ "GenSigStartValue" SG_ 512 SC_ERR_CELLBLOCK3_FUSI_OverVltg 7;
BA_ "GenSigCycleTime" SG_ 512 SC_ERR_CELLBLOCK2_FUSI_OverVltg 10;
BA_ "GenSigSendType" SG_ 512 SC_ERR_CELLBLOCK2_FUSI_OverVltg 1;
BA_ "GenSigStartValue" SG_ 512 SC_ERR_CELLBLOCK2_FUSI_OverVltg 7;
BA_ "GenSigCycleTime" SG_ 512 SC_ERR_CELLBLOCK1_FUSI_OverVltg 10;
BA_ "GenSigSendType" SG_ 512 SC_ERR_CELLBLOCK1_FUSI_OverVltg 1;
BA_ "GenSigStartValue" SG_ 512 SC_ERR_CELLBLOCK1_FUSI_OverVltg 7;
BA_ "GenSigCycleTime" SG_ 512 SC_ERR_CELLBLOCK3_FUSI_OverTemp 10;
BA_ "GenSigSendType" SG_ 512 SC_ERR_CELLBLOCK3_FUSI_OverTemp 1;
BA_ "GenSigStartValue" SG_ 512 SC_ERR_CELLBLOCK3_FUSI_OverTemp 7;
BA_ "GenSigCycleTime" SG_ 512 SC_ERR_CELLBLOCK2_FUSI_OverTemp 10;
BA_ "GenSigSendType" SG_ 512 SC_ERR_CELLBLOCK2_FUSI_OverTemp 1;
BA_ "GenSigStartValue" SG_ 512 SC_ERR_CELLBLOCK2_FUSI_OverTemp 7;
BA_ "GenSigCycleTime" SG_ 512 SC_ERR_CELLBLOCK1_FUSI_OverTemp 10;
BA_ "GenSigSendType" SG_ 512 SC_ERR_CELLBLOCK1_FUSI_OverTemp 1;
BA_ "GenSigStartValue" SG_ 512 SC_ERR_CELLBLOCK1_FUSI_OverTemp 7;
BA_ "GenSigCycleTime" SG_ 512 SC_ERR_CELLBLOCK3_FUSI_Open_Line 10;
BA_ "GenSigSendType" SG_ 512 SC_ERR_CELLBLOCK3_FUSI_Open_Line 1;
BA_ "GenSigStartValue" SG_ 512 SC_ERR_CELLBLOCK3_FUSI_Open_Line 7;
BA_ "GenSigCycleTime" SG_ 512 SC_ERR_CELLBLOCK2_FUSI_Open_Line 10;
BA_ "GenSigSendType" SG_ 512 SC_ERR_CELLBLOCK2_FUSI_Open_Line 1;
BA_ "GenSigStartValue" SG_ 512 SC_ERR_CELLBLOCK2_FUSI_Open_Line 7;
BA_ "GenSigCycleTime" SG_ 512 SC_ERR_CELLBLOCK1_FUSI_Open_Line 10;
BA_ "GenSigSendType" SG_ 512 SC_ERR_CELLBLOCK1_FUSI_Open_Line 1;
BA_ "GenSigStartValue" SG_ 512 SC_ERR_CELLBLOCK1_FUSI_Open_Line 7;
BA_ "GenSigCycleTime" SG_ 321 BCC_T_Batt_30 100;
BA_ "GenSigSendType" SG_ 321 BCC_T_Batt_30 1;
BA_ "GenSigStartValue" SG_ 321 BCC_T_Batt_30 2500;
BA_ "GenSigCycleTime" SG_ 321 BCC_T_Batt_29 100;
BA_ "GenSigSendType" SG_ 321 BCC_T_Batt_29 1;
BA_ "GenSigStartValue" SG_ 321 BCC_T_Batt_29 2500;
BA_ "GenSigCycleTime" SG_ 320 BCC_T_Batt_28 100;
BA_ "GenSigSendType" SG_ 320 BCC_T_Batt_28 1;
BA_ "GenSigStartValue" SG_ 320 BCC_T_Batt_28 2500;
BA_ "GenSigCycleTime" SG_ 320 BCC_T_Batt_27 100;
BA_ "GenSigSendType" SG_ 320 BCC_T_Batt_27 1;
BA_ "GenSigStartValue" SG_ 320 BCC_T_Batt_27 2500;
BA_ "GenSigCycleTime" SG_ 319 BCC_T_Batt_26 100;
BA_ "GenSigSendType" SG_ 319 BCC_T_Batt_26 1;
BA_ "GenSigStartValue" SG_ 319 BCC_T_Batt_26 2500;
BA_ "GenSigCycleTime" SG_ 319 BCC_T_Batt_25 100;
BA_ "GenSigSendType" SG_ 319 BCC_T_Batt_25 1;
BA_ "GenSigStartValue" SG_ 319 BCC_T_Batt_25 2500;
BA_ "GenSigCycleTime" SG_ 318 BCC_T_Batt_24 100;
BA_ "GenSigSendType" SG_ 318 BCC_T_Batt_24 1;
BA_ "GenSigStartValue" SG_ 318 BCC_T_Batt_24 2500;
BA_ "GenSigCycleTime" SG_ 318 BCC_T_Batt_23 100;
BA_ "GenSigSendType" SG_ 318 BCC_T_Batt_23 1;
BA_ "GenSigStartValue" SG_ 318 BCC_T_Batt_23 2500;
BA_ "GenSigCycleTime" SG_ 317 BCC_T_Batt_22 100;
BA_ "GenSigSendType" SG_ 317 BCC_T_Batt_22 1;
BA_ "GenSigStartValue" SG_ 317 BCC_T_Batt_22 2500;
BA_ "GenSigCycleTime" SG_ 317 BCC_T_Batt_21 100;
BA_ "GenSigSendType" SG_ 317 BCC_T_Batt_21 1;
BA_ "GenSigStartValue" SG_ 317 BCC_T_Batt_21 2500;
BA_ "GenSigCycleTime" SG_ 316 BCC_T_Batt_20 100;
BA_ "GenSigSendType" SG_ 316 BCC_T_Batt_20 1;
BA_ "GenSigStartValue" SG_ 316 BCC_T_Batt_20 2500;
BA_ "GenSigCycleTime" SG_ 316 BCC_T_Batt_19 100;
BA_ "GenSigSendType" SG_ 316 BCC_T_Batt_19 1;
BA_ "GenSigStartValue" SG_ 316 BCC_T_Batt_19 2500;
BA_ "GenSigCycleTime" SG_ 315 BCC_T_Batt_18 100;
BA_ "GenSigSendType" SG_ 315 BCC_T_Batt_18 1;
BA_ "GenSigStartValue" SG_ 315 BCC_T_Batt_18 2500;
BA_ "GenSigCycleTime" SG_ 315 BCC_T_Batt_17 100;
BA_ "GenSigSendType" SG_ 315 BCC_T_Batt_17 1;
BA_ "GenSigStartValue" SG_ 315 BCC_T_Batt_17 2500;
BA_ "GenSigCycleTime" SG_ 314 BCC_T_Batt_16 100;
BA_ "GenSigSendType" SG_ 314 BCC_T_Batt_16 1;
BA_ "GenSigStartValue" SG_ 314 BCC_T_Batt_16 2500;
BA_ "GenSigCycleTime" SG_ 314 BCC_T_Batt_15 100;
BA_ "GenSigSendType" SG_ 314 BCC_T_Batt_15 1;
BA_ "GenSigStartValue" SG_ 314 BCC_T_Batt_15 2500;
BA_ "GenSigCycleTime" SG_ 313 BCC_T_Batt_14 100;
BA_ "GenSigSendType" SG_ 313 BCC_T_Batt_14 1;
BA_ "GenSigStartValue" SG_ 313 BCC_T_Batt_14 2500;
BA_ "GenSigCycleTime" SG_ 313 BCC_T_Batt_13 100;
BA_ "GenSigSendType" SG_ 313 BCC_T_Batt_13 1;
BA_ "GenSigStartValue" SG_ 313 BCC_T_Batt_13 2500;
BA_ "GenSigCycleTime" SG_ 312 BCC_T_Batt_12 100;
BA_ "GenSigSendType" SG_ 312 BCC_T_Batt_12 1;
BA_ "GenSigStartValue" SG_ 312 BCC_T_Batt_12 2500;
BA_ "GenSigCycleTime" SG_ 312 BCC_T_Batt_11 100;
BA_ "GenSigSendType" SG_ 312 BCC_T_Batt_11 1;
BA_ "GenSigStartValue" SG_ 312 BCC_T_Batt_11 2500;
BA_ "GenSigCycleTime" SG_ 524 SSV_Version_DS_CRC 10;
BA_ "GenSigSendType" SG_ 524 SSV_Version_DS_CRC 1;
BA_ "GenSigCycleTime" SG_ 524 SSV_Version_Release 10;
BA_ "GenSigSendType" SG_ 524 SSV_Version_Release 1;
BA_ "GenSigCycleTime" SG_ 524 SSV_Version_Minor 10;
BA_ "GenSigSendType" SG_ 524 SSV_Version_Minor 1;
BA_ "GenSigCycleTime" SG_ 524 SSV_Version_Major 10;
BA_ "GenSigSendType" SG_ 524 SSV_Version_Major 1;
BA_ "GenSigCycleTime" SG_ 768 CSM_Version_DS_CRC 1000;
BA_ "GenSigSendType" SG_ 768 CSM_Version_DS_CRC 1;
BA_ "GenSigCycleTime" SG_ 768 CSM_Version_Release 1000;
BA_ "GenSigSendType" SG_ 768 CSM_Version_Release 1;
BA_ "GenSigCycleTime" SG_ 768 CSM_Version_Minor 1000;
BA_ "GenSigSendType" SG_ 768 CSM_Version_Minor 1;
BA_ "GenSigCycleTime" SG_ 768 CSM_Version_Major 1000;
BA_ "GenSigSendType" SG_ 768 CSM_Version_Major 1;
BA_ "GenSigCycleTime" SG_ 852 CSE03_Version_DS_CRC 1000;
BA_ "GenSigSendType" SG_ 852 CSE03_Version_DS_CRC 1;
BA_ "GenSigCycleTime" SG_ 852 CSE03_Version_Release 1000;
BA_ "GenSigSendType" SG_ 852 CSE03_Version_Release 1;
BA_ "GenSigCycleTime" SG_ 852 CSE03_Version_Minor 1000;
BA_ "GenSigSendType" SG_ 852 CSE03_Version_Minor 1;
BA_ "GenSigCycleTime" SG_ 852 CSE03_Version_Major 1000;
BA_ "GenSigSendType" SG_ 852 CSE03_Version_Major 1;
BA_ "GenSigCycleTime" SG_ 850 CSE02_Version_DS_CRC 1000;
BA_ "GenSigSendType" SG_ 850 CSE02_Version_DS_CRC 1;
BA_ "GenSigCycleTime" SG_ 850 CSE02_Version_Release 1000;
BA_ "GenSigSendType" SG_ 850 CSE02_Version_Release 1;
BA_ "GenSigCycleTime" SG_ 850 CSE02_Version_Minor 1000;
BA_ "GenSigSendType" SG_ 850 CSE02_Version_Minor 1;
BA_ "GenSigCycleTime" SG_ 850 CSE02_Version_Major 1000;
BA_ "GenSigSendType" SG_ 850 CSE02_Version_Major 1;
BA_ "GenSigCycleTime" SG_ 848 CSE01_Version_DS_CRC 1000;
BA_ "GenSigSendType" SG_ 848 CSE01_Version_DS_CRC 1;
BA_ "GenSigCycleTime" SG_ 848 CSE01_Version_Release 1000;
BA_ "GenSigSendType" SG_ 848 CSE01_Version_Release 1;
BA_ "GenSigCycleTime" SG_ 848 CSE01_Version_Minor 1000;
BA_ "GenSigSendType" SG_ 848 CSE01_Version_Minor 1;
BA_ "GenSigCycleTime" SG_ 848 CSE01_Version_Major 1000;
BA_ "GenSigSendType" SG_ 848 CSE01_Version_Major 1;
BA_ "GenSigCycleTime" SG_ 311 BCC_T_Batt_10 100;
BA_ "GenSigSendType" SG_ 311 BCC_T_Batt_10 1;
BA_ "GenSigStartValue" SG_ 311 BCC_T_Batt_10 2500;
BA_ "GenSigCycleTime" SG_ 311 BCC_T_Batt_09 100;
BA_ "GenSigSendType" SG_ 311 BCC_T_Batt_09 1;
BA_ "GenSigStartValue" SG_ 311 BCC_T_Batt_09 2500;
BA_ "GenSigCycleTime" SG_ 310 BCC_T_Batt_08 100;
BA_ "GenSigSendType" SG_ 310 BCC_T_Batt_08 1;
BA_ "GenSigStartValue" SG_ 310 BCC_T_Batt_08 2500;
BA_ "GenSigCycleTime" SG_ 310 BCC_T_Batt_07 100;
BA_ "GenSigSendType" SG_ 310 BCC_T_Batt_07 1;
BA_ "GenSigStartValue" SG_ 310 BCC_T_Batt_07 2500;
BA_ "GenSigCycleTime" SG_ 853 CSE03_E_063 10;
BA_ "GenSigSendType" SG_ 853 CSE03_E_063 1;
BA_ "GenSigCycleTime" SG_ 853 CSE03_E_062 10;
BA_ "GenSigSendType" SG_ 853 CSE03_E_062 1;
BA_ "GenSigCycleTime" SG_ 853 CSE03_E_061 10;
BA_ "GenSigSendType" SG_ 853 CSE03_E_061 1;
BA_ "GenSigCycleTime" SG_ 853 CSE03_E_060 10;
BA_ "GenSigSendType" SG_ 853 CSE03_E_060 1;
BA_ "GenSigCycleTime" SG_ 853 CSE03_E_059 10;
BA_ "GenSigSendType" SG_ 853 CSE03_E_059 1;
BA_ "GenSigCycleTime" SG_ 853 CSE03_E_058 10;
BA_ "GenSigSendType" SG_ 853 CSE03_E_058 1;
BA_ "GenSigCycleTime" SG_ 853 CSE03_E_057 10;
BA_ "GenSigSendType" SG_ 853 CSE03_E_057 1;
BA_ "GenSigCycleTime" SG_ 853 CSE03_E_056_FST_ROM 10;
BA_ "GenSigSendType" SG_ 853 CSE03_E_056_FST_ROM 1;
BA_ "GenSigCycleTime" SG_ 853 CSE03_E_055_FST_RAM_SECTION_2 10;
BA_ "GenSigSendType" SG_ 853 CSE03_E_055_FST_RAM_SECTION_2 1;
BA_ "GenSigCycleTime" SG_ 853 CSE03_E_054_FST_RAM_SECTION_1 10;
BA_ "GenSigSendType" SG_ 853 CSE03_E_054_FST_RAM_SECTION_1 1;
BA_ "GenSigCycleTime" SG_ 853 CSE03_E_053_FST_RAM_STARTUP 10;
BA_ "GenSigSendType" SG_ 853 CSE03_E_053_FST_RAM_STARTUP 1;
BA_ "GenSigCycleTime" SG_ 853 CSE03_E_052_FST_CPU 10;
BA_ "GenSigSendType" SG_ 853 CSE03_E_052_FST_CPU 1;
BA_ "GenSigCycleTime" SG_ 853 CSE03_E_051_FST_RESET 10;
BA_ "GenSigSendType" SG_ 853 CSE03_E_051_FST_RESET 1;
BA_ "GenSigCycleTime" SG_ 853 CSE03_E_050_FST_INTERRUPT 10;
BA_ "GenSigSendType" SG_ 853 CSE03_E_050_FST_INTERRUPT 1;
BA_ "GenSigCycleTime" SG_ 853 CSE03_E_049_FST_STACK 10;
BA_ "GenSigSendType" SG_ 853 CSE03_E_049_FST_STACK 1;
BA_ "GenSigCycleTime" SG_ 853 CSE03_E_048_FST_LTC6801 10;
BA_ "GenSigSendType" SG_ 853 CSE03_E_048_FST_LTC6801 1;
BA_ "GenSigCycleTime" SG_ 853 CSE03_E_047 10;
BA_ "GenSigSendType" SG_ 853 CSE03_E_047 1;
BA_ "GenSigCycleTime" SG_ 853 CSE03_E_046 10;
BA_ "GenSigSendType" SG_ 853 CSE03_E_046 1;
BA_ "GenSigCycleTime" SG_ 853 CSE03_E_045 10;
BA_ "GenSigSendType" SG_ 853 CSE03_E_045 1;
BA_ "GenSigCycleTime" SG_ 853 CSE03_E_044_CAN_SEND_SEQ 10;
BA_ "GenSigSendType" SG_ 853 CSE03_E_044_CAN_SEND_SEQ 1;
BA_ "GenSigCycleTime" SG_ 853 CSE03_E_043_CAN_BUFFER_FULL 10;
BA_ "GenSigSendType" SG_ 853 CSE03_E_043_CAN_BUFFER_FULL 1;
BA_ "GenSigCycleTime" SG_ 853 CSE03_E_042 10;
BA_ "GenSigSendType" SG_ 853 CSE03_E_042 1;
BA_ "GenSigCycleTime" SG_ 853 CSE03_E_041 10;
BA_ "GenSigSendType" SG_ 853 CSE03_E_041 1;
BA_ "GenSigCycleTime" SG_ 853 CSE03_E_040_FLASH_READ_PROD 10;
BA_ "GenSigSendType" SG_ 853 CSE03_E_040_FLASH_READ_PROD 1;
BA_ "GenSigCycleTime" SG_ 853 CSE03_E_039_FLASH_CRC_PROD 10;
BA_ "GenSigSendType" SG_ 853 CSE03_E_039_FLASH_CRC_PROD 1;
BA_ "GenSigCycleTime" SG_ 853 CSE03_E_038_FLASH_READ_CAN 10;
BA_ "GenSigSendType" SG_ 853 CSE03_E_038_FLASH_READ_CAN 1;
BA_ "GenSigCycleTime" SG_ 853 CSE03_E_037_FLASH_CRC_CAN 10;
BA_ "GenSigSendType" SG_ 853 CSE03_E_037_FLASH_CRC_CAN 1;
BA_ "GenSigCycleTime" SG_ 853 CSE03_E_036 10;
BA_ "GenSigSendType" SG_ 853 CSE03_E_036 1;
BA_ "GenSigCycleTime" SG_ 853 CSE03_E_035 10;
BA_ "GenSigSendType" SG_ 853 CSE03_E_035 1;
BA_ "GenSigCycleTime" SG_ 853 CSE03_E_034_SYS_DATASET 10;
BA_ "GenSigSendType" SG_ 853 CSE03_E_034_SYS_DATASET 1;
BA_ "GenSigCycleTime" SG_ 853 CSE03_E_033_SYS_DATASET_WARN 10;
BA_ "GenSigSendType" SG_ 853 CSE03_E_033_SYS_DATASET_WARN 1;
BA_ "GenSigCycleTime" SG_ 853 CSE03_E_032_SYS_TASK_TIME 10;
BA_ "GenSigSendType" SG_ 853 CSE03_E_032_SYS_TASK_TIME 1;
BA_ "GenSigCycleTime" SG_ 853 CSE03_E_031_SYS_DIFF_ZERO 10;
BA_ "GenSigSendType" SG_ 853 CSE03_E_031_SYS_DIFF_ZERO 1;
BA_ "GenSigCycleTime" SG_ 853 CSE03_E_030_SYS_SWITCH_DEF 10;
BA_ "GenSigSendType" SG_ 853 CSE03_E_030_SYS_SWITCH_DEF 1;
BA_ "GenSigCycleTime" SG_ 853 CSE03_E_029_SYS_GENERAL 10;
BA_ "GenSigSendType" SG_ 853 CSE03_E_029_SYS_GENERAL 1;
BA_ "GenSigCycleTime" SG_ 853 CSE03_E_028 10;
BA_ "GenSigSendType" SG_ 853 CSE03_E_028 1;
BA_ "GenSigCycleTime" SG_ 853 CSE03_E_027_BAL_CONTACT_RES 10;
BA_ "GenSigSendType" SG_ 853 CSE03_E_027_BAL_CONTACT_RES 1;
BA_ "GenSigCycleTime" SG_ 853 CSE03_E_026_BAL_THRESHOLD 10;
BA_ "GenSigSendType" SG_ 853 CSE03_E_026_BAL_THRESHOLD 1;
BA_ "GenSigCycleTime" SG_ 853 CSE03_E_025_BAL_COMPARE_CFRG 10;
BA_ "GenSigSendType" SG_ 853 CSE03_E_025_BAL_COMPARE_CFRG 1;
BA_ "GenSigCycleTime" SG_ 853 CSE03_E_024_BAL_WRITE_CFRG 10;
BA_ "GenSigSendType" SG_ 853 CSE03_E_024_BAL_WRITE_CFRG 1;
BA_ "GenSigCycleTime" SG_ 853 CSE03_E_023_MEAS_REF_TEMP 10;
BA_ "GenSigSendType" SG_ 853 CSE03_E_023_MEAS_REF_TEMP 1;
BA_ "GenSigCycleTime" SG_ 853 CSE03_E_022_MEAS_REF_VOLT 10;
BA_ "GenSigSendType" SG_ 853 CSE03_E_022_MEAS_REF_VOLT 1;
BA_ "GenSigCycleTime" SG_ 853 CSE03_E_021_MEAS_TEMP_TIMEOUT 10;
BA_ "GenSigSendType" SG_ 853 CSE03_E_021_MEAS_TEMP_TIMEOUT 1;
BA_ "GenSigCycleTime" SG_ 853 CSE03_E_020_MEAS_VOLT_TIMEOUT 10;
BA_ "GenSigSendType" SG_ 853 CSE03_E_020_MEAS_VOLT_TIMEOUT 1;
BA_ "GenSigCycleTime" SG_ 853 CSE03_E_019_MEAS_TEMP_SEQ 10;
BA_ "GenSigSendType" SG_ 853 CSE03_E_019_MEAS_TEMP_SEQ 1;
BA_ "GenSigCycleTime" SG_ 853 CSE03_E_018_MEAS_VOLT_SEQ 10;
BA_ "GenSigSendType" SG_ 853 CSE03_E_018_MEAS_VOLT_SEQ 1;
BA_ "GenSigCycleTime" SG_ 853 CSE03_E_017_MEAS_SET_CONFIG 10;
BA_ "GenSigSendType" SG_ 853 CSE03_E_017_MEAS_SET_CONFIG 1;
BA_ "GenSigCycleTime" SG_ 853 CSE03_E_016_MEAS_START_VOLT 10;
BA_ "GenSigSendType" SG_ 853 CSE03_E_016_MEAS_START_VOLT 1;
BA_ "GenSigCycleTime" SG_ 853 CSE03_E_015_MEAS_START_TEMP 10;
BA_ "GenSigSendType" SG_ 853 CSE03_E_015_MEAS_START_TEMP 1;
BA_ "GenSigCycleTime" SG_ 853 CSE03_E_014_MEAS_READ_VOLT 10;
BA_ "GenSigSendType" SG_ 853 CSE03_E_014_MEAS_READ_VOLT 1;
BA_ "GenSigCycleTime" SG_ 853 CSE03_E_013_MEAS_READ_TEMP 10;
BA_ "GenSigSendType" SG_ 853 CSE03_E_013_MEAS_READ_TEMP 1;
BA_ "GenSigCycleTime" SG_ 853 CSE03_E_012_MEAS_INIT 10;
BA_ "GenSigSendType" SG_ 853 CSE03_E_012_MEAS_INIT 1;
BA_ "GenSigCycleTime" SG_ 853 CSE03_E_011 10;
BA_ "GenSigSendType" SG_ 853 CSE03_E_011 1;
BA_ "GenSigCycleTime" SG_ 853 CSE03_E_010 10;
BA_ "GenSigSendType" SG_ 853 CSE03_E_010 1;
BA_ "GenSigCycleTime" SG_ 853 CSE03_E_009 10;
BA_ "GenSigSendType" SG_ 853 CSE03_E_009 1;
BA_ "GenSigCycleTime" SG_ 853 CSE03_E_008_LIM_CONTACT_RES 10;
BA_ "GenSigSendType" SG_ 853 CSE03_E_008_LIM_CONTACT_RES 1;
BA_ "GenSigCycleTime" SG_ 853 CSE03_E_007_LIM_OVERTEMP_PCB 10;
BA_ "GenSigSendType" SG_ 853 CSE03_E_007_LIM_OVERTEMP_PCB 1;
BA_ "GenSigCycleTime" SG_ 853 CSE03_E_006_LIM_UNDERTEMP 10;
BA_ "GenSigSendType" SG_ 853 CSE03_E_006_LIM_UNDERTEMP 1;
BA_ "GenSigCycleTime" SG_ 853 CSE03_E_005_LIM_OVERTEMP 10;
BA_ "GenSigSendType" SG_ 853 CSE03_E_005_LIM_OVERTEMP 1;
BA_ "GenSigCycleTime" SG_ 853 CSE03_E_004_LIM_UNDERVOLT 10;
BA_ "GenSigSendType" SG_ 853 CSE03_E_004_LIM_UNDERVOLT 1;
BA_ "GenSigCycleTime" SG_ 853 CSE03_E_003_LIM_OVERVOLT 10;
BA_ "GenSigSendType" SG_ 853 CSE03_E_003_LIM_OVERVOLT 1;
BA_ "GenSigCycleTime" SG_ 853 CSE03_E_002_ARTICLE_NUMBER 10;
BA_ "GenSigSendType" SG_ 853 CSE03_E_002_ARTICLE_NUMBER 1;
BA_ "GenSigCycleTime" SG_ 853 CSE03_E_001_EMERGENCY_LINE 10;
BA_ "GenSigSendType" SG_ 853 CSE03_E_001_EMERGENCY_LINE 1;
BA_ "GenSigCycleTime" SG_ 853 CSE03_E_FLAG 10;
BA_ "GenSigSendType" SG_ 853 CSE03_E_FLAG 1;
BA_ "GenSigCycleTime" SG_ 769 CSM_E_EEPROM_READ_WRITE 10;
BA_ "GenSigSendType" SG_ 769 CSM_E_EEPROM_READ_WRITE 1;
BA_ "GenSigCycleTime" SG_ 769 CSM_E_MSW_AGE_ERR 10;
BA_ "GenSigSendType" SG_ 769 CSM_E_MSW_AGE_ERR 1;
BA_ "GenSigCycleTime" SG_ 769 CSM_E_MSW_AGE_WARN 10;
BA_ "GenSigSendType" SG_ 769 CSM_E_MSW_AGE_WARN 1;
BA_ "GenSigCycleTime" SG_ 769 CSM_E_BROKEN_WIRE 10;
BA_ "GenSigSendType" SG_ 769 CSM_E_BROKEN_WIRE 1;
BA_ "GenSigCycleTime" SG_ 769 CSM_E_U_REF 10;
BA_ "GenSigSendType" SG_ 769 CSM_E_U_REF 1;
BA_ "GenSigCycleTime" SG_ 769 CSM_E_CPU_MONITOR 10;
BA_ "GenSigSendType" SG_ 769 CSM_E_CPU_MONITOR 1;
BA_ "GenSigCycleTime" SG_ 769 CSM_E_ROM_MONITOR 10;
BA_ "GenSigSendType" SG_ 769 CSM_E_ROM_MONITOR 1;
BA_ "GenSigCycleTime" SG_ 769 CSM_E_RAM_MONITOR 10;
BA_ "GenSigSendType" SG_ 769 CSM_E_RAM_MONITOR 1;
BA_ "GenSigCycleTime" SG_ 769 CSM_E_STACK_MONITOR 10;
BA_ "GenSigSendType" SG_ 769 CSM_E_STACK_MONITOR 1;
BA_ "GenSigCycleTime" SG_ 769 CSM_E_RESET_MONITOR 10;
BA_ "GenSigSendType" SG_ 769 CSM_E_RESET_MONITOR 1;
BA_ "GenSigCycleTime" SG_ 769 CSM_E_INTERRUPT_MONITOR 10;
BA_ "GenSigSendType" SG_ 769 CSM_E_INTERRUPT_MONITOR 1;
BA_ "GenSigCycleTime" SG_ 769 CSM_E_UBAT_COMPARE_IHM_UC 10;
BA_ "GenSigSendType" SG_ 769 CSM_E_UBAT_COMPARE_IHM_UC 1;
BA_ "GenSigCycleTime" SG_ 769 CSM_E_SEND_CAN 10;
BA_ "GenSigSendType" SG_ 769 CSM_E_SEND_CAN 1;
BA_ "GenSigCycleTime" SG_ 769 CSM_E_CAN_ERROR_ID 10;
BA_ "GenSigSendType" SG_ 769 CSM_E_CAN_ERROR_ID 1;
BA_ "GenSigCycleTime" SG_ 769 CSM_E_TASK_TIME 10;
BA_ "GenSigSendType" SG_ 769 CSM_E_TASK_TIME 1;
BA_ "GenSigCycleTime" SG_ 769 CSM_E_I_OCD_DISCHARGE_OOR 10;
BA_ "GenSigSendType" SG_ 769 CSM_E_I_OCD_DISCHARGE_OOR 1;
BA_ "GenSigCycleTime" SG_ 769 CSM_E_I_OCD_CHARGE_OOR 10;
BA_ "GenSigSendType" SG_ 769 CSM_E_I_OCD_CHARGE_OOR 1;
BA_ "GenSigCycleTime" SG_ 769 CSM_E_TEMPERATURE_MIN 10;
BA_ "GenSigSendType" SG_ 769 CSM_E_TEMPERATURE_MIN 1;
BA_ "GenSigCycleTime" SG_ 769 CSM_E_TEMPERATURE_MAX 10;
BA_ "GenSigSendType" SG_ 769 CSM_E_TEMPERATURE_MAX 1;
BA_ "GenSigCycleTime" SG_ 769 CSM_E_VOLTAGE_TRAC_N_MIN 10;
BA_ "GenSigSendType" SG_ 769 CSM_E_VOLTAGE_TRAC_N_MIN 1;
BA_ "GenSigCycleTime" SG_ 769 CSM_E_VOLTAGE_TRAC_N_MAX 10;
BA_ "GenSigSendType" SG_ 769 CSM_E_VOLTAGE_TRAC_N_MAX 1;
BA_ "GenSigCycleTime" SG_ 769 CSM_E_VOLTAGE_TRAC_P_MIN 10;
BA_ "GenSigSendType" SG_ 769 CSM_E_VOLTAGE_TRAC_P_MIN 1;
BA_ "GenSigCycleTime" SG_ 769 CSM_E_VOLTAGE_TRAC_P_MAX 10;
BA_ "GenSigSendType" SG_ 769 CSM_E_VOLTAGE_TRAC_P_MAX 1;
BA_ "GenSigCycleTime" SG_ 769 CSM_E_VOLTAGE_BAT_MIN 10;
BA_ "GenSigSendType" SG_ 769 CSM_E_VOLTAGE_BAT_MIN 1;
BA_ "GenSigCycleTime" SG_ 769 CSM_E_VOLTAGE_BAT_MAX 10;
BA_ "GenSigSendType" SG_ 769 CSM_E_VOLTAGE_BAT_MAX 1;
BA_ "GenSigCycleTime" SG_ 769 CSM_E_CURRENT_DISCHARGE_MAX 10;
BA_ "GenSigSendType" SG_ 769 CSM_E_CURRENT_DISCHARGE_MAX 1;
BA_ "GenSigCycleTime" SG_ 769 CSM_E_CURRENT_CHARGE_MAX 10;
BA_ "GenSigSendType" SG_ 769 CSM_E_CURRENT_CHARGE_MAX 1;
BA_ "GenSigCycleTime" SG_ 769 CSM_E_MEAS_TEMPINT_OUFLOW 10;
BA_ "GenSigSendType" SG_ 769 CSM_E_MEAS_TEMPINT_OUFLOW 1;
BA_ "GenSigCycleTime" SG_ 769 CSM_E_MEAS_U_TRAC_N_OUFLOW 10;
BA_ "GenSigSendType" SG_ 769 CSM_E_MEAS_U_TRAC_N_OUFLOW 1;
BA_ "GenSigCycleTime" SG_ 769 CSM_E_MEAS_U_TRAC_P_OUFLOW 10;
BA_ "GenSigSendType" SG_ 769 CSM_E_MEAS_U_TRAC_P_OUFLOW 1;
BA_ "GenSigCycleTime" SG_ 769 CSM_E_MEAS_U_BAT_OUFLOW 10;
BA_ "GenSigSendType" SG_ 769 CSM_E_MEAS_U_BAT_OUFLOW 1;
BA_ "GenSigCycleTime" SG_ 769 CSM_E_MEAS_CURRENT_OUFLOW 10;
BA_ "GenSigSendType" SG_ 769 CSM_E_MEAS_CURRENT_OUFLOW 1;
BA_ "GenSigCycleTime" SG_ 769 CSM_E_FLASH_CRC_DATARECORD_B 10;
BA_ "GenSigSendType" SG_ 769 CSM_E_FLASH_CRC_DATARECORD_B 1;
BA_ "GenSigCycleTime" SG_ 769 CSM_E_FLASH_CRC_DATARECORD_A 10;
BA_ "GenSigSendType" SG_ 769 CSM_E_FLASH_CRC_DATARECORD_A 1;
BA_ "GenSigCycleTime" SG_ 769 CSM_E_FLASH_WRITE_CALIB_PARA 10;
BA_ "GenSigSendType" SG_ 769 CSM_E_FLASH_WRITE_CALIB_PARA 1;
BA_ "GenSigCycleTime" SG_ 769 CSM_E_FLASH_READ_CALIB_PARA 10;
BA_ "GenSigSendType" SG_ 769 CSM_E_FLASH_READ_CALIB_PARA 1;
BA_ "GenSigCycleTime" SG_ 769 CSM_E_FLASH_CRC_CALIB_PARA 10;
BA_ "GenSigSendType" SG_ 769 CSM_E_FLASH_CRC_CALIB_PARA 1;
BA_ "GenSigCycleTime" SG_ 769 CSM_E_FLASH_WRITE_IHM_PARA 10;
BA_ "GenSigSendType" SG_ 769 CSM_E_FLASH_WRITE_IHM_PARA 1;
BA_ "GenSigCycleTime" SG_ 769 CSM_E_FLASH_READ_IHM_PARA 10;
BA_ "GenSigSendType" SG_ 769 CSM_E_FLASH_READ_IHM_PARA 1;
BA_ "GenSigCycleTime" SG_ 769 CSM_E_FLASH_CRC_IHM_PARA 10;
BA_ "GenSigSendType" SG_ 769 CSM_E_FLASH_CRC_IHM_PARA 1;
BA_ "GenSigCycleTime" SG_ 769 CSM_E_FLASH_WRITE_PROD_DATA 10;
BA_ "GenSigSendType" SG_ 769 CSM_E_FLASH_WRITE_PROD_DATA 1;
BA_ "GenSigCycleTime" SG_ 769 CSM_E_FLASH_READ_PROD_DATA 10;
BA_ "GenSigSendType" SG_ 769 CSM_E_FLASH_READ_PROD_DATA 1;
BA_ "GenSigCycleTime" SG_ 769 CSM_E_FLASH_CRC_PROD_DATA 10;
BA_ "GenSigSendType" SG_ 769 CSM_E_FLASH_CRC_PROD_DATA 1;
BA_ "GenSigCycleTime" SG_ 769 CSM_E_FLASH_WRITE_CAN_PARA 10;
BA_ "GenSigSendType" SG_ 769 CSM_E_FLASH_WRITE_CAN_PARA 1;
BA_ "GenSigCycleTime" SG_ 769 CSM_E_FLASH_READ_CAN_PARA 10;
BA_ "GenSigSendType" SG_ 769 CSM_E_FLASH_READ_CAN_PARA 1;
BA_ "GenSigCycleTime" SG_ 769 CSM_E_FLASH_CRC_CAN_PARA 10;
BA_ "GenSigSendType" SG_ 769 CSM_E_FLASH_CRC_CAN_PARA 1;
BA_ "GenSigCycleTime" SG_ 769 CSM_E_IHM_INIT_CRA 10;
BA_ "GenSigSendType" SG_ 769 CSM_E_IHM_INIT_CRA 1;
BA_ "GenSigCycleTime" SG_ 769 CSM_E_IHM_INIT_CRG 10;
BA_ "GenSigSendType" SG_ 769 CSM_E_IHM_INIT_CRG 1;
BA_ "GenSigCycleTime" SG_ 769 CSM_E_IHM_INIT_TRR 10;
BA_ "GenSigSendType" SG_ 769 CSM_E_IHM_INIT_TRR 1;
BA_ "GenSigCycleTime" SG_ 769 CSM_E_IHM_INIT_CAR 10;
BA_ "GenSigSendType" SG_ 769 CSM_E_IHM_INIT_CAR 1;
BA_ "GenSigCycleTime" SG_ 769 CSM_E_IHM_INIT_OPM 10;
BA_ "GenSigSendType" SG_ 769 CSM_E_IHM_INIT_OPM 1;
BA_ "GenSigCycleTime" SG_ 769 CSM_E_OCD 10;
BA_ "GenSigSendType" SG_ 769 CSM_E_OCD 1;
BA_ "GenSigCycleTime" SG_ 769 CSM_E_IHM_ZZR_CHECK 10;
BA_ "GenSigSendType" SG_ 769 CSM_E_IHM_ZZR_CHECK 1;
BA_ "GenSigCycleTime" SG_ 769 CSM_E_IHM_TRR_CHECK 10;
BA_ "GenSigSendType" SG_ 769 CSM_E_IHM_TRR_CHECK 1;
BA_ "GenSigCycleTime" SG_ 769 CSM_E_IHM_CAR_CHECK 10;
BA_ "GenSigSendType" SG_ 769 CSM_E_IHM_CAR_CHECK 1;
BA_ "GenSigCycleTime" SG_ 769 CSM_E_SYS_GENERAL 10;
BA_ "GenSigSendType" SG_ 769 CSM_E_SYS_GENERAL 1;
BA_ "GenSigCycleTime" SG_ 769 CSM_E_WRONG_DATARECORD 10;
BA_ "GenSigSendType" SG_ 769 CSM_E_WRONG_DATARECORD 1;
BA_ "GenSigCycleTime" SG_ 769 CSM_E_WRONG_ARTICLE_NUMBER 10;
BA_ "GenSigSendType" SG_ 769 CSM_E_WRONG_ARTICLE_NUMBER 1;
BA_ "GenSigCycleTime" SG_ 769 CSM_E_063 10;
BA_ "GenSigSendType" SG_ 769 CSM_E_063 1;
BA_ "GenSigCycleTime" SG_ 769 CSM_E_062 10;
BA_ "GenSigSendType" SG_ 769 CSM_E_062 1;
BA_ "GenSigCycleTime" SG_ 769 CSM_E_061 10;
BA_ "GenSigSendType" SG_ 769 CSM_E_061 1;
BA_ "GenSigCycleTime" SG_ 769 CSM_E_060 10;
BA_ "GenSigSendType" SG_ 769 CSM_E_060 1;
BA_ "GenSigCycleTime" SG_ 769 CSM_E_059 10;
BA_ "GenSigSendType" SG_ 769 CSM_E_059 1;
BA_ "GenSigCycleTime" SG_ 769 CSM_E_FLAG 10;
BA_ "GenSigSendType" SG_ 769 CSM_E_FLAG 1;
BA_ "GenSigCycleTime" SG_ 851 CSE02_E_063 10;
BA_ "GenSigSendType" SG_ 851 CSE02_E_063 1;
BA_ "GenSigCycleTime" SG_ 851 CSE02_E_062 10;
BA_ "GenSigSendType" SG_ 851 CSE02_E_062 1;
BA_ "GenSigCycleTime" SG_ 851 CSE02_E_061 10;
BA_ "GenSigSendType" SG_ 851 CSE02_E_061 1;
BA_ "GenSigCycleTime" SG_ 851 CSE02_E_060 10;
BA_ "GenSigSendType" SG_ 851 CSE02_E_060 1;
BA_ "GenSigCycleTime" SG_ 851 CSE02_E_059 10;
BA_ "GenSigSendType" SG_ 851 CSE02_E_059 1;
BA_ "GenSigCycleTime" SG_ 851 CSE02_E_058 10;
BA_ "GenSigSendType" SG_ 851 CSE02_E_058 1;
BA_ "GenSigCycleTime" SG_ 851 CSE02_E_057 10;
BA_ "GenSigSendType" SG_ 851 CSE02_E_057 1;
BA_ "GenSigCycleTime" SG_ 851 CSE02_E_056_FST_ROM 10;
BA_ "GenSigSendType" SG_ 851 CSE02_E_056_FST_ROM 1;
BA_ "GenSigCycleTime" SG_ 851 CSE02_E_055_FST_RAM_SECTION_2 10;
BA_ "GenSigSendType" SG_ 851 CSE02_E_055_FST_RAM_SECTION_2 1;
BA_ "GenSigCycleTime" SG_ 851 CSE02_E_054_FST_RAM_SECTION_1 10;
BA_ "GenSigSendType" SG_ 851 CSE02_E_054_FST_RAM_SECTION_1 1;
BA_ "GenSigCycleTime" SG_ 851 CSE02_E_053_FST_RAM_STARTUP 10;
BA_ "GenSigSendType" SG_ 851 CSE02_E_053_FST_RAM_STARTUP 1;
BA_ "GenSigCycleTime" SG_ 851 CSE02_E_052_FST_CPU 10;
BA_ "GenSigSendType" SG_ 851 CSE02_E_052_FST_CPU 1;
BA_ "GenSigCycleTime" SG_ 851 CSE02_E_051_FST_RESET 10;
BA_ "GenSigSendType" SG_ 851 CSE02_E_051_FST_RESET 1;
BA_ "GenSigCycleTime" SG_ 851 CSE02_E_050_FST_INTERRUPT 10;
BA_ "GenSigSendType" SG_ 851 CSE02_E_050_FST_INTERRUPT 1;
BA_ "GenSigCycleTime" SG_ 851 CSE02_E_049_FST_STACK 10;
BA_ "GenSigSendType" SG_ 851 CSE02_E_049_FST_STACK 1;
BA_ "GenSigCycleTime" SG_ 851 CSE02_E_048_FST_LTC6801 10;
BA_ "GenSigSendType" SG_ 851 CSE02_E_048_FST_LTC6801 1;
BA_ "GenSigCycleTime" SG_ 851 CSE02_E_047 10;
BA_ "GenSigSendType" SG_ 851 CSE02_E_047 1;
BA_ "GenSigCycleTime" SG_ 851 CSE02_E_046 10;
BA_ "GenSigSendType" SG_ 851 CSE02_E_046 1;
BA_ "GenSigCycleTime" SG_ 851 CSE02_E_045 10;
BA_ "GenSigSendType" SG_ 851 CSE02_E_045 1;
BA_ "GenSigCycleTime" SG_ 851 CSE02_E_044_CAN_SEND_SEQ 10;
BA_ "GenSigSendType" SG_ 851 CSE02_E_044_CAN_SEND_SEQ 1;
BA_ "GenSigCycleTime" SG_ 851 CSE02_E_043_CAN_BUFFER_FULL 10;
BA_ "GenSigSendType" SG_ 851 CSE02_E_043_CAN_BUFFER_FULL 1;
BA_ "GenSigCycleTime" SG_ 851 CSE02_E_042 10;
BA_ "GenSigSendType" SG_ 851 CSE02_E_042 1;
BA_ "GenSigCycleTime" SG_ 851 CSE02_E_041 10;
BA_ "GenSigSendType" SG_ 851 CSE02_E_041 1;
BA_ "GenSigCycleTime" SG_ 851 CSE02_E_040_FLASH_READ_PROD 10;
BA_ "GenSigSendType" SG_ 851 CSE02_E_040_FLASH_READ_PROD 1;
BA_ "GenSigCycleTime" SG_ 851 CSE02_E_039_FLASH_CRC_PROD 10;
BA_ "GenSigSendType" SG_ 851 CSE02_E_039_FLASH_CRC_PROD 1;
BA_ "GenSigCycleTime" SG_ 851 CSE02_E_038_FLASH_READ_CAN 10;
BA_ "GenSigSendType" SG_ 851 CSE02_E_038_FLASH_READ_CAN 1;
BA_ "GenSigCycleTime" SG_ 851 CSE02_E_037_FLASH_CRC_CAN 10;
BA_ "GenSigSendType" SG_ 851 CSE02_E_037_FLASH_CRC_CAN 1;
BA_ "GenSigCycleTime" SG_ 851 CSE02_E_036 10;
BA_ "GenSigSendType" SG_ 851 CSE02_E_036 1;
BA_ "GenSigCycleTime" SG_ 851 CSE02_E_035 10;
BA_ "GenSigSendType" SG_ 851 CSE02_E_035 1;
BA_ "GenSigCycleTime" SG_ 851 CSE02_E_034_SYS_DATASET 10;
BA_ "GenSigSendType" SG_ 851 CSE02_E_034_SYS_DATASET 1;
BA_ "GenSigCycleTime" SG_ 851 CSE02_E_033_SYS_DATASET_WARN 10;
BA_ "GenSigSendType" SG_ 851 CSE02_E_033_SYS_DATASET_WARN 1;
BA_ "GenSigCycleTime" SG_ 851 CSE02_E_032_SYS_TASK_TIME 10;
BA_ "GenSigSendType" SG_ 851 CSE02_E_032_SYS_TASK_TIME 1;
BA_ "GenSigCycleTime" SG_ 851 CSE02_E_031_SYS_DIFF_ZERO 10;
BA_ "GenSigSendType" SG_ 851 CSE02_E_031_SYS_DIFF_ZERO 1;
BA_ "GenSigCycleTime" SG_ 851 CSE02_E_030_SYS_SWITCH_DEF 10;
BA_ "GenSigSendType" SG_ 851 CSE02_E_030_SYS_SWITCH_DEF 1;
BA_ "GenSigCycleTime" SG_ 851 CSE02_E_029_SYS_GENERAL 10;
BA_ "GenSigSendType" SG_ 851 CSE02_E_029_SYS_GENERAL 1;
BA_ "GenSigCycleTime" SG_ 851 CSE02_E_028 10;
BA_ "GenSigSendType" SG_ 851 CSE02_E_028 1;
BA_ "GenSigCycleTime" SG_ 851 CSE02_E_027_BAL_CONTACT_RES 10;
BA_ "GenSigSendType" SG_ 851 CSE02_E_027_BAL_CONTACT_RES 1;
BA_ "GenSigCycleTime" SG_ 851 CSE02_E_026_BAL_THRESHOLD 10;
BA_ "GenSigSendType" SG_ 851 CSE02_E_026_BAL_THRESHOLD 1;
BA_ "GenSigCycleTime" SG_ 851 CSE02_E_025_BAL_COMPARE_CFRG 10;
BA_ "GenSigSendType" SG_ 851 CSE02_E_025_BAL_COMPARE_CFRG 1;
BA_ "GenSigCycleTime" SG_ 851 CSE02_E_024_BAL_WRITE_CFRG 10;
BA_ "GenSigSendType" SG_ 851 CSE02_E_024_BAL_WRITE_CFRG 1;
BA_ "GenSigCycleTime" SG_ 851 CSE02_E_023_MEAS_REF_TEMP 10;
BA_ "GenSigSendType" SG_ 851 CSE02_E_023_MEAS_REF_TEMP 1;
BA_ "GenSigCycleTime" SG_ 851 CSE02_E_022_MEAS_REF_VOLT 10;
BA_ "GenSigSendType" SG_ 851 CSE02_E_022_MEAS_REF_VOLT 1;
BA_ "GenSigCycleTime" SG_ 851 CSE02_E_021_MEAS_TEMP_TIMEOUT 10;
BA_ "GenSigSendType" SG_ 851 CSE02_E_021_MEAS_TEMP_TIMEOUT 1;
BA_ "GenSigCycleTime" SG_ 851 CSE02_E_020_MEAS_VOLT_TIMEOUT 10;
BA_ "GenSigSendType" SG_ 851 CSE02_E_020_MEAS_VOLT_TIMEOUT 1;
BA_ "GenSigCycleTime" SG_ 851 CSE02_E_019_MEAS_TEMP_SEQ 10;
BA_ "GenSigSendType" SG_ 851 CSE02_E_019_MEAS_TEMP_SEQ 1;
BA_ "GenSigCycleTime" SG_ 851 CSE02_E_018_MEAS_VOLT_SEQ 10;
BA_ "GenSigSendType" SG_ 851 CSE02_E_018_MEAS_VOLT_SEQ 1;
BA_ "GenSigCycleTime" SG_ 851 CSE02_E_017_MEAS_SET_CONFIG 10;
BA_ "GenSigSendType" SG_ 851 CSE02_E_017_MEAS_SET_CONFIG 1;
BA_ "GenSigCycleTime" SG_ 851 CSE02_E_016_MEAS_START_VOLT 10;
BA_ "GenSigSendType" SG_ 851 CSE02_E_016_MEAS_START_VOLT 1;
BA_ "GenSigCycleTime" SG_ 851 CSE02_E_015_MEAS_START_TEMP 10;
BA_ "GenSigSendType" SG_ 851 CSE02_E_015_MEAS_START_TEMP 1;
BA_ "GenSigCycleTime" SG_ 851 CSE02_E_014_MEAS_READ_VOLT 10;
BA_ "GenSigSendType" SG_ 851 CSE02_E_014_MEAS_READ_VOLT 1;
BA_ "GenSigCycleTime" SG_ 851 CSE02_E_013_MEAS_READ_TEMP 10;
BA_ "GenSigSendType" SG_ 851 CSE02_E_013_MEAS_READ_TEMP 1;
BA_ "GenSigCycleTime" SG_ 851 CSE02_E_012_MEAS_INIT 10;
BA_ "GenSigSendType" SG_ 851 CSE02_E_012_MEAS_INIT 1;
BA_ "GenSigCycleTime" SG_ 851 CSE02_E_011 10;
BA_ "GenSigSendType" SG_ 851 CSE02_E_011 1;
BA_ "GenSigCycleTime" SG_ 851 CSE02_E_010 10;
BA_ "GenSigSendType" SG_ 851 CSE02_E_010 1;
BA_ "GenSigCycleTime" SG_ 851 CSE02_E_009 10;
BA_ "GenSigSendType" SG_ 851 CSE02_E_009 1;
BA_ "GenSigCycleTime" SG_ 851 CSE02_E_008_LIM_CONTACT_RES 10;
BA_ "GenSigSendType" SG_ 851 CSE02_E_008_LIM_CONTACT_RES 1;
BA_ "GenSigCycleTime" SG_ 851 CSE02_E_007_LIM_OVERTEMP_PCB 10;
BA_ "GenSigSendType" SG_ 851 CSE02_E_007_LIM_OVERTEMP_PCB 1;
BA_ "GenSigCycleTime" SG_ 851 CSE02_E_006_LIM_UNDERTEMP 10;
BA_ "GenSigSendType" SG_ 851 CSE02_E_006_LIM_UNDERTEMP 1;
BA_ "GenSigCycleTime" SG_ 851 CSE02_E_005_LIM_OVERTEMP 10;
BA_ "GenSigSendType" SG_ 851 CSE02_E_005_LIM_OVERTEMP 1;
BA_ "GenSigCycleTime" SG_ 851 CSE02_E_004_LIM_UNDERVOLT 10;
BA_ "GenSigSendType" SG_ 851 CSE02_E_004_LIM_UNDERVOLT 1;
BA_ "GenSigCycleTime" SG_ 851 CSE02_E_003_LIM_OVERVOLT 10;
BA_ "GenSigSendType" SG_ 851 CSE02_E_003_LIM_OVERVOLT 1;
BA_ "GenSigCycleTime" SG_ 851 CSE02_E_002_ARTICLE_NUMBER 10;
BA_ "GenSigSendType" SG_ 851 CSE02_E_002_ARTICLE_NUMBER 1;
BA_ "GenSigCycleTime" SG_ 851 CSE02_E_001_EMERGENCY_LINE 10;
BA_ "GenSigSendType" SG_ 851 CSE02_E_001_EMERGENCY_LINE 1;
BA_ "GenSigCycleTime" SG_ 851 CSE02_E_FLAG 10;
BA_ "GenSigSendType" SG_ 851 CSE02_E_FLAG 1;
BA_ "GenSigCycleTime" SG_ 849 CSE01_E_063 10;
BA_ "GenSigSendType" SG_ 849 CSE01_E_063 1;
BA_ "GenSigCycleTime" SG_ 849 CSE01_E_062 10;
BA_ "GenSigSendType" SG_ 849 CSE01_E_062 1;
BA_ "GenSigCycleTime" SG_ 849 CSE01_E_061 10;
BA_ "GenSigSendType" SG_ 849 CSE01_E_061 1;
BA_ "GenSigCycleTime" SG_ 849 CSE01_E_060 10;
BA_ "GenSigSendType" SG_ 849 CSE01_E_060 1;
BA_ "GenSigCycleTime" SG_ 849 CSE01_E_059 10;
BA_ "GenSigSendType" SG_ 849 CSE01_E_059 1;
BA_ "GenSigCycleTime" SG_ 849 CSE01_E_058 10;
BA_ "GenSigSendType" SG_ 849 CSE01_E_058 1;
BA_ "GenSigCycleTime" SG_ 849 CSE01_E_057 10;
BA_ "GenSigSendType" SG_ 849 CSE01_E_057 1;
BA_ "GenSigCycleTime" SG_ 849 CSE01_E_056_FST_ROM 10;
BA_ "GenSigSendType" SG_ 849 CSE01_E_056_FST_ROM 1;
BA_ "GenSigCycleTime" SG_ 849 CSE01_E_055_FST_RAM_SECTION_2 10;
BA_ "GenSigSendType" SG_ 849 CSE01_E_055_FST_RAM_SECTION_2 1;
BA_ "GenSigCycleTime" SG_ 849 CSE01_E_054_FST_RAM_SECTION_1 10;
BA_ "GenSigSendType" SG_ 849 CSE01_E_054_FST_RAM_SECTION_1 1;
BA_ "GenSigCycleTime" SG_ 849 CSE01_E_053_FST_RAM_STARTUP 10;
BA_ "GenSigSendType" SG_ 849 CSE01_E_053_FST_RAM_STARTUP 1;
BA_ "GenSigCycleTime" SG_ 849 CSE01_E_052_FST_CPU 10;
BA_ "GenSigSendType" SG_ 849 CSE01_E_052_FST_CPU 1;
BA_ "GenSigCycleTime" SG_ 849 CSE01_E_051_FST_RESET 10;
BA_ "GenSigSendType" SG_ 849 CSE01_E_051_FST_RESET 1;
BA_ "GenSigCycleTime" SG_ 849 CSE01_E_050_FST_INTERRUPT 10;
BA_ "GenSigSendType" SG_ 849 CSE01_E_050_FST_INTERRUPT 1;
BA_ "GenSigCycleTime" SG_ 849 CSE01_E_049_FST_STACK 10;
BA_ "GenSigSendType" SG_ 849 CSE01_E_049_FST_STACK 1;
BA_ "GenSigCycleTime" SG_ 849 CSE01_E_048_FST_LTC6801 10;
BA_ "GenSigSendType" SG_ 849 CSE01_E_048_FST_LTC6801 1;
BA_ "GenSigCycleTime" SG_ 849 CSE01_E_047 10;
BA_ "GenSigSendType" SG_ 849 CSE01_E_047 1;
BA_ "GenSigCycleTime" SG_ 849 CSE01_E_046 10;
BA_ "GenSigSendType" SG_ 849 CSE01_E_046 1;
BA_ "GenSigCycleTime" SG_ 849 CSE01_E_045 10;
BA_ "GenSigSendType" SG_ 849 CSE01_E_045 1;
BA_ "GenSigCycleTime" SG_ 849 CSE01_E_044_CAN_SEND_SEQ 10;
BA_ "GenSigSendType" SG_ 849 CSE01_E_044_CAN_SEND_SEQ 1;
BA_ "GenSigCycleTime" SG_ 849 CSE01_E_043_CAN_BUFFER_FULL 10;
BA_ "GenSigSendType" SG_ 849 CSE01_E_043_CAN_BUFFER_FULL 1;
BA_ "GenSigCycleTime" SG_ 849 CSE01_E_042 10;
BA_ "GenSigSendType" SG_ 849 CSE01_E_042 1;
BA_ "GenSigCycleTime" SG_ 849 CSE01_E_041 10;
BA_ "GenSigSendType" SG_ 849 CSE01_E_041 1;
BA_ "GenSigCycleTime" SG_ 849 CSE01_E_040_FLASH_READ_PROD 10;
BA_ "GenSigSendType" SG_ 849 CSE01_E_040_FLASH_READ_PROD 1;
BA_ "GenSigCycleTime" SG_ 849 CSE01_E_039_FLASH_CRC_PROD 10;
BA_ "GenSigSendType" SG_ 849 CSE01_E_039_FLASH_CRC_PROD 1;
BA_ "GenSigCycleTime" SG_ 849 CSE01_E_038_FLASH_READ_CAN 10;
BA_ "GenSigSendType" SG_ 849 CSE01_E_038_FLASH_READ_CAN 1;
BA_ "GenSigCycleTime" SG_ 849 CSE01_E_037_FLASH_CRC_CAN 10;
BA_ "GenSigSendType" SG_ 849 CSE01_E_037_FLASH_CRC_CAN 1;
BA_ "GenSigCycleTime" SG_ 849 CSE01_E_036 10;
BA_ "GenSigSendType" SG_ 849 CSE01_E_036 1;
BA_ "GenSigCycleTime" SG_ 849 CSE01_E_035 10;
BA_ "GenSigSendType" SG_ 849 CSE01_E_035 1;
BA_ "GenSigCycleTime" SG_ 849 CSE01_E_034_SYS_DATASET 10;
BA_ "GenSigSendType" SG_ 849 CSE01_E_034_SYS_DATASET 1;
BA_ "GenSigCycleTime" SG_ 849 CSE01_E_033_SYS_DATASET_WARN 10;
BA_ "GenSigSendType" SG_ 849 CSE01_E_033_SYS_DATASET_WARN 1;
BA_ "GenSigCycleTime" SG_ 849 CSE01_E_032_SYS_TASK_TIME 10;
BA_ "GenSigSendType" SG_ 849 CSE01_E_032_SYS_TASK_TIME 1;
BA_ "GenSigCycleTime" SG_ 849 CSE01_E_031_SYS_DIFF_ZERO 10;
BA_ "GenSigSendType" SG_ 849 CSE01_E_031_SYS_DIFF_ZERO 1;
BA_ "GenSigCycleTime" SG_ 849 CSE01_E_030_SYS_SWITCH_DEF 10;
BA_ "GenSigSendType" SG_ 849 CSE01_E_030_SYS_SWITCH_DEF 1;
BA_ "GenSigCycleTime" SG_ 849 CSE01_E_029_SYS_GENERAL 10;
BA_ "GenSigSendType" SG_ 849 CSE01_E_029_SYS_GENERAL 1;
BA_ "GenSigCycleTime" SG_ 849 CSE01_E_028 10;
BA_ "GenSigSendType" SG_ 849 CSE01_E_028 1;
BA_ "GenSigCycleTime" SG_ 849 CSE01_E_027_BAL_CONTACT_RES 10;
BA_ "GenSigSendType" SG_ 849 CSE01_E_027_BAL_CONTACT_RES 1;
BA_ "GenSigCycleTime" SG_ 849 CSE01_E_026_BAL_THRESHOLD 10;
BA_ "GenSigSendType" SG_ 849 CSE01_E_026_BAL_THRESHOLD 1;
BA_ "GenSigCycleTime" SG_ 849 CSE01_E_025_BAL_COMPARE_CFRG 10;
BA_ "GenSigSendType" SG_ 849 CSE01_E_025_BAL_COMPARE_CFRG 1;
BA_ "GenSigCycleTime" SG_ 849 CSE01_E_024_BAL_WRITE_CFRG 10;
BA_ "GenSigSendType" SG_ 849 CSE01_E_024_BAL_WRITE_CFRG 1;
BA_ "GenSigCycleTime" SG_ 849 CSE01_E_023_MEAS_REF_TEMP 10;
BA_ "GenSigSendType" SG_ 849 CSE01_E_023_MEAS_REF_TEMP 1;
BA_ "GenSigCycleTime" SG_ 849 CSE01_E_022_MEAS_REF_VOLT 10;
BA_ "GenSigSendType" SG_ 849 CSE01_E_022_MEAS_REF_VOLT 1;
BA_ "GenSigCycleTime" SG_ 849 CSE01_E_021_MEAS_TEMP_TIMEOUT 10;
BA_ "GenSigSendType" SG_ 849 CSE01_E_021_MEAS_TEMP_TIMEOUT 1;
BA_ "GenSigCycleTime" SG_ 849 CSE01_E_020_MEAS_VOLT_TIMEOUT 10;
BA_ "GenSigSendType" SG_ 849 CSE01_E_020_MEAS_VOLT_TIMEOUT 1;
BA_ "GenSigCycleTime" SG_ 849 CSE01_E_019_MEAS_TEMP_SEQ 10;
BA_ "GenSigSendType" SG_ 849 CSE01_E_019_MEAS_TEMP_SEQ 1;
BA_ "GenSigCycleTime" SG_ 849 CSE01_E_018_MEAS_VOLT_SEQ 10;
BA_ "GenSigSendType" SG_ 849 CSE01_E_018_MEAS_VOLT_SEQ 1;
BA_ "GenSigCycleTime" SG_ 849 CSE01_E_017_MEAS_SET_CONFIG 10;
BA_ "GenSigSendType" SG_ 849 CSE01_E_017_MEAS_SET_CONFIG 1;
BA_ "GenSigCycleTime" SG_ 849 CSE01_E_016_MEAS_START_VOLT 10;
BA_ "GenSigSendType" SG_ 849 CSE01_E_016_MEAS_START_VOLT 1;
BA_ "GenSigCycleTime" SG_ 849 CSE01_E_015_MEAS_START_TEMP 10;
BA_ "GenSigSendType" SG_ 849 CSE01_E_015_MEAS_START_TEMP 1;
BA_ "GenSigCycleTime" SG_ 849 CSE01_E_014_MEAS_READ_VOLT 10;
BA_ "GenSigSendType" SG_ 849 CSE01_E_014_MEAS_READ_VOLT 1;
BA_ "GenSigCycleTime" SG_ 849 CSE01_E_013_MEAS_READ_TEMP 10;
BA_ "GenSigSendType" SG_ 849 CSE01_E_013_MEAS_READ_TEMP 1;
BA_ "GenSigCycleTime" SG_ 849 CSE01_E_012_MEAS_INIT 10;
BA_ "GenSigSendType" SG_ 849 CSE01_E_012_MEAS_INIT 1;
BA_ "GenSigCycleTime" SG_ 849 CSE01_E_011 10;
BA_ "GenSigSendType" SG_ 849 CSE01_E_011 1;
BA_ "GenSigCycleTime" SG_ 849 CSE01_E_010 10;
BA_ "GenSigSendType" SG_ 849 CSE01_E_010 1;
BA_ "GenSigCycleTime" SG_ 849 CSE01_E_009 10;
BA_ "GenSigSendType" SG_ 849 CSE01_E_009 1;
BA_ "GenSigCycleTime" SG_ 849 CSE01_E_FLAG 10;
BA_ "GenSigSendType" SG_ 849 CSE01_E_FLAG 1;
BA_ "GenSigCycleTime" SG_ 849 CSE01_E_008_LIM_CONTACT_RES 10;
BA_ "GenSigSendType" SG_ 849 CSE01_E_008_LIM_CONTACT_RES 1;
BA_ "GenSigCycleTime" SG_ 849 CSE01_E_007_LIM_OVERTEMP_PCB 10;
BA_ "GenSigSendType" SG_ 849 CSE01_E_007_LIM_OVERTEMP_PCB 1;
BA_ "GenSigCycleTime" SG_ 849 CSE01_E_006_LIM_UNDERTEMP 10;
BA_ "GenSigSendType" SG_ 849 CSE01_E_006_LIM_UNDERTEMP 1;
BA_ "GenSigCycleTime" SG_ 849 CSE01_E_005_LIM_OVERTEMP 10;
BA_ "GenSigSendType" SG_ 849 CSE01_E_005_LIM_OVERTEMP 1;
BA_ "GenSigCycleTime" SG_ 849 CSE01_E_004_LIM_UNDERVOLT 10;
BA_ "GenSigSendType" SG_ 849 CSE01_E_004_LIM_UNDERVOLT 1;
BA_ "GenSigCycleTime" SG_ 849 CSE01_E_003_LIM_OVERVOLT 10;
BA_ "GenSigSendType" SG_ 849 CSE01_E_003_LIM_OVERVOLT 1;
BA_ "GenSigCycleTime" SG_ 849 CSE01_E_002_ARTICLE_NUMBER 10;
BA_ "GenSigSendType" SG_ 849 CSE01_E_002_ARTICLE_NUMBER 1;
BA_ "GenSigCycleTime" SG_ 849 CSE01_E_001_EMERGENCY_LINE 10;
BA_ "GenSigSendType" SG_ 849 CSE01_E_001_EMERGENCY_LINE 1;
BA_ "GenSigCycleTime" SG_ 32 BIW_v_States32 10;
BA_ "GenSigSendType" SG_ 32 BIW_v_States32 1;
BA_ "GenSigCycleTime" SG_ 32 BIW_v_EEPROM_Steps 10;
BA_ "GenSigSendType" SG_ 32 BIW_v_EEPROM_Steps 1;
BA_ "GenSigCycleTime" SG_ 32 BIW_v_EEPROM_Status 10;
BA_ "GenSigSendType" SG_ 32 BIW_v_EEPROM_Status 1;
BA_ "GenSigCycleTime" SG_ 32 BIW_v_States 10;
BA_ "GenSigSendType" SG_ 32 BIW_v_States 1;
BA_ "GenSigCycleTime" SG_ 555 SAC_E_Timer_Management 10;
BA_ "GenSigSendType" SG_ 555 SAC_E_Timer_Management 1;
BA_ "GenSigCycleTime" SG_ 555 SAC_E_Task_System 10;
BA_ "GenSigSendType" SG_ 555 SAC_E_Task_System 1;
BA_ "GenSigCycleTime" SG_ 555 SAC_E_Startup_Test 10;
BA_ "GenSigSendType" SG_ 555 SAC_E_Startup_Test 1;
BA_ "GenSigCycleTime" SG_ 555 SAC_E_SSV_Sys_WD_Test 10;
BA_ "GenSigSendType" SG_ 555 SAC_E_SSV_Sys_WD_Test 1;
BA_ "GenSigCycleTime" SG_ 555 SAC_E_SSV_Startup_Test 10;
BA_ "GenSigSendType" SG_ 555 SAC_E_SSV_Startup_Test 1;
BA_ "GenSigCycleTime" SG_ 555 SAC_E_SSV_Ref_Voltage 10;
BA_ "GenSigSendType" SG_ 555 SAC_E_SSV_Ref_Voltage 1;
BA_ "GenSigCycleTime" SG_ 555 SAC_E_SSV_DS_Interop 10;
BA_ "GenSigSendType" SG_ 555 SAC_E_SSV_DS_Interop 1;
BA_ "GenSigCycleTime" SG_ 555 SAC_E_SSV_Alive_Test 10;
BA_ "GenSigSendType" SG_ 555 SAC_E_SSV_Alive_Test 1;
BA_ "GenSigCycleTime" SG_ 555 SAC_E_SPI_COM 10;
BA_ "GenSigSendType" SG_ 555 SAC_E_SPI_COM 1;
BA_ "GenSigCycleTime" SG_ 555 SAC_E_RTC 10;
BA_ "GenSigSendType" SG_ 555 SAC_E_RTC 1;
BA_ "GenSigCycleTime" SG_ 555 SAC_E_Precharge2_power 10;
BA_ "GenSigSendType" SG_ 555 SAC_E_Precharge2_power 1;
BA_ "GenSigCycleTime" SG_ 555 SAC_E_Precharge2_diag 10;
BA_ "GenSigSendType" SG_ 555 SAC_E_Precharge2_diag 1;
BA_ "GenSigCycleTime" SG_ 555 SAC_E_Precharge1_power 10;
BA_ "GenSigSendType" SG_ 555 SAC_E_Precharge1_power 1;
BA_ "GenSigCycleTime" SG_ 555 SAC_E_Precharge1_diag 10;
BA_ "GenSigSendType" SG_ 555 SAC_E_Precharge1_diag 1;
BA_ "GenSigCycleTime" SG_ 555 SAC_E_PMB_OVERCURRENT_PRECH 10;
BA_ "GenSigSendType" SG_ 555 SAC_E_PMB_OVERCURRENT_PRECH 1;
BA_ "GenSigCycleTime" SG_ 555 SAC_E_PMB_Interop 10;
BA_ "GenSigSendType" SG_ 555 SAC_E_PMB_Interop 1;
BA_ "GenSigCycleTime" SG_ 555 SAC_E_PMB_Emergency_Test 10;
BA_ "GenSigSendType" SG_ 555 SAC_E_PMB_Emergency_Test 1;
BA_ "GenSigCycleTime" SG_ 555 SAC_E_PMB_DS_Interop 10;
BA_ "GenSigSendType" SG_ 555 SAC_E_PMB_DS_Interop 1;
BA_ "GenSigCycleTime" SG_ 555 SAC_E_MSW_stuck_Test 10;
BA_ "GenSigSendType" SG_ 555 SAC_E_MSW_stuck_Test 1;
BA_ "GenSigCycleTime" SG_ 555 SAC_E_MSW_plus_stuck 10;
BA_ "GenSigSendType" SG_ 555 SAC_E_MSW_plus_stuck 1;
BA_ "GenSigCycleTime" SG_ 555 SAC_E_MSW_plus_control 10;
BA_ "GenSigSendType" SG_ 555 SAC_E_MSW_plus_control 1;
BA_ "GenSigCycleTime" SG_ 555 SAC_E_MSW_minus_stuck 10;
BA_ "GenSigSendType" SG_ 555 SAC_E_MSW_minus_stuck 1;
BA_ "GenSigCycleTime" SG_ 555 SAC_E_MSW_minus_control 10;
BA_ "GenSigSendType" SG_ 555 SAC_E_MSW_minus_control 1;
BA_ "GenSigCycleTime" SG_ 555 SAC_E_MSW_3_stuck 10;
BA_ "GenSigSendType" SG_ 555 SAC_E_MSW_3_stuck 1;
BA_ "GenSigCycleTime" SG_ 555 SAC_E_MSW_3_control 10;
BA_ "GenSigSendType" SG_ 555 SAC_E_MSW_3_control 1;
BA_ "GenSigCycleTime" SG_ 555 SAC_E_MC_WD 10;
BA_ "GenSigSendType" SG_ 555 SAC_E_MC_WD 1;
BA_ "GenSigCycleTime" SG_ 555 SAC_E_KL30c_Test 10;
BA_ "GenSigSendType" SG_ 555 SAC_E_KL30c_Test 1;
BA_ "GenSigCycleTime" SG_ 555 SAC_E_ISO_SHORT 10;
BA_ "GenSigSendType" SG_ 555 SAC_E_ISO_SHORT 1;
BA_ "GenSigCycleTime" SG_ 555 SAC_E_Internal 10;
BA_ "GenSigSendType" SG_ 555 SAC_E_Internal 1;
BA_ "GenSigCycleTime" SG_ 555 SAC_E_Interlock_Test 10;
BA_ "GenSigSendType" SG_ 555 SAC_E_Interlock_Test 1;
BA_ "GenSigCycleTime" SG_ 555 SAC_E_Dataset_Conf 10;
BA_ "GenSigSendType" SG_ 555 SAC_E_Dataset_Conf 1;
BA_ "GenSigCycleTime" SG_ 555 SAC_E_Dataset 10;
BA_ "GenSigSendType" SG_ 555 SAC_E_Dataset 1;
BA_ "GenSigCycleTime" SG_ 555 SAC_E_CSC_Limits 10;
BA_ "GenSigSendType" SG_ 555 SAC_E_CSC_Limits 1;
BA_ "GenSigCycleTime" SG_ 555 SAC_E_CSC_Interop 10;
BA_ "GenSigSendType" SG_ 555 SAC_E_CSC_Interop 1;
BA_ "GenSigCycleTime" SG_ 555 SAC_E_CSC_Emergency_Test 10;
BA_ "GenSigSendType" SG_ 555 SAC_E_CSC_Emergency_Test 1;
BA_ "GenSigCycleTime" SG_ 555 SAC_E_CSC_DS_Interop 10;
BA_ "GenSigSendType" SG_ 555 SAC_E_CSC_DS_Interop 1;
BA_ "GenSigCycleTime" SG_ 555 SAC_E_crash 10;
BA_ "GenSigSendType" SG_ 555 SAC_E_crash 1;
BA_ "GenSigCycleTime" SG_ 555 SAC_E_CELL_UNDERVOLT_WARN 10;
BA_ "GenSigSendType" SG_ 555 SAC_E_CELL_UNDERVOLT_WARN 1;
BA_ "GenSigCycleTime" SG_ 555 SAC_E_CELL_OVERVOLT_WARN 10;
BA_ "GenSigSendType" SG_ 555 SAC_E_CELL_OVERVOLT_WARN 1;
BA_ "GenSigCycleTime" SG_ 555 SAC_E_BSC_Operation_9D23H 10;
BA_ "GenSigSendType" SG_ 555 SAC_E_BSC_Operation_9D23H 1;
BA_ "GenSigCycleTime" SG_ 555 SAC_E_BSC_Operation_10D 10;
BA_ "GenSigSendType" SG_ 555 SAC_E_BSC_Operation_10D 1;
BA_ "GenSigCycleTime" SG_ 555 SAC_E_ADC 10;
BA_ "GenSigSendType" SG_ 555 SAC_E_ADC 1;
BA_ "GenSigCycleTime" SG_ 555 SAC_E_ACC_Emergency_Test 10;
BA_ "GenSigSendType" SG_ 555 SAC_E_ACC_Emergency_Test 1;
VAL_ 1813 SC_CSE3_HW_Release 255 "SNA" ;
VAL_ 1813 SC_CSE3_HW_Minor 255 "SNA" ;
VAL_ 1813 SC_CSE3_HW_Major 255 "SNA" ;
VAL_ 528 SC_ERR_Reserved_11_12 7 "SNA" 6 "STOPPED" 5 "DEBOUNCING_PREVIOUS_FAILED" 4 "DEBOUNCING_PREVIOUS_PASS" 3 "PREFAILED" 2 "PREPASSED" 1 "RUNNING_FAILED" 0 "RUNNING_PASSED" ;
VAL_ 528 SC_ERR_Reserved_11_11 7 "SNA" 6 "STOPPED" 5 "DEBOUNCING_PREVIOUS_FAILED" 4 "DEBOUNCING_PREVIOUS_PASS" 3 "PREFAILED" 2 "PREPASSED" 1 "RUNNING_FAILED" 0 "RUNNING_PASSED" ;
VAL_ 528 SC_ERR_Reserved_11_10 7 "SNA" 6 "STOPPED" 5 "DEBOUNCING_PREVIOUS_FAILED" 4 "DEBOUNCING_PREVIOUS_PASS" 3 "PREFAILED" 2 "PREPASSED" 1 "RUNNING_FAILED" 0 "RUNNING_PASSED" ;
VAL_ 528 SC_ERR_Reserved_11_09 7 "SNA" 6 "STOPPED" 5 "DEBOUNCING_PREVIOUS_FAILED" 4 "DEBOUNCING_PREVIOUS_PASS" 3 "PREFAILED" 2 "PREPASSED" 1 "RUNNING_FAILED" 0 "RUNNING_PASSED" ;
VAL_ 528 SC_ERR_Reserved_11_08 7 "SNA" 6 "STOPPED" 5 "DEBOUNCING_PREVIOUS_FAILED" 4 "DEBOUNCING_PREVIOUS_PASS" 3 "PREFAILED" 2 "PREPASSED" 1 "RUNNING_FAILED" 0 "RUNNING_PASSED" ;
VAL_ 528 SC_ERR_Reserved_11_07 7 "SNA" 6 "STOPPED" 5 "DEBOUNCING_PREVIOUS_FAILED" 4 "DEBOUNCING_PREVIOUS_PASS" 3 "PREFAILED" 2 "PREPASSED" 1 "RUNNING_FAILED" 0 "RUNNING_PASSED" ;
VAL_ 528 SC_ERR_Reserved_11_06 7 "SNA" 6 "STOPPED" 5 "DEBOUNCING_PREVIOUS_FAILED" 4 "DEBOUNCING_PREVIOUS_PASS" 3 "PREFAILED" 2 "PREPASSED" 1 "RUNNING_FAILED" 0 "RUNNING_PASSED" ;
VAL_ 528 SC_ERR_Reserved_11_05 7 "SNA" 6 "STOPPED" 5 "DEBOUNCING_PREVIOUS_FAILED" 4 "DEBOUNCING_PREVIOUS_PASS" 3 "PREFAILED" 2 "PREPASSED" 1 "RUNNING_FAILED" 0 "RUNNING_PASSED" ;
VAL_ 528 SC_ERR_Reserved_11_04 7 "SNA" 6 "STOPPED" 5 "DEBOUNCING_PREVIOUS_FAILED" 4 "DEBOUNCING_PREVIOUS_PASS" 3 "PREFAILED" 2 "PREPASSED" 1 "RUNNING_FAILED" 0 "RUNNING_PASSED" ;
VAL_ 528 SC_ERR_Reserved_11_03 7 "SNA" 6 "STOPPED" 5 "DEBOUNCING_PREVIOUS_FAILED" 4 "DEBOUNCING_PREVIOUS_PASS" 3 "PREFAILED" 2 "PREPASSED" 1 "RUNNING_FAILED" 0 "RUNNING_PASSED" ;
VAL_ 528 SC_ERR_Reserved_11_02 7 "SNA" 6 "STOPPED" 5 "DEBOUNCING_PREVIOUS_FAILED" 4 "DEBOUNCING_PREVIOUS_PASS" 3 "PREFAILED" 2 "PREPASSED" 1 "RUNNING_FAILED" 0 "RUNNING_PASSED" ;
VAL_ 528 SC_ERR_Reserved_11_01 7 "SNA" 6 "STOPPED" 5 "DEBOUNCING_PREVIOUS_FAILED" 4 "DEBOUNCING_PREVIOUS_PASS" 3 "PREFAILED" 2 "PREPASSED" 1 "RUNNING_FAILED" 0 "RUNNING_PASSED" ;
VAL_ 528 SC_ERR_CSE3_PCB_Temp2_RNGL 7 "SNA" 6 "STOPPED" 5 "DEBOUNCING_PREVIOUS_FAILED" 4 "DEBOUNCING_PREVIOUS_PASS" 3 "PREFAILED" 2 "PREPASSED" 1 "RUNNING_FAILED" 0 "RUNNING_PASSED" ;
VAL_ 528 SC_ERR_CSE3_PCB_Temp2_RNGH 7 "SNA" 6 "STOPPED" 5 "DEBOUNCING_PREVIOUS_FAILED" 4 "DEBOUNCING_PREVIOUS_PASS" 3 "PREFAILED" 2 "PREPASSED" 1 "RUNNING_FAILED" 0 "RUNNING_PASSED" ;
VAL_ 528 SC_ERR_CSE3_PCB_Temp2_High 7 "SNA" 6 "STOPPED" 5 "DEBOUNCING_PREVIOUS_FAILED" 4 "DEBOUNCING_PREVIOUS_PASS" 3 "PREFAILED" 2 "PREPASSED" 1 "RUNNING_FAILED" 0 "RUNNING_PASSED" ;
VAL_ 528 SC_ERR_CSE3_PCB_Temp1_RNGL 7 "SNA" 6 "STOPPED" 5 "DEBOUNCING_PREVIOUS_FAILED" 4 "DEBOUNCING_PREVIOUS_PASS" 3 "PREFAILED" 2 "PREPASSED" 1 "RUNNING_FAILED" 0 "RUNNING_PASSED" ;
VAL_ 528 SC_ERR_CSE3_PCB_Temp1_RNGH 7 "SNA" 6 "STOPPED" 5 "DEBOUNCING_PREVIOUS_FAILED" 4 "DEBOUNCING_PREVIOUS_PASS" 3 "PREFAILED" 2 "PREPASSED" 1 "RUNNING_FAILED" 0 "RUNNING_PASSED" ;
VAL_ 528 SC_ERR_CSE3_PCB_Temp1_High 7 "SNA" 6 "STOPPED" 5 "DEBOUNCING_PREVIOUS_FAILED" 4 "DEBOUNCING_PREVIOUS_PASS" 3 "PREFAILED" 2 "PREPASSED" 1 "RUNNING_FAILED" 0 "RUNNING_PASSED" ;
VAL_ 528 SC_ERR_CSE3_Fault_Line 7 "SNA" 6 "STOPPED" 5 "DEBOUNCING_PREVIOUS_FAILED" 4 "DEBOUNCING_PREVIOUS_PASS" 3 "PREFAILED" 2 "PREPASSED" 1 "RUNNING_FAILED" 0 "RUNNING_PASSED" ;
VAL_ 528 SC_ERR_CSE3_Daisy_Chain 7 "SNA" 6 "STOPPED" 5 "DEBOUNCING_PREVIOUS_FAILED" 4 "DEBOUNCING_PREVIOUS_PASS" 3 "PREFAILED" 2 "PREPASSED" 1 "RUNNING_FAILED" 0 "RUNNING_PASSED" ;
VAL_ 528 SC_ERR_CSE3_Com_TOut 7 "SNA" 6 "STOPPED" 5 "DEBOUNCING_PREVIOUS_FAILED" 4 "DEBOUNCING_PREVIOUS_PASS" 3 "PREFAILED" 2 "PREPASSED" 1 "RUNNING_FAILED" 0 "RUNNING_PASSED" ;
VAL_ 1812 SC_CSE2_HW_Release 255 "SNA" ;
VAL_ 1812 SC_CSE2_HW_Minor 255 "SNA" ;
VAL_ 1812 SC_CSE2_HW_Major 255 "SNA" ;
VAL_ 1812 SC_CSE1_HW_Release 255 "SNA" ;
VAL_ 1812 SC_CSE1_HW_Minor 255 "SNA" ;
VAL_ 1812 SC_CSE1_HW_Major 255 "SNA" ;
VAL_ 1811 SC_IMOC_SW_Release 255 "SNA" ;
VAL_ 1811 SC_IMOC_SW_Minor 255 "SNA" ;
VAL_ 1811 SC_IMOC_SW_Major 255 "SNA" ;
VAL_ 1811 SC_IMOC_HW_Release 255 "SNA" ;
VAL_ 1811 SC_IMOC_HW_Minor 255 "SNA" ;
VAL_ 1811 SC_IMOC_HW_Major 255 "SNA" ;
VAL_ 1811 SC_IMOC_DS_CRC 65535 "SNA" ;
VAL_ 1810 SC_CSM2_SW_Release 255 "SNA" ;
VAL_ 1810 SC_CSM2_SW_Minor 255 "SNA" ;
VAL_ 1810 SC_CSM2_SW_Major 255 "SNA" ;
VAL_ 1810 SC_CSM2_HW_Release 255 "SNA" ;
VAL_ 1810 SC_CSM2_HW_Minor 255 "SNA" ;
VAL_ 1810 SC_CSM2_HW_Major 255 "SNA" ;
VAL_ 1810 SC_CSM2_DS_CRC 65535 "SNA" ;
VAL_ 1809 SC_CSM1_SW_Release 255 "SNA" ;
VAL_ 1809 SC_CSM1_SW_Minor 255 "SNA" ;
VAL_ 1809 SC_CSM1_SW_Major 255 "SNA" ;
VAL_ 1809 SC_CSM1_HW_Release 255 "SNA" ;
VAL_ 1809 SC_CSM1_HW_Minor 255 "SNA" ;
VAL_ 1809 SC_CSM1_HW_Major 255 "SNA" ;
VAL_ 1809 SC_CSM1_DS_CRC 65535 "SNA" ;
VAL_ 1808 SC_SW_Release 255 "SNA" ;
VAL_ 1808 SC_SW_Minor 255 "SNA" ;
VAL_ 1808 SC_SW_Major 255 "SNA" ;
VAL_ 1808 SC_HW_Release 255 "SNA" ;
VAL_ 1808 SC_HW_Minor 255 "SNA" ;
VAL_ 1808 SC_HW_Major 255 "SNA" ;
VAL_ 1808 SC_DS_CRC 65535 "SNA" ;
VAL_ 521 SC_ERR_Reserved_10_07 7 "SNA" 6 "STOPPED" 5 "DEBOUNCING_PREVIOUS_FAILED" 4 "DEBOUNCING_PREVIOUS_PASS" 3 "PREFAILED" 2 "PREPASSED" 1 "RUNNING_FAILED" 0 "RUNNING_PASSED" ;
VAL_ 521 SC_ERR_Reserved_10_06 7 "SNA" 6 "STOPPED" 5 "DEBOUNCING_PREVIOUS_FAILED" 4 "DEBOUNCING_PREVIOUS_PASS" 3 "PREFAILED" 2 "PREPASSED" 1 "RUNNING_FAILED" 0 "RUNNING_PASSED" ;
VAL_ 521 SC_ERR_Reserved_10_05 7 "SNA" 6 "STOPPED" 5 "DEBOUNCING_PREVIOUS_FAILED" 4 "DEBOUNCING_PREVIOUS_PASS" 3 "PREFAILED" 2 "PREPASSED" 1 "RUNNING_FAILED" 0 "RUNNING_PASSED" ;
VAL_ 521 SC_ERR_Reserved_10_04 7 "SNA" 6 "STOPPED" 5 "DEBOUNCING_PREVIOUS_FAILED" 4 "DEBOUNCING_PREVIOUS_PASS" 3 "PREFAILED" 2 "PREPASSED" 1 "RUNNING_FAILED" 0 "RUNNING_PASSED" ;
VAL_ 521 SC_ERR_Reserved_10_03 7 "SNA" 6 "STOPPED" 5 "DEBOUNCING_PREVIOUS_FAILED" 4 "DEBOUNCING_PREVIOUS_PASS" 3 "PREFAILED" 2 "PREPASSED" 1 "RUNNING_FAILED" 0 "RUNNING_PASSED" ;
VAL_ 521 SC_ERR_Reserved_10_02 7 "SNA" 6 "STOPPED" 5 "DEBOUNCING_PREVIOUS_FAILED" 4 "DEBOUNCING_PREVIOUS_PASS" 3 "PREFAILED" 2 "PREPASSED" 1 "RUNNING_FAILED" 0 "RUNNING_PASSED" ;
VAL_ 521 SC_ERR_Reserved_10_01 7 "SNA" 6 "STOPPED" 5 "DEBOUNCING_PREVIOUS_FAILED" 4 "DEBOUNCING_PREVIOUS_PASS" 3 "PREFAILED" 2 "PREPASSED" 1 "RUNNING_FAILED" 0 "RUNNING_PASSED" ;
VAL_ 521 SC_ERR_FUSI_FSG_01 7 "SNA" 6 "STOPPED" 5 "DEBOUNCING_PREVIOUS_FAILED" 4 "DEBOUNCING_PREVIOUS_PASS" 3 "PREFAILED" 2 "PREPASSED" 1 "RUNNING_FAILED" 0 "RUNNING_PASSED" ;
VAL_ 521 SC_ERR_FUSI_FSG_02 7 "SNA" 6 "STOPPED" 5 "DEBOUNCING_PREVIOUS_FAILED" 4 "DEBOUNCING_PREVIOUS_PASS" 3 "PREFAILED" 2 "PREPASSED" 1 "RUNNING_FAILED" 0 "RUNNING_PASSED" ;
VAL_ 521 SC_ERR_FUSI_FSG_03 7 "SNA" 6 "STOPPED" 5 "DEBOUNCING_PREVIOUS_FAILED" 4 "DEBOUNCING_PREVIOUS_PASS" 3 "PREFAILED" 2 "PREPASSED" 1 "RUNNING_FAILED" 0 "RUNNING_PASSED" ;
VAL_ 521 SC_ERR_FUSI_FSG_04 7 "SNA" 6 "STOPPED" 5 "DEBOUNCING_PREVIOUS_FAILED" 4 "DEBOUNCING_PREVIOUS_PASS" 3 "PREFAILED" 2 "PREPASSED" 1 "RUNNING_FAILED" 0 "RUNNING_PASSED" ;
VAL_ 521 SC_ERR_FUSI_FSG_05 7 "SNA" 6 "STOPPED" 5 "DEBOUNCING_PREVIOUS_FAILED" 4 "DEBOUNCING_PREVIOUS_PASS" 3 "PREFAILED" 2 "PREPASSED" 1 "RUNNING_FAILED" 0 "RUNNING_PASSED" ;
VAL_ 521 SC_ERR_FUSI_FSG_06 7 "SNA" 6 "STOPPED" 5 "DEBOUNCING_PREVIOUS_FAILED" 4 "DEBOUNCING_PREVIOUS_PASS" 3 "PREFAILED" 2 "PREPASSED" 1 "RUNNING_FAILED" 0 "RUNNING_PASSED" ;
VAL_ 521 SC_ERR_FUSI_FSG_07 7 "SNA" 6 "STOPPED" 5 "DEBOUNCING_PREVIOUS_FAILED" 4 "DEBOUNCING_PREVIOUS_PASS" 3 "PREFAILED" 2 "PREPASSED" 1 "RUNNING_FAILED" 0 "RUNNING_PASSED" ;
VAL_ 521 SC_ERR_FUSI_FSG_08 7 "SNA" 6 "STOPPED" 5 "DEBOUNCING_PREVIOUS_FAILED" 4 "DEBOUNCING_PREVIOUS_PASS" 3 "PREFAILED" 2 "PREPASSED" 1 "RUNNING_FAILED" 0 "RUNNING_PASSED" ;
VAL_ 521 SC_ERR_FUSI_FSG_09 7 "SNA" 6 "STOPPED" 5 "DEBOUNCING_PREVIOUS_FAILED" 4 "DEBOUNCING_PREVIOUS_PASS" 3 "PREFAILED" 2 "PREPASSED" 1 "RUNNING_FAILED" 0 "RUNNING_PASSED" ;
VAL_ 521 SC_ERR_SC_ROM 7 "SNA" 6 "STOPPED" 5 "DEBOUNCING_PREVIOUS_FAILED" 4 "DEBOUNCING_PREVIOUS_PASS" 3 "PREFAILED" 2 "PREPASSED" 1 "RUNNING_FAILED" 0 "RUNNING_PASSED" ;
VAL_ 521 SC_ERR_SC_RAM 7 "SNA" 6 "STOPPED" 5 "DEBOUNCING_PREVIOUS_FAILED" 4 "DEBOUNCING_PREVIOUS_PASS" 3 "PREFAILED" 2 "PREPASSED" 1 "RUNNING_FAILED" 0 "RUNNING_PASSED" ;
VAL_ 521 SC_ERR_SC_NVRAM 7 "SNA" 6 "STOPPED" 5 "DEBOUNCING_PREVIOUS_FAILED" 4 "DEBOUNCING_PREVIOUS_PASS" 3 "PREFAILED" 2 "PREPASSED" 1 "RUNNING_FAILED" 0 "RUNNING_PASSED" ;
VAL_ 521 SC_ERR_IMOC_ROM 7 "SNA" 6 "STOPPED" 5 "DEBOUNCING_PREVIOUS_FAILED" 4 "DEBOUNCING_PREVIOUS_PASS" 3 "PREFAILED" 2 "PREPASSED" 1 "RUNNING_FAILED" 0 "RUNNING_PASSED" ;
VAL_ 521 SC_ERR_IMOC_RAM 7 "SNA" 6 "STOPPED" 5 "DEBOUNCING_PREVIOUS_FAILED" 4 "DEBOUNCING_PREVIOUS_PASS" 3 "PREFAILED" 2 "PREPASSED" 1 "RUNNING_FAILED" 0 "RUNNING_PASSED" ;
VAL_ 520 SC_ERR_Reserved_09_14 7 "SNA" 6 "STOPPED" 5 "DEBOUNCING_PREVIOUS_FAILED" 4 "DEBOUNCING_PREVIOUS_PASS" 3 "PREFAILED" 2 "PREPASSED" 1 "RUNNING_FAILED" 0 "RUNNING_PASSED" ;
VAL_ 520 SC_ERR_Reserved_09_13 7 "SNA" 6 "STOPPED" 5 "DEBOUNCING_PREVIOUS_FAILED" 4 "DEBOUNCING_PREVIOUS_PASS" 3 "PREFAILED" 2 "PREPASSED" 1 "RUNNING_FAILED" 0 "RUNNING_PASSED" ;
VAL_ 520 SC_ERR_Reserved_09_12 7 "SNA" 6 "STOPPED" 5 "DEBOUNCING_PREVIOUS_FAILED" 4 "DEBOUNCING_PREVIOUS_PASS" 3 "PREFAILED" 2 "PREPASSED" 1 "RUNNING_FAILED" 0 "RUNNING_PASSED" ;
VAL_ 520 SC_ERR_Reserved_09_11 7 "SNA" 6 "STOPPED" 5 "DEBOUNCING_PREVIOUS_FAILED" 4 "DEBOUNCING_PREVIOUS_PASS" 3 "PREFAILED" 2 "PREPASSED" 1 "RUNNING_FAILED" 0 "RUNNING_PASSED" ;
VAL_ 520 SC_ERR_Reserved_09_10 7 "SNA" 6 "STOPPED" 5 "DEBOUNCING_PREVIOUS_FAILED" 4 "DEBOUNCING_PREVIOUS_PASS" 3 "PREFAILED" 2 "PREPASSED" 1 "RUNNING_FAILED" 0 "RUNNING_PASSED" ;
VAL_ 520 SC_ERR_Reserved_09_09 7 "SNA" 6 "STOPPED" 5 "DEBOUNCING_PREVIOUS_FAILED" 4 "DEBOUNCING_PREVIOUS_PASS" 3 "PREFAILED" 2 "PREPASSED" 1 "RUNNING_FAILED" 0 "RUNNING_PASSED" ;
VAL_ 520 SC_ERR_Reserved_09_08 7 "SNA" 6 "STOPPED" 5 "DEBOUNCING_PREVIOUS_FAILED" 4 "DEBOUNCING_PREVIOUS_PASS" 3 "PREFAILED" 2 "PREPASSED" 1 "RUNNING_FAILED" 0 "RUNNING_PASSED" ;
VAL_ 520 SC_ERR_Reserved_09_07 7 "SNA" 6 "STOPPED" 5 "DEBOUNCING_PREVIOUS_FAILED" 4 "DEBOUNCING_PREVIOUS_PASS" 3 "PREFAILED" 2 "PREPASSED" 1 "RUNNING_FAILED" 0 "RUNNING_PASSED" ;
VAL_ 520 SC_ERR_Reserved_09_06 7 "SNA" 6 "STOPPED" 5 "DEBOUNCING_PREVIOUS_FAILED" 4 "DEBOUNCING_PREVIOUS_PASS" 3 "PREFAILED" 2 "PREPASSED" 1 "RUNNING_FAILED" 0 "RUNNING_PASSED" ;
VAL_ 520 SC_ERR_Reserved_09_05 7 "SNA" 6 "STOPPED" 5 "DEBOUNCING_PREVIOUS_FAILED" 4 "DEBOUNCING_PREVIOUS_PASS" 3 "PREFAILED" 2 "PREPASSED" 1 "RUNNING_FAILED" 0 "RUNNING_PASSED" ;
VAL_ 520 SC_ERR_Reserved_09_04 7 "SNA" 6 "STOPPED" 5 "DEBOUNCING_PREVIOUS_FAILED" 4 "DEBOUNCING_PREVIOUS_PASS" 3 "PREFAILED" 2 "PREPASSED" 1 "RUNNING_FAILED" 0 "RUNNING_PASSED" ;
VAL_ 520 SC_ERR_Reserved_09_03 7 "SNA" 6 "STOPPED" 5 "DEBOUNCING_PREVIOUS_FAILED" 4 "DEBOUNCING_PREVIOUS_PASS" 3 "PREFAILED" 2 "PREPASSED" 1 "RUNNING_FAILED" 0 "RUNNING_PASSED" ;
VAL_ 520 SC_ERR_Reserved_09_02 7 "SNA" 6 "STOPPED" 5 "DEBOUNCING_PREVIOUS_FAILED" 4 "DEBOUNCING_PREVIOUS_PASS" 3 "PREFAILED" 2 "PREPASSED" 1 "RUNNING_FAILED" 0 "RUNNING_PASSED" ;
VAL_ 520 SC_ERR_Reserved_09_01 7 "SNA" 6 "STOPPED" 5 "DEBOUNCING_PREVIOUS_FAILED" 4 "DEBOUNCING_PREVIOUS_PASS" 3 "PREFAILED" 2 "PREPASSED" 1 "RUNNING_FAILED" 0 "RUNNING_PASSED" ;
VAL_ 520 SC_ERR_ISO_Meas_Selftest 7 "SNA" 6 "STOPPED" 5 "DEBOUNCING_PREVIOUS_FAILED" 4 "DEBOUNCING_PREVIOUS_PASS" 3 "PREFAILED" 2 "PREPASSED" 1 "RUNNING_FAILED" 0 "RUNNING_PASSED" ;
VAL_ 520 SC_ERR_ISO_Int_Lvl3 7 "SNA" 6 "STOPPED" 5 "DEBOUNCING_PREVIOUS_FAILED" 4 "DEBOUNCING_PREVIOUS_PASS" 3 "PREFAILED" 2 "PREPASSED" 1 "RUNNING_FAILED" 0 "RUNNING_PASSED" ;
VAL_ 520 SC_ERR_ISO_Int_Lvl2 7 "SNA" 6 "STOPPED" 5 "DEBOUNCING_PREVIOUS_FAILED" 4 "DEBOUNCING_PREVIOUS_PASS" 3 "PREFAILED" 2 "PREPASSED" 1 "RUNNING_FAILED" 0 "RUNNING_PASSED" ;
VAL_ 520 SC_ERR_ISO_Int_Lvl1 7 "SNA" 6 "STOPPED" 5 "DEBOUNCING_PREVIOUS_FAILED" 4 "DEBOUNCING_PREVIOUS_PASS" 3 "PREFAILED" 2 "PREPASSED" 1 "RUNNING_FAILED" 0 "RUNNING_PASSED" ;
VAL_ 520 SC_ERR_ISO_Ext_Lvl3 7 "SNA" 6 "STOPPED" 5 "DEBOUNCING_PREVIOUS_FAILED" 4 "DEBOUNCING_PREVIOUS_PASS" 3 "PREFAILED" 2 "PREPASSED" 1 "RUNNING_FAILED" 0 "RUNNING_PASSED" ;
VAL_ 520 SC_ERR_ISO_Ext_Lvl2 7 "SNA" 6 "STOPPED" 5 "DEBOUNCING_PREVIOUS_FAILED" 4 "DEBOUNCING_PREVIOUS_PASS" 3 "PREFAILED" 2 "PREPASSED" 1 "RUNNING_FAILED" 0 "RUNNING_PASSED" ;
VAL_ 520 SC_ERR_ISO_Ext_Lvl1 7 "SNA" 6 "STOPPED" 5 "DEBOUNCING_PREVIOUS_FAILED" 4 "DEBOUNCING_PREVIOUS_PASS" 3 "PREFAILED" 2 "PREPASSED" 1 "RUNNING_FAILED" 0 "RUNNING_PASSED" ;
VAL_ 519 SC_ERR_Reserved_08_02 7 "SNA" 6 "STOPPED" 5 "DEBOUNCING_PREVIOUS_FAILED" 4 "DEBOUNCING_PREVIOUS_PASS" 3 "PREFAILED" 2 "PREPASSED" 1 "RUNNING_FAILED" 0 "RUNNING_PASSED" ;
VAL_ 519 SC_ERR_Reserved_08_01 7 "SNA" 6 "STOPPED" 5 "DEBOUNCING_PREVIOUS_FAILED" 4 "DEBOUNCING_PREVIOUS_PASS" 3 "PREFAILED" 2 "PREPASSED" 1 "RUNNING_FAILED" 0 "RUNNING_PASSED" ;
VAL_ 519 SC_ERR_CAN_Sc_Meas_Busoff 7 "SNA" 6 "STOPPED" 5 "DEBOUNCING_PREVIOUS_FAILED" 4 "DEBOUNCING_PREVIOUS_PASS" 3 "PREFAILED" 2 "PREPASSED" 1 "RUNNING_FAILED" 0 "RUNNING_PASSED" ;
VAL_ 519 SC_ERR_CAN_Data_Busoff 7 "SNA" 6 "STOPPED" 5 "DEBOUNCING_PREVIOUS_FAILED" 4 "DEBOUNCING_PREVIOUS_PASS" 3 "PREFAILED" 2 "PREPASSED" 1 "RUNNING_FAILED" 0 "RUNNING_PASSED" ;
VAL_ 519 SC_ERR_CAN_PNHV_Stat_AR2_TOut 7 "SNA" 6 "STOPPED" 5 "DEBOUNCING_PREVIOUS_FAILED" 4 "DEBOUNCING_PREVIOUS_PASS" 3 "PREFAILED" 2 "PREPASSED" 1 "RUNNING_FAILED" 0 "RUNNING_PASSED" ;
VAL_ 519 SC_ERR_CAN_OBL_Rq_AR2_TOut 7 "SNA" 6 "STOPPED" 5 "DEBOUNCING_PREVIOUS_FAILED" 4 "DEBOUNCING_PREVIOUS_PASS" 3 "PREFAILED" 2 "PREPASSED" 1 "RUNNING_FAILED" 0 "RUNNING_PASSED" ;
VAL_ 519 SC_ERR_CAN_LBC_CANHS_R_03_TOut 7 "SNA" 6 "STOPPED" 5 "DEBOUNCING_PREVIOUS_FAILED" 4 "DEBOUNCING_PREVIOUS_PASS" 3 "PREFAILED" 2 "PREPASSED" 1 "RUNNING_FAILED" 0 "RUNNING_PASSED" ;
VAL_ 519 SC_ERR_CAN_LBC_CANHS_R_02_TOut 7 "SNA" 6 "STOPPED" 5 "DEBOUNCING_PREVIOUS_FAILED" 4 "DEBOUNCING_PREVIOUS_PASS" 3 "PREFAILED" 2 "PREPASSED" 1 "RUNNING_FAILED" 0 "RUNNING_PASSED" ;
VAL_ 519 SC_ERR_VCC3_Vltg_Low 7 "SNA" 6 "STOPPED" 5 "DEBOUNCING_PREVIOUS_FAILED" 4 "DEBOUNCING_PREVIOUS_PASS" 3 "PREFAILED" 2 "PREPASSED" 1 "RUNNING_FAILED" 0 "RUNNING_PASSED" ;
VAL_ 519 SC_ERR_VCC3_Vltg_High 7 "SNA" 6 "STOPPED" 5 "DEBOUNCING_PREVIOUS_FAILED" 4 "DEBOUNCING_PREVIOUS_PASS" 3 "PREFAILED" 2 "PREPASSED" 1 "RUNNING_FAILED" 0 "RUNNING_PASSED" ;
VAL_ 519 SC_ERR_VCC2_Vltg_Low 7 "SNA" 6 "STOPPED" 5 "DEBOUNCING_PREVIOUS_FAILED" 4 "DEBOUNCING_PREVIOUS_PASS" 3 "PREFAILED" 2 "PREPASSED" 1 "RUNNING_FAILED" 0 "RUNNING_PASSED" ;
VAL_ 519 SC_ERR_VCC2_Vltg_High 7 "SNA" 6 "STOPPED" 5 "DEBOUNCING_PREVIOUS_FAILED" 4 "DEBOUNCING_PREVIOUS_PASS" 3 "PREFAILED" 2 "PREPASSED" 1 "RUNNING_FAILED" 0 "RUNNING_PASSED" ;
VAL_ 519 SC_ERR_VCC1_Vltg_Low 7 "SNA" 6 "STOPPED" 5 "DEBOUNCING_PREVIOUS_FAILED" 4 "DEBOUNCING_PREVIOUS_PASS" 3 "PREFAILED" 2 "PREPASSED" 1 "RUNNING_FAILED" 0 "RUNNING_PASSED" ;
VAL_ 519 SC_ERR_VCC1_Vltg_High 7 "SNA" 6 "STOPPED" 5 "DEBOUNCING_PREVIOUS_FAILED" 4 "DEBOUNCING_PREVIOUS_PASS" 3 "PREFAILED" 2 "PREPASSED" 1 "RUNNING_FAILED" 0 "RUNNING_PASSED" ;
VAL_ 519 SC_ERR_KL30c_Vltg_Low 7 "SNA" 6 "STOPPED" 5 "DEBOUNCING_PREVIOUS_FAILED" 4 "DEBOUNCING_PREVIOUS_PASS" 3 "PREFAILED" 2 "PREPASSED" 1 "RUNNING_FAILED" 0 "RUNNING_PASSED" ;
VAL_ 519 SC_ERR_KL30c_Vltg_High 7 "SNA" 6 "STOPPED" 5 "DEBOUNCING_PREVIOUS_FAILED" 4 "DEBOUNCING_PREVIOUS_PASS" 3 "PREFAILED" 2 "PREPASSED" 1 "RUNNING_FAILED" 0 "RUNNING_PASSED" ;
VAL_ 519 SC_ERR_KL30c_Trgd 7 "SNA" 6 "STOPPED" 5 "DEBOUNCING_PREVIOUS_FAILED" 4 "DEBOUNCING_PREVIOUS_PASS" 3 "PREFAILED" 2 "PREPASSED" 1 "RUNNING_FAILED" 0 "RUNNING_PASSED" ;
VAL_ 519 SC_ERR_KL30_Vltg_Low 7 "SNA" 6 "STOPPED" 5 "DEBOUNCING_PREVIOUS_FAILED" 4 "DEBOUNCING_PREVIOUS_PASS" 3 "PREFAILED" 2 "PREPASSED" 1 "RUNNING_FAILED" 0 "RUNNING_PASSED" ;
VAL_ 519 SC_ERR_KL30_Vltg_High 7 "SNA" 6 "STOPPED" 5 "DEBOUNCING_PREVIOUS_FAILED" 4 "DEBOUNCING_PREVIOUS_PASS" 3 "PREFAILED" 2 "PREPASSED" 1 "RUNNING_FAILED" 0 "RUNNING_PASSED" ;
VAL_ 519 SC_ERR_KL15_Vltg_Plaus 7 "SNA" 6 "STOPPED" 5 "DEBOUNCING_PREVIOUS_FAILED" 4 "DEBOUNCING_PREVIOUS_PASS" 3 "PREFAILED" 2 "PREPASSED" 1 "RUNNING_FAILED" 0 "RUNNING_PASSED" ;
VAL_ 519 SC_ERR_KL15_Vltg_High 7 "SNA" 6 "STOPPED" 5 "DEBOUNCING_PREVIOUS_FAILED" 4 "DEBOUNCING_PREVIOUS_PASS" 3 "PREFAILED" 2 "PREPASSED" 1 "RUNNING_FAILED" 0 "RUNNING_PASSED" ;
VAL_ 518 SC_ERR_Reserved_07_05 7 "SNA" 6 "STOPPED" 5 "DEBOUNCING_PREVIOUS_FAILED" 4 "DEBOUNCING_PREVIOUS_PASS" 3 "PREFAILED" 2 "PREPASSED" 1 "RUNNING_FAILED" 0 "RUNNING_PASSED" ;
VAL_ 518 SC_ERR_Reserved_07_04 7 "SNA" 6 "STOPPED" 5 "DEBOUNCING_PREVIOUS_FAILED" 4 "DEBOUNCING_PREVIOUS_PASS" 3 "PREFAILED" 2 "PREPASSED" 1 "RUNNING_FAILED" 0 "RUNNING_PASSED" ;
VAL_ 518 SC_ERR_Reserved_07_03 7 "SNA" 6 "STOPPED" 5 "DEBOUNCING_PREVIOUS_FAILED" 4 "DEBOUNCING_PREVIOUS_PASS" 3 "PREFAILED" 2 "PREPASSED" 1 "RUNNING_FAILED" 0 "RUNNING_PASSED" ;
VAL_ 518 SC_ERR_Reserved_07_02 7 "SNA" 6 "STOPPED" 5 "DEBOUNCING_PREVIOUS_FAILED" 4 "DEBOUNCING_PREVIOUS_PASS" 3 "PREFAILED" 2 "PREPASSED" 1 "RUNNING_FAILED" 0 "RUNNING_PASSED" ;
VAL_ 518 SC_ERR_Reserved_07_01 7 "SNA" 6 "STOPPED" 5 "DEBOUNCING_PREVIOUS_FAILED" 4 "DEBOUNCING_PREVIOUS_PASS" 3 "PREFAILED" 2 "PREPASSED" 1 "RUNNING_FAILED" 0 "RUNNING_PASSED" ;
VAL_ 518 SC_ERR_INTLK2_OL 7 "SNA" 6 "STOPPED" 5 "DEBOUNCING_PREVIOUS_FAILED" 4 "DEBOUNCING_PREVIOUS_PASS" 3 "PREFAILED" 2 "PREPASSED" 1 "RUNNING_FAILED" 0 "RUNNING_PASSED" ;
VAL_ 518 SC_ERR_INTLK1_OL 7 "SNA" 6 "STOPPED" 5 "DEBOUNCING_PREVIOUS_FAILED" 4 "DEBOUNCING_PREVIOUS_PASS" 3 "PREFAILED" 2 "PREPASSED" 1 "RUNNING_FAILED" 0 "RUNNING_PASSED" ;
VAL_ 518 SC_ERR_INTLK2_Vcc_Low 7 "SNA" 6 "STOPPED" 5 "DEBOUNCING_PREVIOUS_FAILED" 4 "DEBOUNCING_PREVIOUS_PASS" 3 "PREFAILED" 2 "PREPASSED" 1 "RUNNING_FAILED" 0 "RUNNING_PASSED" ;
VAL_ 518 SC_ERR_INTLK2_Vcc_High 7 "SNA" 6 "STOPPED" 5 "DEBOUNCING_PREVIOUS_FAILED" 4 "DEBOUNCING_PREVIOUS_PASS" 3 "PREFAILED" 2 "PREPASSED" 1 "RUNNING_FAILED" 0 "RUNNING_PASSED" ;
VAL_ 518 SC_ERR_INTLK2_SCG 7 "SNA" 6 "STOPPED" 5 "DEBOUNCING_PREVIOUS_FAILED" 4 "DEBOUNCING_PREVIOUS_PASS" 3 "PREFAILED" 2 "PREPASSED" 1 "RUNNING_FAILED" 0 "RUNNING_PASSED" ;
VAL_ 518 SC_ERR_INTLK2_SCB 7 "SNA" 6 "STOPPED" 5 "DEBOUNCING_PREVIOUS_FAILED" 4 "DEBOUNCING_PREVIOUS_PASS" 3 "PREFAILED" 2 "PREPASSED" 1 "RUNNING_FAILED" 0 "RUNNING_PASSED" ;
VAL_ 518 SC_ERR_INTLK2_Gen_defect 7 "SNA" 6 "STOPPED" 5 "DEBOUNCING_PREVIOUS_FAILED" 4 "DEBOUNCING_PREVIOUS_PASS" 3 "PREFAILED" 2 "PREPASSED" 1 "RUNNING_FAILED" 0 "RUNNING_PASSED" ;
VAL_ 518 SC_ERR_INTLK2_Frequency 7 "SNA" 6 "STOPPED" 5 "DEBOUNCING_PREVIOUS_FAILED" 4 "DEBOUNCING_PREVIOUS_PASS" 3 "PREFAILED" 2 "PREPASSED" 1 "RUNNING_FAILED" 0 "RUNNING_PASSED" ;
VAL_ 518 SC_ERR_INTLK2_Duty_Cycle 7 "SNA" 6 "STOPPED" 5 "DEBOUNCING_PREVIOUS_FAILED" 4 "DEBOUNCING_PREVIOUS_PASS" 3 "PREFAILED" 2 "PREPASSED" 1 "RUNNING_FAILED" 0 "RUNNING_PASSED" ;
VAL_ 518 SC_ERR_INTLK1_Vcc_Low 7 "SNA" 6 "STOPPED" 5 "DEBOUNCING_PREVIOUS_FAILED" 4 "DEBOUNCING_PREVIOUS_PASS" 3 "PREFAILED" 2 "PREPASSED" 1 "RUNNING_FAILED" 0 "RUNNING_PASSED" ;
VAL_ 518 SC_ERR_INTLK1_Vcc_High 7 "SNA" 6 "STOPPED" 5 "DEBOUNCING_PREVIOUS_FAILED" 4 "DEBOUNCING_PREVIOUS_PASS" 3 "PREFAILED" 2 "PREPASSED" 1 "RUNNING_FAILED" 0 "RUNNING_PASSED" ;
VAL_ 518 SC_ERR_INTLK1_SCG 7 "SNA" 6 "STOPPED" 5 "DEBOUNCING_PREVIOUS_FAILED" 4 "DEBOUNCING_PREVIOUS_PASS" 3 "PREFAILED" 2 "PREPASSED" 1 "RUNNING_FAILED" 0 "RUNNING_PASSED" ;
VAL_ 518 SC_ERR_INTLK1_SCB 7 "SNA" 6 "STOPPED" 5 "DEBOUNCING_PREVIOUS_FAILED" 4 "DEBOUNCING_PREVIOUS_PASS" 3 "PREFAILED" 2 "PREPASSED" 1 "RUNNING_FAILED" 0 "RUNNING_PASSED" ;
VAL_ 518 SC_ERR_INTLK1_Gen_defect 7 "SNA" 6 "STOPPED" 5 "DEBOUNCING_PREVIOUS_FAILED" 4 "DEBOUNCING_PREVIOUS_PASS" 3 "PREFAILED" 2 "PREPASSED" 1 "RUNNING_FAILED" 0 "RUNNING_PASSED" ;
VAL_ 518 SC_ERR_INTLK1_Frequency 7 "SNA" 6 "STOPPED" 5 "DEBOUNCING_PREVIOUS_FAILED" 4 "DEBOUNCING_PREVIOUS_PASS" 3 "PREFAILED" 2 "PREPASSED" 1 "RUNNING_FAILED" 0 "RUNNING_PASSED" ;
VAL_ 518 SC_ERR_INTLK1_Duty_Cycle 7 "SNA" 6 "STOPPED" 5 "DEBOUNCING_PREVIOUS_FAILED" 4 "DEBOUNCING_PREVIOUS_PASS" 3 "PREFAILED" 2 "PREPASSED" 1 "RUNNING_FAILED" 0 "RUNNING_PASSED" ;
VAL_ 517 SC_ERR_Reserved_06_03 7 "SNA" 6 "STOPPED" 5 "DEBOUNCING_PREVIOUS_FAILED" 4 "DEBOUNCING_PREVIOUS_PASS" 3 "PREFAILED" 2 "PREPASSED" 1 "RUNNING_FAILED" 0 "RUNNING_PASSED" ;
VAL_ 517 SC_ERR_Reserved_06_02 7 "SNA" 6 "STOPPED" 5 "DEBOUNCING_PREVIOUS_FAILED" 4 "DEBOUNCING_PREVIOUS_PASS" 3 "PREFAILED" 2 "PREPASSED" 1 "RUNNING_FAILED" 0 "RUNNING_PASSED" ;
VAL_ 517 SC_ERR_Reserved_06_01 7 "SNA" 6 "STOPPED" 5 "DEBOUNCING_PREVIOUS_FAILED" 4 "DEBOUNCING_PREVIOUS_PASS" 3 "PREFAILED" 2 "PREPASSED" 1 "RUNNING_FAILED" 0 "RUNNING_PASSED" ;
VAL_ 517 SC_ERR_MSW_Pre_Temp 7 "SNA" 6 "STOPPED" 5 "DEBOUNCING_PREVIOUS_FAILED" 4 "DEBOUNCING_PREVIOUS_PASS" 3 "PREFAILED" 2 "PREPASSED" 1 "RUNNING_FAILED" 0 "RUNNING_PASSED" ;
VAL_ 517 SC_ERR_MSW_LnkVltg_High 7 "SNA" 6 "STOPPED" 5 "DEBOUNCING_PREVIOUS_FAILED" 4 "DEBOUNCING_PREVIOUS_PASS" 3 "PREFAILED" 2 "PREPASSED" 1 "RUNNING_FAILED" 0 "RUNNING_PASSED" ;
VAL_ 517 SC_ERR_MSW_Vltg_Diff 7 "SNA" 6 "STOPPED" 5 "DEBOUNCING_PREVIOUS_FAILED" 4 "DEBOUNCING_PREVIOUS_PASS" 3 "PREFAILED" 2 "PREPASSED" 1 "RUNNING_FAILED" 0 "RUNNING_PASSED" ;
VAL_ 517 SC_ERR_MSW_Pre_Time 7 "SNA" 6 "STOPPED" 5 "DEBOUNCING_PREVIOUS_FAILED" 4 "DEBOUNCING_PREVIOUS_PASS" 3 "PREFAILED" 2 "PREPASSED" 1 "RUNNING_FAILED" 0 "RUNNING_PASSED" ;
VAL_ 517 SC_ERR_MSW_Pre_Crnt 7 "SNA" 6 "STOPPED" 5 "DEBOUNCING_PREVIOUS_FAILED" 4 "DEBOUNCING_PREVIOUS_PASS" 3 "PREFAILED" 2 "PREPASSED" 1 "RUNNING_FAILED" 0 "RUNNING_PASSED" ;
VAL_ 517 SC_ERR_MSW_Pre_Stuck_Opn 7 "SNA" 6 "STOPPED" 5 "DEBOUNCING_PREVIOUS_FAILED" 4 "DEBOUNCING_PREVIOUS_PASS" 3 "PREFAILED" 2 "PREPASSED" 1 "RUNNING_FAILED" 0 "RUNNING_PASSED" ;
VAL_ 517 SC_ERR_MSW_Pre_Stuck_Cls 7 "SNA" 6 "STOPPED" 5 "DEBOUNCING_PREVIOUS_FAILED" 4 "DEBOUNCING_PREVIOUS_PASS" 3 "PREFAILED" 2 "PREPASSED" 1 "RUNNING_FAILED" 0 "RUNNING_PASSED" ;
VAL_ 517 SC_ERR_MSW_Plus_Stuck_Opn 7 "SNA" 6 "STOPPED" 5 "DEBOUNCING_PREVIOUS_FAILED" 4 "DEBOUNCING_PREVIOUS_PASS" 3 "PREFAILED" 2 "PREPASSED" 1 "RUNNING_FAILED" 0 "RUNNING_PASSED" ;
VAL_ 517 SC_ERR_MSW_Plus_Stuck_Cls 7 "SNA" 6 "STOPPED" 5 "DEBOUNCING_PREVIOUS_FAILED" 4 "DEBOUNCING_PREVIOUS_PASS" 3 "PREFAILED" 2 "PREPASSED" 1 "RUNNING_FAILED" 0 "RUNNING_PASSED" ;
VAL_ 517 SC_ERR_MSW_Minus_Stuck_Opn 7 "SNA" 6 "STOPPED" 5 "DEBOUNCING_PREVIOUS_FAILED" 4 "DEBOUNCING_PREVIOUS_PASS" 3 "PREFAILED" 2 "PREPASSED" 1 "RUNNING_FAILED" 0 "RUNNING_PASSED" ;
VAL_ 517 SC_ERR_MSW_Minus_Stuck_Cls 7 "SNA" 6 "STOPPED" 5 "DEBOUNCING_PREVIOUS_FAILED" 4 "DEBOUNCING_PREVIOUS_PASS" 3 "PREFAILED" 2 "PREPASSED" 1 "RUNNING_FAILED" 0 "RUNNING_PASSED" ;
VAL_ 517 SC_ERR_MSW_Pre_Ls_SCG 7 "SNA" 6 "STOPPED" 5 "DEBOUNCING_PREVIOUS_FAILED" 4 "DEBOUNCING_PREVIOUS_PASS" 3 "PREFAILED" 2 "PREPASSED" 1 "RUNNING_FAILED" 0 "RUNNING_PASSED" ;
VAL_ 517 SC_ERR_MSW_Pre_Ls_SCB 7 "SNA" 6 "STOPPED" 5 "DEBOUNCING_PREVIOUS_FAILED" 4 "DEBOUNCING_PREVIOUS_PASS" 3 "PREFAILED" 2 "PREPASSED" 1 "RUNNING_FAILED" 0 "RUNNING_PASSED" ;
VAL_ 517 SC_ERR_MSW_Pre_Ls_OL 7 "SNA" 6 "STOPPED" 5 "DEBOUNCING_PREVIOUS_FAILED" 4 "DEBOUNCING_PREVIOUS_PASS" 3 "PREFAILED" 2 "PREPASSED" 1 "RUNNING_FAILED" 0 "RUNNING_PASSED" ;
VAL_ 517 SC_ERR_MSW_Pre_Hs_SCG 7 "SNA" 6 "STOPPED" 5 "DEBOUNCING_PREVIOUS_FAILED" 4 "DEBOUNCING_PREVIOUS_PASS" 3 "PREFAILED" 2 "PREPASSED" 1 "RUNNING_FAILED" 0 "RUNNING_PASSED" ;
VAL_ 517 SC_ERR_MSW_Pre_Hs_SCB 7 "SNA" 6 "STOPPED" 5 "DEBOUNCING_PREVIOUS_FAILED" 4 "DEBOUNCING_PREVIOUS_PASS" 3 "PREFAILED" 2 "PREPASSED" 1 "RUNNING_FAILED" 0 "RUNNING_PASSED" ;
VAL_ 517 SC_ERR_MSW_Pre_Hs_OL 7 "SNA" 6 "STOPPED" 5 "DEBOUNCING_PREVIOUS_FAILED" 4 "DEBOUNCING_PREVIOUS_PASS" 3 "PREFAILED" 2 "PREPASSED" 1 "RUNNING_FAILED" 0 "RUNNING_PASSED" ;
VAL_ 516 SC_ERR_Reserved_05_03 7 "SNA" 6 "STOPPED" 5 "DEBOUNCING_PREVIOUS_FAILED" 4 "DEBOUNCING_PREVIOUS_PASS" 3 "PREFAILED" 2 "PREPASSED" 1 "RUNNING_FAILED" 0 "RUNNING_PASSED" ;
VAL_ 516 SC_ERR_Reserved_05_02 7 "SNA" 6 "STOPPED" 5 "DEBOUNCING_PREVIOUS_FAILED" 4 "DEBOUNCING_PREVIOUS_PASS" 3 "PREFAILED" 2 "PREPASSED" 1 "RUNNING_FAILED" 0 "RUNNING_PASSED" ;
VAL_ 516 SC_ERR_Reserved_05_01 7 "SNA" 6 "STOPPED" 5 "DEBOUNCING_PREVIOUS_FAILED" 4 "DEBOUNCING_PREVIOUS_PASS" 3 "PREFAILED" 2 "PREPASSED" 1 "RUNNING_FAILED" 0 "RUNNING_PASSED" ;
VAL_ 516 SC_ERR_MSW_Plus_Ls_SCG 7 "SNA" 6 "STOPPED" 5 "DEBOUNCING_PREVIOUS_FAILED" 4 "DEBOUNCING_PREVIOUS_PASS" 3 "PREFAILED" 2 "PREPASSED" 1 "RUNNING_FAILED" 0 "RUNNING_PASSED" ;
VAL_ 516 SC_ERR_MSW_Plus_Ls_SCB 7 "SNA" 6 "STOPPED" 5 "DEBOUNCING_PREVIOUS_FAILED" 4 "DEBOUNCING_PREVIOUS_PASS" 3 "PREFAILED" 2 "PREPASSED" 1 "RUNNING_FAILED" 0 "RUNNING_PASSED" ;
VAL_ 516 SC_ERR_MSW_Plus_Ls_OL 7 "SNA" 6 "STOPPED" 5 "DEBOUNCING_PREVIOUS_FAILED" 4 "DEBOUNCING_PREVIOUS_PASS" 3 "PREFAILED" 2 "PREPASSED" 1 "RUNNING_FAILED" 0 "RUNNING_PASSED" ;
VAL_ 516 SC_ERR_MSW_Plus_Hs_SCG 7 "SNA" 6 "STOPPED" 5 "DEBOUNCING_PREVIOUS_FAILED" 4 "DEBOUNCING_PREVIOUS_PASS" 3 "PREFAILED" 2 "PREPASSED" 1 "RUNNING_FAILED" 0 "RUNNING_PASSED" ;
VAL_ 516 SC_ERR_MSW_Plus_Hs_SCB 7 "SNA" 6 "STOPPED" 5 "DEBOUNCING_PREVIOUS_FAILED" 4 "DEBOUNCING_PREVIOUS_PASS" 3 "PREFAILED" 2 "PREPASSED" 1 "RUNNING_FAILED" 0 "RUNNING_PASSED" ;
VAL_ 516 SC_ERR_MSW_Plus_Hs_OL 7 "SNA" 6 "STOPPED" 5 "DEBOUNCING_PREVIOUS_FAILED" 4 "DEBOUNCING_PREVIOUS_PASS" 3 "PREFAILED" 2 "PREPASSED" 1 "RUNNING_FAILED" 0 "RUNNING_PASSED" ;
VAL_ 516 SC_ERR_MSW_Minus_Ls_SCG 7 "SNA" 6 "STOPPED" 5 "DEBOUNCING_PREVIOUS_FAILED" 4 "DEBOUNCING_PREVIOUS_PASS" 3 "PREFAILED" 2 "PREPASSED" 1 "RUNNING_FAILED" 0 "RUNNING_PASSED" ;
VAL_ 516 SC_ERR_MSW_Minus_Ls_SCB 7 "SNA" 6 "STOPPED" 5 "DEBOUNCING_PREVIOUS_FAILED" 4 "DEBOUNCING_PREVIOUS_PASS" 3 "PREFAILED" 2 "PREPASSED" 1 "RUNNING_FAILED" 0 "RUNNING_PASSED" ;
VAL_ 516 SC_ERR_MSW_Minus_Ls_OL 7 "SNA" 6 "STOPPED" 5 "DEBOUNCING_PREVIOUS_FAILED" 4 "DEBOUNCING_PREVIOUS_PASS" 3 "PREFAILED" 2 "PREPASSED" 1 "RUNNING_FAILED" 0 "RUNNING_PASSED" ;
VAL_ 516 SC_ERR_MSW_Minus_Hs_SCG 7 "SNA" 6 "STOPPED" 5 "DEBOUNCING_PREVIOUS_FAILED" 4 "DEBOUNCING_PREVIOUS_PASS" 3 "PREFAILED" 2 "PREPASSED" 1 "RUNNING_FAILED" 0 "RUNNING_PASSED" ;
VAL_ 516 SC_ERR_MSW_Minus_Hs_SCB 7 "SNA" 6 "STOPPED" 5 "DEBOUNCING_PREVIOUS_FAILED" 4 "DEBOUNCING_PREVIOUS_PASS" 3 "PREFAILED" 2 "PREPASSED" 1 "RUNNING_FAILED" 0 "RUNNING_PASSED" ;
VAL_ 516 SC_ERR_MSW_Minus_Hs_OL 7 "SNA" 6 "STOPPED" 5 "DEBOUNCING_PREVIOUS_FAILED" 4 "DEBOUNCING_PREVIOUS_PASS" 3 "PREFAILED" 2 "PREPASSED" 1 "RUNNING_FAILED" 0 "RUNNING_PASSED" ;
VAL_ 516 SC_ERR_MSW_Aging_Pre_Warn 7 "SNA" 6 "STOPPED" 5 "DEBOUNCING_PREVIOUS_FAILED" 4 "DEBOUNCING_PREVIOUS_PASS" 3 "PREFAILED" 2 "PREPASSED" 1 "RUNNING_FAILED" 0 "RUNNING_PASSED" ;
VAL_ 516 SC_ERR_MSW_Aging_Pre 7 "SNA" 6 "STOPPED" 5 "DEBOUNCING_PREVIOUS_FAILED" 4 "DEBOUNCING_PREVIOUS_PASS" 3 "PREFAILED" 2 "PREPASSED" 1 "RUNNING_FAILED" 0 "RUNNING_PASSED" ;
VAL_ 516 SC_ERR_MSW_Aging_Plus_Warn 7 "SNA" 6 "STOPPED" 5 "DEBOUNCING_PREVIOUS_FAILED" 4 "DEBOUNCING_PREVIOUS_PASS" 3 "PREFAILED" 2 "PREPASSED" 1 "RUNNING_FAILED" 0 "RUNNING_PASSED" ;
VAL_ 516 SC_ERR_MSW_Aging_Plus 7 "SNA" 6 "STOPPED" 5 "DEBOUNCING_PREVIOUS_FAILED" 4 "DEBOUNCING_PREVIOUS_PASS" 3 "PREFAILED" 2 "PREPASSED" 1 "RUNNING_FAILED" 0 "RUNNING_PASSED" ;
VAL_ 516 SC_ERR_MSW_Aging_Minus_Warn 7 "SNA" 6 "STOPPED" 5 "DEBOUNCING_PREVIOUS_FAILED" 4 "DEBOUNCING_PREVIOUS_PASS" 3 "PREFAILED" 2 "PREPASSED" 1 "RUNNING_FAILED" 0 "RUNNING_PASSED" ;
VAL_ 516 SC_ERR_MSW_Aging_Minus 7 "SNA" 6 "STOPPED" 5 "DEBOUNCING_PREVIOUS_FAILED" 4 "DEBOUNCING_PREVIOUS_PASS" 3 "PREFAILED" 2 "PREPASSED" 1 "RUNNING_FAILED" 0 "RUNNING_PASSED" ;
VAL_ 515 SC_ERR_Reserved_04_03 7 "SNA" 6 "STOPPED" 5 "DEBOUNCING_PREVIOUS_FAILED" 4 "DEBOUNCING_PREVIOUS_PASS" 3 "PREFAILED" 2 "PREPASSED" 1 "RUNNING_FAILED" 0 "RUNNING_PASSED" ;
VAL_ 515 SC_ERR_Reserved_04_02 7 "SNA" 6 "STOPPED" 5 "DEBOUNCING_PREVIOUS_FAILED" 4 "DEBOUNCING_PREVIOUS_PASS" 3 "PREFAILED" 2 "PREPASSED" 1 "RUNNING_FAILED" 0 "RUNNING_PASSED" ;
VAL_ 515 SC_ERR_Reserved_04_01 7 "SNA" 6 "STOPPED" 5 "DEBOUNCING_PREVIOUS_FAILED" 4 "DEBOUNCING_PREVIOUS_PASS" 3 "PREFAILED" 2 "PREPASSED" 1 "RUNNING_FAILED" 0 "RUNNING_PASSED" ;
VAL_ 515 SC_ERR_CSE1_PCB_Temp2_High 7 "SNA" 6 "STOPPED" 5 "DEBOUNCING_PREVIOUS_FAILED" 4 "DEBOUNCING_PREVIOUS_PASS" 3 "PREFAILED" 2 "PREPASSED" 1 "RUNNING_FAILED" 0 "RUNNING_PASSED" ;
VAL_ 515 SC_ERR_CSE2_PCB_Temp2_RNGL 7 "SNA" 6 "STOPPED" 5 "DEBOUNCING_PREVIOUS_FAILED" 4 "DEBOUNCING_PREVIOUS_PASS" 3 "PREFAILED" 2 "PREPASSED" 1 "RUNNING_FAILED" 0 "RUNNING_PASSED" ;
VAL_ 515 SC_ERR_CSE2_PCB_Temp2_RNGH 7 "SNA" 6 "STOPPED" 5 "DEBOUNCING_PREVIOUS_FAILED" 4 "DEBOUNCING_PREVIOUS_PASS" 3 "PREFAILED" 2 "PREPASSED" 1 "RUNNING_FAILED" 0 "RUNNING_PASSED" ;
VAL_ 515 SC_ERR_CSE2_PCB_Temp2_High 7 "SNA" 6 "STOPPED" 5 "DEBOUNCING_PREVIOUS_FAILED" 4 "DEBOUNCING_PREVIOUS_PASS" 3 "PREFAILED" 2 "PREPASSED" 1 "RUNNING_FAILED" 0 "RUNNING_PASSED" ;
VAL_ 515 SC_ERR_CSE2_PCB_Temp1_RNGL 7 "SNA" 6 "STOPPED" 5 "DEBOUNCING_PREVIOUS_FAILED" 4 "DEBOUNCING_PREVIOUS_PASS" 3 "PREFAILED" 2 "PREPASSED" 1 "RUNNING_FAILED" 0 "RUNNING_PASSED" ;
VAL_ 515 SC_ERR_CSE2_PCB_Temp1_RNGH 7 "SNA" 6 "STOPPED" 5 "DEBOUNCING_PREVIOUS_FAILED" 4 "DEBOUNCING_PREVIOUS_PASS" 3 "PREFAILED" 2 "PREPASSED" 1 "RUNNING_FAILED" 0 "RUNNING_PASSED" ;
VAL_ 515 SC_ERR_CSE2_PCB_Temp1_High 7 "SNA" 6 "STOPPED" 5 "DEBOUNCING_PREVIOUS_FAILED" 4 "DEBOUNCING_PREVIOUS_PASS" 3 "PREFAILED" 2 "PREPASSED" 1 "RUNNING_FAILED" 0 "RUNNING_PASSED" ;
VAL_ 515 SC_ERR_CSE2_Fault_Line 7 "SNA" 6 "STOPPED" 5 "DEBOUNCING_PREVIOUS_FAILED" 4 "DEBOUNCING_PREVIOUS_PASS" 3 "PREFAILED" 2 "PREPASSED" 1 "RUNNING_FAILED" 0 "RUNNING_PASSED" ;
VAL_ 515 SC_ERR_CSE2_Daisy_Chain 7 "SNA" 6 "STOPPED" 5 "DEBOUNCING_PREVIOUS_FAILED" 4 "DEBOUNCING_PREVIOUS_PASS" 3 "PREFAILED" 2 "PREPASSED" 1 "RUNNING_FAILED" 0 "RUNNING_PASSED" ;
VAL_ 515 SC_ERR_CSE2_Com_TOut 7 "SNA" 6 "STOPPED" 5 "DEBOUNCING_PREVIOUS_FAILED" 4 "DEBOUNCING_PREVIOUS_PASS" 3 "PREFAILED" 2 "PREPASSED" 1 "RUNNING_FAILED" 0 "RUNNING_PASSED" ;
VAL_ 515 SC_ERR_CSE1_PCB_Temp2_RNGL 7 "SNA" 6 "STOPPED" 5 "DEBOUNCING_PREVIOUS_FAILED" 4 "DEBOUNCING_PREVIOUS_PASS" 3 "PREFAILED" 2 "PREPASSED" 1 "RUNNING_FAILED" 0 "RUNNING_PASSED" ;
VAL_ 515 SC_ERR_CSE1_PCB_Temp2_RNGH 7 "SNA" 6 "STOPPED" 5 "DEBOUNCING_PREVIOUS_FAILED" 4 "DEBOUNCING_PREVIOUS_PASS" 3 "PREFAILED" 2 "PREPASSED" 1 "RUNNING_FAILED" 0 "RUNNING_PASSED" ;
VAL_ 515 SC_ERR_CSE1_PCB_Temp1_RNGL 7 "SNA" 6 "STOPPED" 5 "DEBOUNCING_PREVIOUS_FAILED" 4 "DEBOUNCING_PREVIOUS_PASS" 3 "PREFAILED" 2 "PREPASSED" 1 "RUNNING_FAILED" 0 "RUNNING_PASSED" ;
VAL_ 515 SC_ERR_CSE1_PCB_Temp1_RNGH 7 "SNA" 6 "STOPPED" 5 "DEBOUNCING_PREVIOUS_FAILED" 4 "DEBOUNCING_PREVIOUS_PASS" 3 "PREFAILED" 2 "PREPASSED" 1 "RUNNING_FAILED" 0 "RUNNING_PASSED" ;
VAL_ 515 SC_ERR_CSE1_PCB_Temp1_High 7 "SNA" 6 "STOPPED" 5 "DEBOUNCING_PREVIOUS_FAILED" 4 "DEBOUNCING_PREVIOUS_PASS" 3 "PREFAILED" 2 "PREPASSED" 1 "RUNNING_FAILED" 0 "RUNNING_PASSED" ;
VAL_ 515 SC_ERR_CSE1_Fault_Line 7 "SNA" 6 "STOPPED" 5 "DEBOUNCING_PREVIOUS_FAILED" 4 "DEBOUNCING_PREVIOUS_PASS" 3 "PREFAILED" 2 "PREPASSED" 1 "RUNNING_FAILED" 0 "RUNNING_PASSED" ;
VAL_ 515 SC_ERR_CSE1_Daisy_Chain 7 "SNA" 6 "STOPPED" 5 "DEBOUNCING_PREVIOUS_FAILED" 4 "DEBOUNCING_PREVIOUS_PASS" 3 "PREFAILED" 2 "PREPASSED" 1 "RUNNING_FAILED" 0 "RUNNING_PASSED" ;
VAL_ 515 SC_ERR_CSE1_Com_TOut 7 "SNA" 6 "STOPPED" 5 "DEBOUNCING_PREVIOUS_FAILED" 4 "DEBOUNCING_PREVIOUS_PASS" 3 "PREFAILED" 2 "PREPASSED" 1 "RUNNING_FAILED" 0 "RUNNING_PASSED" ;
VAL_ 514 SC_ERR_FUSE1_Pack_RNGL 7 "SNA" 6 "STOPPED" 5 "DEBOUNCING_PREVIOUS_FAILED" 4 "DEBOUNCING_PREVIOUS_PASS" 3 "PREFAILED" 2 "PREPASSED" 1 "RUNNING_FAILED" 0 "RUNNING_PASSED" ;
VAL_ 514 SC_ERR_FUSE1_Pack_RNGH 7 "SNA" 6 "STOPPED" 5 "DEBOUNCING_PREVIOUS_FAILED" 4 "DEBOUNCING_PREVIOUS_PASS" 3 "PREFAILED" 2 "PREPASSED" 1 "RUNNING_FAILED" 0 "RUNNING_PASSED" ;
VAL_ 514 SC_ERR_FUSE1_Pack_OL 7 "SNA" 6 "STOPPED" 5 "DEBOUNCING_PREVIOUS_FAILED" 4 "DEBOUNCING_PREVIOUS_PASS" 3 "PREFAILED" 2 "PREPASSED" 1 "RUNNING_FAILED" 0 "RUNNING_PASSED" ;
VAL_ 514 SC_ERR_FUSE1_Link_RNGL 7 "SNA" 6 "STOPPED" 5 "DEBOUNCING_PREVIOUS_FAILED" 4 "DEBOUNCING_PREVIOUS_PASS" 3 "PREFAILED" 2 "PREPASSED" 1 "RUNNING_FAILED" 0 "RUNNING_PASSED" ;
VAL_ 514 SC_ERR_FUSE1_Link_RNGH 7 "SNA" 6 "STOPPED" 5 "DEBOUNCING_PREVIOUS_FAILED" 4 "DEBOUNCING_PREVIOUS_PASS" 3 "PREFAILED" 2 "PREPASSED" 1 "RUNNING_FAILED" 0 "RUNNING_PASSED" ;
VAL_ 514 SC_ERR_FUSE1_Link_OL 7 "SNA" 6 "STOPPED" 5 "DEBOUNCING_PREVIOUS_FAILED" 4 "DEBOUNCING_PREVIOUS_PASS" 3 "PREFAILED" 2 "PREPASSED" 1 "RUNNING_FAILED" 0 "RUNNING_PASSED" ;
VAL_ 514 SC_ERR_FUSE1_Blown 7 "SNA" 6 "STOPPED" 5 "DEBOUNCING_PREVIOUS_FAILED" 4 "DEBOUNCING_PREVIOUS_PASS" 3 "PREFAILED" 2 "PREPASSED" 1 "RUNNING_FAILED" 0 "RUNNING_PASSED" ;
VAL_ 514 SC_ERR_PCK_Vltg_RNGL 7 "SNA" 6 "STOPPED" 5 "DEBOUNCING_PREVIOUS_FAILED" 4 "DEBOUNCING_PREVIOUS_PASS" 3 "PREFAILED" 2 "PREPASSED" 1 "RUNNING_FAILED" 0 "RUNNING_PASSED" ;
VAL_ 514 SC_ERR_PCK_Vltg_RNGH 7 "SNA" 6 "STOPPED" 5 "DEBOUNCING_PREVIOUS_FAILED" 4 "DEBOUNCING_PREVIOUS_PASS" 3 "PREFAILED" 2 "PREPASSED" 1 "RUNNING_FAILED" 0 "RUNNING_PASSED" ;
VAL_ 514 SC_ERR_PCK_Vltg_Plaus 7 "SNA" 6 "STOPPED" 5 "DEBOUNCING_PREVIOUS_FAILED" 4 "DEBOUNCING_PREVIOUS_PASS" 3 "PREFAILED" 2 "PREPASSED" 1 "RUNNING_FAILED" 0 "RUNNING_PASSED" ;
VAL_ 514 SC_ERR_PCK_Vltg_OL 7 "SNA" 6 "STOPPED" 5 "DEBOUNCING_PREVIOUS_FAILED" 4 "DEBOUNCING_PREVIOUS_PASS" 3 "PREFAILED" 2 "PREPASSED" 1 "RUNNING_FAILED" 0 "RUNNING_PASSED" ;
VAL_ 514 SC_ERR_LNK_Vltg_RNGL 7 "SNA" 6 "STOPPED" 5 "DEBOUNCING_PREVIOUS_FAILED" 4 "DEBOUNCING_PREVIOUS_PASS" 3 "PREFAILED" 2 "PREPASSED" 1 "RUNNING_FAILED" 0 "RUNNING_PASSED" ;
VAL_ 514 SC_ERR_LNK_Vltg_RNGH 7 "SNA" 6 "STOPPED" 5 "DEBOUNCING_PREVIOUS_FAILED" 4 "DEBOUNCING_PREVIOUS_PASS" 3 "PREFAILED" 2 "PREPASSED" 1 "RUNNING_FAILED" 0 "RUNNING_PASSED" ;
VAL_ 514 SC_ERR_LNK_Vltg_OL 7 "SNA" 6 "STOPPED" 5 "DEBOUNCING_PREVIOUS_FAILED" 4 "DEBOUNCING_PREVIOUS_PASS" 3 "PREFAILED" 2 "PREPASSED" 1 "RUNNING_FAILED" 0 "RUNNING_PASSED" ;
VAL_ 514 SC_ERR_FUSE2_Pack_RNGL 7 "SNA" 6 "STOPPED" 5 "DEBOUNCING_PREVIOUS_FAILED" 4 "DEBOUNCING_PREVIOUS_PASS" 3 "PREFAILED" 2 "PREPASSED" 1 "RUNNING_FAILED" 0 "RUNNING_PASSED" ;
VAL_ 514 SC_ERR_FUSE2_Pack_RNGH 7 "SNA" 6 "STOPPED" 5 "DEBOUNCING_PREVIOUS_FAILED" 4 "DEBOUNCING_PREVIOUS_PASS" 3 "PREFAILED" 2 "PREPASSED" 1 "RUNNING_FAILED" 0 "RUNNING_PASSED" ;
VAL_ 514 SC_ERR_FUSE2_Pack_OL 7 "SNA" 6 "STOPPED" 5 "DEBOUNCING_PREVIOUS_FAILED" 4 "DEBOUNCING_PREVIOUS_PASS" 3 "PREFAILED" 2 "PREPASSED" 1 "RUNNING_FAILED" 0 "RUNNING_PASSED" ;
VAL_ 514 SC_ERR_FUSE2_Link_RNGL 7 "SNA" 6 "STOPPED" 5 "DEBOUNCING_PREVIOUS_FAILED" 4 "DEBOUNCING_PREVIOUS_PASS" 3 "PREFAILED" 2 "PREPASSED" 1 "RUNNING_FAILED" 0 "RUNNING_PASSED" ;
VAL_ 514 SC_ERR_FUSE2_Link_RNGH 7 "SNA" 6 "STOPPED" 5 "DEBOUNCING_PREVIOUS_FAILED" 4 "DEBOUNCING_PREVIOUS_PASS" 3 "PREFAILED" 2 "PREPASSED" 1 "RUNNING_FAILED" 0 "RUNNING_PASSED" ;
VAL_ 514 SC_ERR_FUSE2_Link_OL 7 "SNA" 6 "STOPPED" 5 "DEBOUNCING_PREVIOUS_FAILED" 4 "DEBOUNCING_PREVIOUS_PASS" 3 "PREFAILED" 2 "PREPASSED" 1 "RUNNING_FAILED" 0 "RUNNING_PASSED" ;
VAL_ 514 SC_ERR_FUSE2_Blown 7 "SNA" 6 "STOPPED" 5 "DEBOUNCING_PREVIOUS_FAILED" 4 "DEBOUNCING_PREVIOUS_PASS" 3 "PREFAILED" 2 "PREPASSED" 1 "RUNNING_FAILED" 0 "RUNNING_PASSED" ;
VAL_ 513 SC_ERR_Reserved_02_04 7 "SNA" 6 "STOPPED" 5 "DEBOUNCING_PREVIOUS_FAILED" 4 "DEBOUNCING_PREVIOUS_PASS" 3 "PREFAILED" 2 "PREPASSED" 1 "RUNNING_FAILED" 0 "RUNNING_PASSED" ;
VAL_ 513 SC_ERR_Reserved_02_03 7 "SNA" 6 "STOPPED" 5 "DEBOUNCING_PREVIOUS_FAILED" 4 "DEBOUNCING_PREVIOUS_PASS" 3 "PREFAILED" 2 "PREPASSED" 1 "RUNNING_FAILED" 0 "RUNNING_PASSED" ;
VAL_ 513 SC_ERR_Reserved_02_02 7 "SNA" 6 "STOPPED" 5 "DEBOUNCING_PREVIOUS_FAILED" 4 "DEBOUNCING_PREVIOUS_PASS" 3 "PREFAILED" 2 "PREPASSED" 1 "RUNNING_FAILED" 0 "RUNNING_PASSED" ;
VAL_ 513 SC_ERR_Reserved_02_01 7 "SNA" 6 "STOPPED" 5 "DEBOUNCING_PREVIOUS_FAILED" 4 "DEBOUNCING_PREVIOUS_PASS" 3 "PREFAILED" 2 "PREPASSED" 1 "RUNNING_FAILED" 0 "RUNNING_PASSED" ;
VAL_ 513 SC_ERR_CSM1_Temp_High 7 "SNA" 6 "STOPPED" 5 "DEBOUNCING_PREVIOUS_FAILED" 4 "DEBOUNCING_PREVIOUS_PASS" 3 "PREFAILED" 2 "PREPASSED" 1 "RUNNING_FAILED" 0 "RUNNING_PASSED" ;
VAL_ 513 SC_ERR_CSM1_ROM 7 "SNA" 6 "STOPPED" 5 "DEBOUNCING_PREVIOUS_FAILED" 4 "DEBOUNCING_PREVIOUS_PASS" 3 "PREFAILED" 2 "PREPASSED" 1 "RUNNING_FAILED" 0 "RUNNING_PASSED" ;
VAL_ 513 SC_ERR_CSM1_FUSI_CrntDischrgHigh 7 "SNA" 6 "STOPPED" 5 "DEBOUNCING_PREVIOUS_FAILED" 4 "DEBOUNCING_PREVIOUS_PASS" 3 "PREFAILED" 2 "PREPASSED" 1 "RUNNING_FAILED" 0 "RUNNING_PASSED" ;
VAL_ 513 SC_ERR_CSM1_FUSI_Crnt_Chrg_High 7 "SNA" 6 "STOPPED" 5 "DEBOUNCING_PREVIOUS_FAILED" 4 "DEBOUNCING_PREVIOUS_PASS" 3 "PREFAILED" 2 "PREPASSED" 1 "RUNNING_FAILED" 0 "RUNNING_PASSED" ;
VAL_ 513 SC_ERR_CSM1_Crnt_Dischrg_RNGL 7 "SNA" 6 "STOPPED" 5 "DEBOUNCING_PREVIOUS_FAILED" 4 "DEBOUNCING_PREVIOUS_PASS" 3 "PREFAILED" 2 "PREPASSED" 1 "RUNNING_FAILED" 0 "RUNNING_PASSED" ;
VAL_ 513 SC_ERR_CSM1_Crnt_Chrg_RNGH 7 "SNA" 6 "STOPPED" 5 "DEBOUNCING_PREVIOUS_FAILED" 4 "DEBOUNCING_PREVIOUS_PASS" 3 "PREFAILED" 2 "PREPASSED" 1 "RUNNING_FAILED" 0 "RUNNING_PASSED" ;
VAL_ 513 SC_ERR_CSM1_Com_TOut 7 "SNA" 6 "STOPPED" 5 "DEBOUNCING_PREVIOUS_FAILED" 4 "DEBOUNCING_PREVIOUS_PASS" 3 "PREFAILED" 2 "PREPASSED" 1 "RUNNING_FAILED" 0 "RUNNING_PASSED" ;
VAL_ 513 SC_ERR_CSM_Plaus 7 "SNA" 6 "STOPPED" 5 "DEBOUNCING_PREVIOUS_FAILED" 4 "DEBOUNCING_PREVIOUS_PASS" 3 "PREFAILED" 2 "PREPASSED" 1 "RUNNING_FAILED" 0 "RUNNING_PASSED" ;
VAL_ 513 SC_ERR_CSM1_General 7 "SNA" 6 "STOPPED" 5 "DEBOUNCING_PREVIOUS_FAILED" 4 "DEBOUNCING_PREVIOUS_PASS" 3 "PREFAILED" 2 "PREPASSED" 1 "RUNNING_FAILED" 0 "RUNNING_PASSED" ;
VAL_ 513 SC_ERR_CSM2_SCG 7 "SNA" 6 "STOPPED" 5 "DEBOUNCING_PREVIOUS_FAILED" 4 "DEBOUNCING_PREVIOUS_PASS" 3 "PREFAILED" 2 "PREPASSED" 1 "RUNNING_FAILED" 0 "RUNNING_PASSED" ;
VAL_ 513 SC_ERR_CSM2_SCB 7 "SNA" 6 "STOPPED" 5 "DEBOUNCING_PREVIOUS_FAILED" 4 "DEBOUNCING_PREVIOUS_PASS" 3 "PREFAILED" 2 "PREPASSED" 1 "RUNNING_FAILED" 0 "RUNNING_PASSED" ;
VAL_ 513 SC_ERR_CSM2_ROM 7 "SNA" 6 "STOPPED" 5 "DEBOUNCING_PREVIOUS_FAILED" 4 "DEBOUNCING_PREVIOUS_PASS" 3 "PREFAILED" 2 "PREPASSED" 1 "RUNNING_FAILED" 0 "RUNNING_PASSED" ;
VAL_ 513 SC_ERR_CSM2_OL 7 "SNA" 6 "STOPPED" 5 "DEBOUNCING_PREVIOUS_FAILED" 4 "DEBOUNCING_PREVIOUS_PASS" 3 "PREFAILED" 2 "PREPASSED" 1 "RUNNING_FAILED" 0 "RUNNING_PASSED" ;
VAL_ 513 SC_ERR_CSM2_FUSI_CrntDischrgHigh 7 "SNA" 6 "STOPPED" 5 "DEBOUNCING_PREVIOUS_FAILED" 4 "DEBOUNCING_PREVIOUS_PASS" 3 "PREFAILED" 2 "PREPASSED" 1 "RUNNING_FAILED" 0 "RUNNING_PASSED" ;
VAL_ 513 SC_ERR_CSM2_FUSI_Crnt_Chrg_High 7 "SNA" 6 "STOPPED" 5 "DEBOUNCING_PREVIOUS_FAILED" 4 "DEBOUNCING_PREVIOUS_PASS" 3 "PREFAILED" 2 "PREPASSED" 1 "RUNNING_FAILED" 0 "RUNNING_PASSED" ;
VAL_ 513 SC_ERR_CSM2_Crnt_Dischrg_RNGL 7 "SNA" 6 "STOPPED" 5 "DEBOUNCING_PREVIOUS_FAILED" 4 "DEBOUNCING_PREVIOUS_PASS" 3 "PREFAILED" 2 "PREPASSED" 1 "RUNNING_FAILED" 0 "RUNNING_PASSED" ;
VAL_ 513 SC_ERR_CSM2_Crnt_Chrg_RNGH 7 "SNA" 6 "STOPPED" 5 "DEBOUNCING_PREVIOUS_FAILED" 4 "DEBOUNCING_PREVIOUS_PASS" 3 "PREFAILED" 2 "PREPASSED" 1 "RUNNING_FAILED" 0 "RUNNING_PASSED" ;
VAL_ 512 SC_ERR_CELLBLOCK3_Modul_Vltg_RAT 7 "SNA" 6 "STOPPED" 5 "DEBOUNCING_PREVIOUS_FAILED" 4 "DEBOUNCING_PREVIOUS_PASS" 3 "PREFAILED" 2 "PREPASSED" 1 "RUNNING_FAILED" 0 "RUNNING_PASSED" ;
VAL_ 512 SC_ERR_CELLBLOCK2_Modul_Vltg_RAT 7 "SNA" 6 "STOPPED" 5 "DEBOUNCING_PREVIOUS_FAILED" 4 "DEBOUNCING_PREVIOUS_PASS" 3 "PREFAILED" 2 "PREPASSED" 1 "RUNNING_FAILED" 0 "RUNNING_PASSED" ;
VAL_ 512 SC_ERR_CELLBLOCK1_Modul_Vltg_RAT 7 "SNA" 6 "STOPPED" 5 "DEBOUNCING_PREVIOUS_FAILED" 4 "DEBOUNCING_PREVIOUS_PASS" 3 "PREFAILED" 2 "PREPASSED" 1 "RUNNING_FAILED" 0 "RUNNING_PASSED" ;
VAL_ 512 SC_ERR_CELLBLOCK3_UnderVltg_Warn 7 "SNA" 6 "STOPPED" 5 "DEBOUNCING_PREVIOUS_FAILED" 4 "DEBOUNCING_PREVIOUS_PASS" 3 "PREFAILED" 2 "PREPASSED" 1 "RUNNING_FAILED" 0 "RUNNING_PASSED" ;
VAL_ 512 SC_ERR_CELLBLOCK2_UnderVltg_Warn 7 "SNA" 6 "STOPPED" 5 "DEBOUNCING_PREVIOUS_FAILED" 4 "DEBOUNCING_PREVIOUS_PASS" 3 "PREFAILED" 2 "PREPASSED" 1 "RUNNING_FAILED" 0 "RUNNING_PASSED" ;
VAL_ 512 SC_ERR_CELLBLOCK1_UnderVltg_Warn 7 "SNA" 6 "STOPPED" 5 "DEBOUNCING_PREVIOUS_FAILED" 4 "DEBOUNCING_PREVIOUS_PASS" 3 "PREFAILED" 2 "PREPASSED" 1 "RUNNING_FAILED" 0 "RUNNING_PASSED" ;
VAL_ 512 SC_ERR_CELLBLOCK3_OverVltg_Warn 7 "SNA" 6 "STOPPED" 5 "DEBOUNCING_PREVIOUS_FAILED" 4 "DEBOUNCING_PREVIOUS_PASS" 3 "PREFAILED" 2 "PREPASSED" 1 "RUNNING_FAILED" 0 "RUNNING_PASSED" ;
VAL_ 512 SC_ERR_CELLBLOCK2_OverVltg_Warn 7 "SNA" 6 "STOPPED" 5 "DEBOUNCING_PREVIOUS_FAILED" 4 "DEBOUNCING_PREVIOUS_PASS" 3 "PREFAILED" 2 "PREPASSED" 1 "RUNNING_FAILED" 0 "RUNNING_PASSED" ;
VAL_ 512 SC_ERR_CELLBLOCK1_OverVltg_Warn 7 "SNA" 6 "STOPPED" 5 "DEBOUNCING_PREVIOUS_FAILED" 4 "DEBOUNCING_PREVIOUS_PASS" 3 "PREFAILED" 2 "PREPASSED" 1 "RUNNING_FAILED" 0 "RUNNING_PASSED" ;
VAL_ 512 SC_ERR_CELLBLOCK3_FUSI_UnderVltg 7 "SNA" 6 "STOPPED" 5 "DEBOUNCING_PREVIOUS_FAILED" 4 "DEBOUNCING_PREVIOUS_PASS" 3 "PREFAILED" 2 "PREPASSED" 1 "RUNNING_FAILED" 0 "RUNNING_PASSED" ;
VAL_ 512 SC_ERR_CELLBLOCK2_FUSI_UnderVltg 7 "SNA" 6 "STOPPED" 5 "DEBOUNCING_PREVIOUS_FAILED" 4 "DEBOUNCING_PREVIOUS_PASS" 3 "PREFAILED" 2 "PREPASSED" 1 "RUNNING_FAILED" 0 "RUNNING_PASSED" ;
VAL_ 512 SC_ERR_CELLBLOCK1_FUSI_UnderVltg 7 "SNA" 6 "STOPPED" 5 "DEBOUNCING_PREVIOUS_FAILED" 4 "DEBOUNCING_PREVIOUS_PASS" 3 "PREFAILED" 2 "PREPASSED" 1 "RUNNING_FAILED" 0 "RUNNING_PASSED" ;
VAL_ 512 SC_ERR_CELLBLOCK3_FUSI_OverVltg 7 "SNA" 6 "STOPPED" 5 "DEBOUNCING_PREVIOUS_FAILED" 4 "DEBOUNCING_PREVIOUS_PASS" 3 "PREFAILED" 2 "PREPASSED" 1 "RUNNING_FAILED" 0 "RUNNING_PASSED" ;
VAL_ 512 SC_ERR_CELLBLOCK2_FUSI_OverVltg 7 "SNA" 6 "STOPPED" 5 "DEBOUNCING_PREVIOUS_FAILED" 4 "DEBOUNCING_PREVIOUS_PASS" 3 "PREFAILED" 2 "PREPASSED" 1 "RUNNING_FAILED" 0 "RUNNING_PASSED" ;
VAL_ 512 SC_ERR_CELLBLOCK1_FUSI_OverVltg 7 "SNA" 6 "STOPPED" 5 "DEBOUNCING_PREVIOUS_FAILED" 4 "DEBOUNCING_PREVIOUS_PASS" 3 "PREFAILED" 2 "PREPASSED" 1 "RUNNING_FAILED" 0 "RUNNING_PASSED" ;
VAL_ 512 SC_ERR_CELLBLOCK3_FUSI_OverTemp 7 "SNA" 6 "STOPPED" 5 "DEBOUNCING_PREVIOUS_FAILED" 4 "DEBOUNCING_PREVIOUS_PASS" 3 "PREFAILED" 2 "PREPASSED" 1 "RUNNING_FAILED" 0 "RUNNING_PASSED" ;
VAL_ 512 SC_ERR_CELLBLOCK2_FUSI_OverTemp 7 "SNA" 6 "STOPPED" 5 "DEBOUNCING_PREVIOUS_FAILED" 4 "DEBOUNCING_PREVIOUS_PASS" 3 "PREFAILED" 2 "PREPASSED" 1 "RUNNING_FAILED" 0 "RUNNING_PASSED" ;
VAL_ 512 SC_ERR_CELLBLOCK1_FUSI_OverTemp 7 "SNA" 6 "STOPPED" 5 "DEBOUNCING_PREVIOUS_FAILED" 4 "DEBOUNCING_PREVIOUS_PASS" 3 "PREFAILED" 2 "PREPASSED" 1 "RUNNING_FAILED" 0 "RUNNING_PASSED" ;
VAL_ 512 SC_ERR_CELLBLOCK3_FUSI_Open_Line 7 "SNA" 6 "STOPPED" 5 "DEBOUNCING_PREVIOUS_FAILED" 4 "DEBOUNCING_PREVIOUS_PASS" 3 "PREFAILED" 2 "PREPASSED" 1 "RUNNING_FAILED" 0 "RUNNING_PASSED" ;
VAL_ 512 SC_ERR_CELLBLOCK2_FUSI_Open_Line 7 "SNA" 6 "STOPPED" 5 "DEBOUNCING_PREVIOUS_FAILED" 4 "DEBOUNCING_PREVIOUS_PASS" 3 "PREFAILED" 2 "PREPASSED" 1 "RUNNING_FAILED" 0 "RUNNING_PASSED" ;
VAL_ 512 SC_ERR_CELLBLOCK1_FUSI_Open_Line 7 "SNA" 6 "STOPPED" 5 "DEBOUNCING_PREVIOUS_FAILED" 4 "DEBOUNCING_PREVIOUS_PASS" 3 "PREFAILED" 2 "PREPASSED" 1 "RUNNING_FAILED" 0 "RUNNING_PASSED" ;
VAL_ 32 BIW_v_EEPROM_Steps 98 "B06_WRITING_ISO" 97 "B06_WRITE_ISO" 82 "B05_WRITING_BLK" 81 "B05_WRITE_BLK" 66 "B04_WRITING_STRESS" 65 "B04_WRITE_STRESS" 50 "B03_WRITING_HISTORIC" 49 "B03_WRITE_HISTORIC" 34 "B02_WRITING_SOH" 33 "B02_WRITE_SOH" 18 "B01_WRITING_SOC" 17 "B01_WRITE_SOC" 0 "RESET_AND_WAIT" ;
VAL_ 32 BIW_v_EEPROM_Status 255 "FAILED" 170 "UNDEFINED" 2 "FINISHED" 1 "PENDING" 0 "INIT" ;
VAL_ 32 BIW_v_States 255 "SNA" 3 "PERIODICMAIN" 2 "MAIN" 1 "PREPROCESSING" 0 "INIT" ;
SIG_GROUP_ 321 GR_BCC_IN_T_BATT_29_30 1 : BCC_T_Batt_30 BCC_T_Batt_29;
SIG_GROUP_ 320 GR_BCC_IN_T_BATT_27_28 1 : BCC_T_Batt_28 BCC_T_Batt_27;
SIG_GROUP_ 319 GR_BCC_IN_T_BATT_25_26 1 : BCC_T_Batt_26 BCC_T_Batt_25;
SIG_GROUP_ 318 GR_BCC_IN_T_BATT_23_24 1 : BCC_T_Batt_24 BCC_T_Batt_23;
SIG_GROUP_ 317 GR_BCC_IN_T_BATT_21_22 1 : BCC_T_Batt_22 BCC_T_Batt_21;
SIG_GROUP_ 316 GR_BCC_IN_T_BATT_19_20 1 : BCC_T_Batt_20 BCC_T_Batt_19;
SIG_GROUP_ 315 GR_BCC_IN_T_BATT_17_18 1 : BCC_T_Batt_18 BCC_T_Batt_17;
SIG_GROUP_ 314 GR_BCC_IN_T_BATT_15_16 1 : BCC_T_Batt_16 BCC_T_Batt_15;
SIG_GROUP_ 313 GR_BCC_IN_T_BATT_13_14 1 : BCC_T_Batt_14 BCC_T_Batt_13;
SIG_GROUP_ 312 GR_BCC_IN_T_BATT_11_12 1 : BCC_T_Batt_12 BCC_T_Batt_11;
SIG_GROUP_ 524 GR_SSV_IDENT 1 : SSV_Version_Major SSV_Version_Minor SSV_Version_Release SSV_Version_DS_CRC;
SIG_GROUP_ 768 GR_CSM_IDENT 1 : CSM_Version_Major CSM_Version_Minor CSM_Version_Release CSM_Version_DS_CRC;
SIG_GROUP_ 852 GR_CSE03_IDENT 1 : CSE03_Version_Major CSE03_Version_Minor CSE03_Version_Release CSE03_Version_DS_CRC;
SIG_GROUP_ 850 GR_CSE02_IDENT 1 : CSE02_Version_Major CSE02_Version_Minor CSE02_Version_Release CSE02_Version_DS_CRC;
SIG_GROUP_ 848 GR_CSE01_IDENT 1 : CSE01_Version_Major CSE01_Version_Minor CSE01_Version_Release CSE01_Version_DS_CRC;
SIG_GROUP_ 311 GR_BCC_IN_T_BATT_09_10 1 : BCC_T_Batt_10 BCC_T_Batt_09;
SIG_GROUP_ 310 GR_BCC_IN_T_BATT_07_08 1 : BCC_T_Batt_07 BCC_T_Batt_08;
SIG_GROUP_ 853 GR_CSE03_ERRORS 1 : CSE03_E_FLAG CSE03_E_001_EMERGENCY_LINE CSE03_E_002_ARTICLE_NUMBER CSE03_E_003_LIM_OVERVOLT CSE03_E_004_LIM_UNDERVOLT CSE03_E_005_LIM_OVERTEMP CSE03_E_006_LIM_UNDERTEMP CSE03_E_007_LIM_OVERTEMP_PCB CSE03_E_008_LIM_CONTACT_RES CSE03_E_009 CSE03_E_010 CSE03_E_011 CSE03_E_012_MEAS_INIT CSE03_E_013_MEAS_READ_TEMP CSE03_E_014_MEAS_READ_VOLT CSE03_E_015_MEAS_START_TEMP CSE03_E_016_MEAS_START_VOLT CSE03_E_017_MEAS_SET_CONFIG CSE03_E_018_MEAS_VOLT_SEQ CSE03_E_019_MEAS_TEMP_SEQ CSE03_E_020_MEAS_VOLT_TIMEOUT CSE03_E_021_MEAS_TEMP_TIMEOUT CSE03_E_022_MEAS_REF_VOLT CSE03_E_023_MEAS_REF_TEMP CSE03_E_024_BAL_WRITE_CFRG CSE03_E_025_BAL_COMPARE_CFRG CSE03_E_026_BAL_THRESHOLD CSE03_E_027_BAL_CONTACT_RES CSE03_E_028 CSE03_E_029_SYS_GENERAL CSE03_E_030_SYS_SWITCH_DEF CSE03_E_031_SYS_DIFF_ZERO CSE03_E_032_SYS_TASK_TIME CSE03_E_033_SYS_DATASET_WARN CSE03_E_034_SYS_DATASET CSE03_E_035 CSE03_E_036 CSE03_E_037_FLASH_CRC_CAN CSE03_E_038_FLASH_READ_CAN CSE03_E_039_FLASH_CRC_PROD CSE03_E_040_FLASH_READ_PROD CSE03_E_041 CSE03_E_042 CSE03_E_043_CAN_BUFFER_FULL CSE03_E_044_CAN_SEND_SEQ CSE03_E_045 CSE03_E_046 CSE03_E_047 CSE03_E_048_FST_LTC6801 CSE03_E_049_FST_STACK CSE03_E_050_FST_INTERRUPT CSE03_E_051_FST_RESET CSE03_E_052_FST_CPU CSE03_E_053_FST_RAM_STARTUP CSE03_E_054_FST_RAM_SECTION_1 CSE03_E_055_FST_RAM_SECTION_2 CSE03_E_056_FST_ROM CSE03_E_057 CSE03_E_058 CSE03_E_059 CSE03_E_060 CSE03_E_061 CSE03_E_062 CSE03_E_063;
SIG_GROUP_ 769 GR_CSM_ERRORS 1 : CSM_E_FLAG CSM_E_059 CSM_E_060 CSM_E_061 CSM_E_062 CSM_E_063 CSM_E_WRONG_ARTICLE_NUMBER CSM_E_WRONG_DATARECORD CSM_E_SYS_GENERAL CSM_E_IHM_CAR_CHECK CSM_E_IHM_TRR_CHECK CSM_E_IHM_ZZR_CHECK CSM_E_OCD CSM_E_IHM_INIT_OPM CSM_E_IHM_INIT_CAR CSM_E_IHM_INIT_TRR CSM_E_IHM_INIT_CRG CSM_E_IHM_INIT_CRA CSM_E_FLASH_CRC_CAN_PARA CSM_E_FLASH_READ_CAN_PARA CSM_E_FLASH_WRITE_CAN_PARA CSM_E_FLASH_CRC_PROD_DATA CSM_E_FLASH_READ_PROD_DATA CSM_E_FLASH_WRITE_PROD_DATA CSM_E_FLASH_CRC_IHM_PARA CSM_E_FLASH_READ_IHM_PARA CSM_E_FLASH_WRITE_IHM_PARA CSM_E_FLASH_CRC_CALIB_PARA CSM_E_FLASH_READ_CALIB_PARA CSM_E_FLASH_WRITE_CALIB_PARA CSM_E_FLASH_CRC_DATARECORD_A CSM_E_FLASH_CRC_DATARECORD_B CSM_E_MEAS_CURRENT_OUFLOW CSM_E_MEAS_U_BAT_OUFLOW CSM_E_MEAS_U_TRAC_P_OUFLOW CSM_E_MEAS_U_TRAC_N_OUFLOW CSM_E_MEAS_TEMPINT_OUFLOW CSM_E_CURRENT_CHARGE_MAX CSM_E_CURRENT_DISCHARGE_MAX CSM_E_VOLTAGE_BAT_MAX CSM_E_VOLTAGE_BAT_MIN CSM_E_VOLTAGE_TRAC_P_MAX CSM_E_VOLTAGE_TRAC_P_MIN CSM_E_VOLTAGE_TRAC_N_MAX CSM_E_VOLTAGE_TRAC_N_MIN CSM_E_TEMPERATURE_MAX CSM_E_TEMPERATURE_MIN CSM_E_I_OCD_CHARGE_OOR CSM_E_I_OCD_DISCHARGE_OOR CSM_E_TASK_TIME CSM_E_CAN_ERROR_ID CSM_E_SEND_CAN CSM_E_UBAT_COMPARE_IHM_UC CSM_E_INTERRUPT_MONITOR CSM_E_RESET_MONITOR CSM_E_STACK_MONITOR CSM_E_RAM_MONITOR CSM_E_ROM_MONITOR CSM_E_CPU_MONITOR CSM_E_U_REF CSM_E_BROKEN_WIRE CSM_E_MSW_AGE_WARN CSM_E_MSW_AGE_ERR CSM_E_EEPROM_READ_WRITE;
SIG_GROUP_ 851 GR_CSE02_ERRORS 1 : CSE02_E_FLAG CSE02_E_001_EMERGENCY_LINE CSE02_E_002_ARTICLE_NUMBER CSE02_E_003_LIM_OVERVOLT CSE02_E_004_LIM_UNDERVOLT CSE02_E_005_LIM_OVERTEMP CSE02_E_006_LIM_UNDERTEMP CSE02_E_007_LIM_OVERTEMP_PCB CSE02_E_008_LIM_CONTACT_RES CSE02_E_009 CSE02_E_010 CSE02_E_011 CSE02_E_012_MEAS_INIT CSE02_E_013_MEAS_READ_TEMP CSE02_E_014_MEAS_READ_VOLT CSE02_E_015_MEAS_START_TEMP CSE02_E_016_MEAS_START_VOLT CSE02_E_017_MEAS_SET_CONFIG CSE02_E_018_MEAS_VOLT_SEQ CSE02_E_019_MEAS_TEMP_SEQ CSE02_E_020_MEAS_VOLT_TIMEOUT CSE02_E_021_MEAS_TEMP_TIMEOUT CSE02_E_022_MEAS_REF_VOLT CSE02_E_023_MEAS_REF_TEMP CSE02_E_024_BAL_WRITE_CFRG CSE02_E_025_BAL_COMPARE_CFRG CSE02_E_026_BAL_THRESHOLD CSE02_E_027_BAL_CONTACT_RES CSE02_E_028 CSE02_E_029_SYS_GENERAL CSE02_E_030_SYS_SWITCH_DEF CSE02_E_031_SYS_DIFF_ZERO CSE02_E_032_SYS_TASK_TIME CSE02_E_033_SYS_DATASET_WARN CSE02_E_034_SYS_DATASET CSE02_E_035 CSE02_E_036 CSE02_E_038_FLASH_READ_CAN CSE02_E_037_FLASH_CRC_CAN CSE02_E_039_FLASH_CRC_PROD CSE02_E_040_FLASH_READ_PROD CSE02_E_041 CSE02_E_042 CSE02_E_043_CAN_BUFFER_FULL CSE02_E_044_CAN_SEND_SEQ CSE02_E_045 CSE02_E_046 CSE02_E_047 CSE02_E_048_FST_LTC6801 CSE02_E_049_FST_STACK CSE02_E_050_FST_INTERRUPT CSE02_E_051_FST_RESET CSE02_E_052_FST_CPU CSE02_E_053_FST_RAM_STARTUP CSE02_E_054_FST_RAM_SECTION_1 CSE02_E_055_FST_RAM_SECTION_2 CSE02_E_056_FST_ROM CSE02_E_057 CSE02_E_058 CSE02_E_059 CSE02_E_060 CSE02_E_061 CSE02_E_062 CSE02_E_063;
SIG_GROUP_ 849 GR_CSE01_ERRORS 1 : CSE01_E_001_EMERGENCY_LINE CSE01_E_002_ARTICLE_NUMBER CSE01_E_003_LIM_OVERVOLT CSE01_E_004_LIM_UNDERVOLT CSE01_E_005_LIM_OVERTEMP CSE01_E_006_LIM_UNDERTEMP CSE01_E_007_LIM_OVERTEMP_PCB CSE01_E_FLAG CSE01_E_008_LIM_CONTACT_RES CSE01_E_009 CSE01_E_010 CSE01_E_011 CSE01_E_012_MEAS_INIT CSE01_E_013_MEAS_READ_TEMP CSE01_E_014_MEAS_READ_VOLT CSE01_E_015_MEAS_START_TEMP CSE01_E_016_MEAS_START_VOLT CSE01_E_017_MEAS_SET_CONFIG CSE01_E_018_MEAS_VOLT_SEQ CSE01_E_019_MEAS_TEMP_SEQ CSE01_E_020_MEAS_VOLT_TIMEOUT CSE01_E_021_MEAS_TEMP_TIMEOUT CSE01_E_022_MEAS_REF_VOLT CSE01_E_023_MEAS_REF_TEMP CSE01_E_024_BAL_WRITE_CFRG CSE01_E_025_BAL_COMPARE_CFRG CSE01_E_026_BAL_THRESHOLD CSE01_E_027_BAL_CONTACT_RES CSE01_E_028 CSE01_E_029_SYS_GENERAL CSE01_E_030_SYS_SWITCH_DEF CSE01_E_031_SYS_DIFF_ZERO CSE01_E_032_SYS_TASK_TIME CSE01_E_033_SYS_DATASET_WARN CSE01_E_034_SYS_DATASET CSE01_E_035 CSE01_E_036 CSE01_E_038_FLASH_READ_CAN CSE01_E_037_FLASH_CRC_CAN CSE01_E_039_FLASH_CRC_PROD CSE01_E_040_FLASH_READ_PROD CSE01_E_041 CSE01_E_042 CSE01_E_043_CAN_BUFFER_FULL CSE01_E_044_CAN_SEND_SEQ CSE01_E_045 CSE01_E_046 CSE01_E_047 CSE01_E_048_FST_LTC6801 CSE01_E_049_FST_STACK CSE01_E_050_FST_INTERRUPT CSE01_E_051_FST_RESET CSE01_E_052_FST_CPU CSE01_E_053_FST_RAM_STARTUP CSE01_E_054_FST_RAM_SECTION_1 CSE01_E_055_FST_RAM_SECTION_2 CSE01_E_056_FST_ROM CSE01_E_057 CSE01_E_058 CSE01_E_059 CSE01_E_060 CSE01_E_061 CSE01_E_062 CSE01_E_063;
SIG_GROUP_ 32 GR_BIW_STATES 1 : BIW_v_States32 BIW_v_EEPROM_Status BIW_v_EEPROM_Steps BIW_v_States;
SIG_GROUP_ 555 GR_SAC_ERRORS_2 1 : SAC_E_ACC_Emergency_Test SAC_E_ADC SAC_E_BSC_Operation_10D SAC_E_BSC_Operation_9D23H SAC_E_CELL_OVERVOLT_WARN SAC_E_CELL_UNDERVOLT_WARN SAC_E_crash SAC_E_CSC_DS_Interop SAC_E_CSC_Emergency_Test SAC_E_CSC_Interop SAC_E_CSC_Limits SAC_E_Dataset SAC_E_Dataset_Conf SAC_E_Interlock_Test SAC_E_Internal SAC_E_ISO_SHORT SAC_E_KL30c_Test SAC_E_MC_WD SAC_E_MSW_3_control SAC_E_MSW_3_stuck SAC_E_MSW_minus_control SAC_E_MSW_minus_stuck SAC_E_MSW_plus_control SAC_E_MSW_plus_stuck SAC_E_MSW_stuck_Test SAC_E_PMB_DS_Interop SAC_E_PMB_Emergency_Test SAC_E_PMB_Interop SAC_E_PMB_OVERCURRENT_PRECH SAC_E_Precharge1_diag SAC_E_Precharge1_power SAC_E_Precharge2_diag SAC_E_Precharge2_power SAC_E_RTC SAC_E_SPI_COM SAC_E_SSV_Alive_Test SAC_E_SSV_DS_Interop SAC_E_SSV_Ref_Voltage SAC_E_SSV_Startup_Test SAC_E_SSV_Sys_WD_Test SAC_E_Startup_Test SAC_E_Task_System SAC_E_Timer_Management;
